VERSION "dbc-export 1 2026.26.6.5"

NS_ :

BS_:

BU_: ADSP APB APP APS APSB BB BMS CC CMP CMPD CP DAS DI DIF DIR DPB EPAS3P EPAS3S EPASTP EPASTS EPBL EPBR ESP EVSE FC GTW HCML HCMR HVP IBST ICR IDB LS OCS1P PARK PCS PCS2 PM PMF PMR PNCD PTC RADC RCM RCM2 RCM3 RCU SCCM SCM SCS SDCR TAS TCU TCU2 TPMS TRCM UI UIS UMC USM V2G VC VCBATT VCBATT0 VCBATT1 VCBATT2 VCCC VCFRONT VCFRONT1 VCFRONT2 VCLEFT VCRIGHT VCSEAT2L VCSEAT2R VCSEC VEH

BO_ 861 IBST_alertMatrix: 8 IBST
 SG_ IBST_matrixIndex M : 0|4@1+ (1,0) [0|15] "" Vector__XXX
 SG_ IBST_a001_microSupplyError m0 : 4|1@1+ (1,0) [0|1] "" Vector__XXX
 SG_ IBST_a002_HWBISTError m0 : 5|1@1+ (1,0) [0|1] "" Vector__XXX
 SG_ IBST_a003_RAMFault m0 : 6|1@1+ (1,0) [0|1] "" Vector__XXX
 SG_ IBST_a004_flashFault m0 : 7|1@1+ (1,0) [0|1] "" Vector__XXX
 SG_ IBST_a005_microSafetyFault m0 : 8|1@1+ (1,0) [0|1] "" Vector__XXX
 SG_ IBST_a006_microSafetyLogicFault m0 : 9|1@1+ (1,0) [0|1] "" Vector__XXX
 SG_ IBST_a007_RBCPUException m0 : 10|1@1+ (1,0) [0|1] "" Vector__XXX
 SG_ IBST_a008_stackOverUnderFlow m0 : 11|1@1+ (1,0) [0|1] "" Vector__XXX
 SG_ IBST_a009_systemErrorHook m0 : 12|1@1+ (1,0) [0|1] "" Vector__XXX
 SG_ IBST_a010_OSErrorHook m0 : 13|1@1+ (1,0) [0|1] "" Vector__XXX
 SG_ IBST_a011_systemTaskOverRun m0 : 14|1@1+ (1,0) [0|1] "" Vector__XXX
 SG_ IBST_a012_OSTaskSchemeError m0 : 15|1@1+ (1,0) [0|1] "" Vector__XXX
 SG_ IBST_a013_systemTaskJitter m0 : 16|1@1+ (1,0) [0|1] "" Vector__XXX
 SG_ IBST_a014_DMATransferError m0 : 17|1@1+ (1,0) [0|1] "" Vector__XXX
 SG_ IBST_a015_asicOscillatorError m0 : 18|1@1+ (1,0) [0|1] "" Vector__XXX
 SG_ IBST_a016_RBBLMShaftShiftError m0 : 19|1@1+ (1,0) [0|1] "" Vector__XXX
 SG_ IBST_a017_assertionFault m0 : 20|1@1+ (1,0) [0|1] "" Vector__XXX
 SG_ IBST_a018_unsupportedHW m0 : 21|1@1+ (1,0) [0|1] "" Vector__XXX
 SG_ IBST_a019_supplyASICInitFault m0 : 22|1@1+ (1,0) [0|1] "" Vector__XXX
 SG_ IBST_a020_VPREU5VOutOfRange m0 : 23|1@1+ (1,0) [0|1] "" Vector__XXX
 SG_ IBST_a021_IREFOutOfRange m0 : 24|1@1+ (1,0) [0|1] "" Vector__XXX
 SG_ IBST_a022_U5VTestFault m0 : 25|1@1+ (1,0) [0|1] "" Vector__XXX
 SG_ IBST_a023_U5VOutOfRange m0 : 26|1@1+ (1,0) [0|1] "" Vector__XXX
 SG_ IBST_a024_chargePumpFault m0 : 27|1@1+ (1,0) [0|1] "" Vector__XXX
 SG_ IBST_a025_ecuClockTestFault m0 : 28|1@1+ (1,0) [0|1] "" Vector__XXX
 SG_ IBST_a026_ecuBistCmdTestFault m0 : 29|1@1+ (1,0) [0|1] "" Vector__XXX
 SG_ IBST_a027_ecuFastWdTestFault m0 : 30|1@1+ (1,0) [0|1] "" Vector__XXX
 SG_ IBST_a028_ecuBistFaultCtrFault m0 : 31|1@1+ (1,0) [0|1] "" Vector__XXX
 SG_ IBST_a029_ecuErrpinCounterFault m0 : 32|1@1+ (1,0) [0|1] "" Vector__XXX
 SG_ IBST_a030_ecuEnableElLowFault m0 : 33|1@1+ (1,0) [0|1] "" Vector__XXX
 SG_ IBST_a031_decoupleBitTestFault m0 : 34|1@1+ (1,0) [0|1] "" Vector__XXX
 SG_ IBST_a032_ecuEnableElHighFault m0 : 35|1@1+ (1,0) [0|1] "" Vector__XXX
 SG_ IBST_a033_ecuWdStartuptestFault m0 : 36|1@1+ (1,0) [0|1] "" Vector__XXX
 SG_ IBST_a034_ecuEnableHyHighFault m0 : 37|1@1+ (1,0) [0|1] "" Vector__XXX
 SG_ IBST_a035_ecuEnableHyLowFault m0 : 38|1@1+ (1,0) [0|1] "" Vector__XXX
 SG_ IBST_a036_MRGPathTestFault m0 : 39|1@1+ (1,0) [0|1] "" Vector__XXX
 SG_ IBST_a037_ecuWdSContinuousError m0 : 40|1@1+ (1,0) [0|1] "" Vector__XXX
 SG_ IBST_a038_ecuEnContinuousError m0 : 41|1@1+ (1,0) [0|1] "" Vector__XXX
 SG_ IBST_a039_GTMRefFrequencyError m0 : 42|1@1+ (1,0) [0|1] "" Vector__XXX
 SG_ IBST_a040_GTMTbuMonError m0 : 43|1@1+ (1,0) [0|1] "" Vector__XXX
 SG_ IBST_a041_micAsicClkInError m0 : 44|1@1+ (1,0) [0|1] "" Vector__XXX
 SG_ IBST_a042_micAsicInitTestError m0 : 45|1@1+ (1,0) [0|1] "" Vector__XXX
 SG_ IBST_a043_micSpiTransferError m0 : 46|1@1+ (1,0) [0|1] "" Vector__XXX
 SG_ IBST_a044_NvMEepromWIP m0 : 47|1@1+ (1,0) [0|1] "" Vector__XXX
 SG_ IBST_a045_WdhAsicWdErrorCntStuck m0 : 48|1@1+ (1,0) [0|1] "" Vector__XXX
 SG_ IBST_a046_WdhAsicWdErrorCntLimit m0 : 49|1@1+ (1,0) [0|1] "" Vector__XXX
 SG_ IBST_a047_WdhAsicWdCmdMissing m0 : 50|1@1+ (1,0) [0|1] "" Vector__XXX
 SG_ IBST_a048_WdhSwBistConCnt m0 : 51|1@1+ (1,0) [0|1] "" Vector__XXX
 SG_ IBST_a049_WdhTaskMonConCnt m0 : 52|1@1+ (1,0) [0|1] "" Vector__XXX
 SG_ IBST_a050_VPreExternalFeeding m0 : 53|1@1+ (1,0) [0|1] "" Vector__XXX
 SG_ IBST_a051_ecuBandgap m0 : 54|1@1+ (1,0) [0|1] "" Vector__XXX
 SG_ IBST_a052_AdcPinTest m0 : 55|1@1+ (1,0) [0|1] "" Vector__XXX
 SG_ IBST_a053_AdcSelftestC5P m0 : 56|1@1+ (1,0) [0|1] "" Vector__XXX
 SG_ IBST_a054_AdcPeripheralFault m0 : 57|1@1+ (1,0) [0|1] "" Vector__XXX
 SG_ IBST_a055_UB6SupplyPathFault m0 : 58|1@1+ (1,0) [0|1] "" Vector__XXX
 SG_ IBST_a056_UB6PlausiMonFault m0 : 59|1@1+ (1,0) [0|1] "" Vector__XXX
 SG_ IBST_a057_microRegisterFault m0 : 60|1@1+ (1,0) [0|1] "" Vector__XXX
 SG_ IBST_a058_NvMWriteCycleExceed m0 : 61|1@1+ (1,0) [0|1] "" Vector__XXX
 SG_ IBST_a059_NvMEepromSize m0 : 62|1@1+ (1,0) [0|1] "" Vector__XXX
 SG_ IBST_a060_NvMMigrationFault m0 : 63|1@1+ (1,0) [0|1] "" Vector__XXX
 SG_ IBST_a061_AswSystemTimeOut m1 : 4|1@1+ (1,0) [0|1] "" Vector__XXX
 SG_ IBST_a062_MICB6TransferError m1 : 5|1@1+ (1,0) [0|1] "" Vector__XXX
 SG_ IBST_a063_tempSens2ShortToSupply m1 : 6|1@1+ (1,0) [0|1] "" Vector__XXX
 SG_ IBST_a064_tempSens1ShortToGround m1 : 7|1@1+ (1,0) [0|1] "" Vector__XXX
 SG_ IBST_a065_tempSens2ShortToGround m1 : 8|1@1+ (1,0) [0|1] "" Vector__XXX
 SG_ IBST_a066_tempSens1ShortToSupply m1 : 9|1@1+ (1,0) [0|1] "" Vector__XXX
 SG_ IBST_a067_tempSensImplausVoltage m1 : 10|1@1+ (1,0) [0|1] "" Vector__XXX
 SG_ IBST_a068_chargePumpUndervoltage m1 : 11|1@1+ (1,0) [0|1] "" Vector__XXX
 SG_ IBST_a069_greasingRoutineFault m1 : 12|1@1+ (1,0) [0|1] "" Vector__XXX
 SG_ IBST_a070_notShutDownNvMWrite m1 : 13|1@1+ (1,0) [0|1] "" Vector__XXX
 SG_ IBST_a071_notShutDownNvMRead m1 : 14|1@1+ (1,0) [0|1] "" Vector__XXX
 SG_ IBST_a072_notShutDownRight m1 : 15|1@1+ (1,0) [0|1] "" Vector__XXX
 SG_ IBST_a073_jumpInAdjustNvMRead m1 : 16|1@1+ (1,0) [0|1] "" Vector__XXX
 SG_ IBST_a074_FindIdleDataNvMWrite m1 : 17|1@1+ (1,0) [0|1] "" Vector__XXX
 SG_ IBST_a075_FindIdleRoutineFault m1 : 18|1@1+ (1,0) [0|1] "" Vector__XXX
 SG_ IBST_a076_masterCylLengthRead m1 : 19|1@1+ (1,0) [0|1] "" Vector__XXX
 SG_ IBST_a077_runOutMotorSaturated m1 : 20|1@1+ (1,0) [0|1] "" Vector__XXX
 SG_ IBST_a078_wearOffsetCompNVMRead m1 : 21|1@1+ (1,0) [0|1] "" Vector__XXX
 SG_ IBST_a079_motorTempHighLevel1 m1 : 22|1@1+ (1,0) [0|1] "" Vector__XXX
 SG_ IBST_a080_motorTempHighLevel2 m1 : 23|1@1+ (1,0) [0|1] "" Vector__XXX
 SG_ IBST_a081_travelDeviation m1 : 24|1@1+ (1,0) [0|1] "" Vector__XXX
 SG_ IBST_a082_motorSpeedDeviation m1 : 25|1@1+ (1,0) [0|1] "" Vector__XXX
 SG_ IBST_a083_spindlePositionTooHigh m1 : 26|1@1+ (1,0) [0|1] "" Vector__XXX
 SG_ IBST_a084_CANTransceiverHWFault m1 : 27|1@1+ (1,0) [0|1] "" Vector__XXX
 SG_ IBST_a085_supplyUndervoltageLvl3 m1 : 28|1@1+ (1,0) [0|1] "" Vector__XXX
 SG_ IBST_a086_supplyOvervoltageLvl3 m1 : 29|1@1+ (1,0) [0|1] "" Vector__XXX
 SG_ IBST_a087_rotorSinOutOfRangeLow m1 : 30|1@1+ (1,0) [0|1] "" Vector__XXX
 SG_ IBST_a088_rotorCosOutOfRangeLow m1 : 31|1@1+ (1,0) [0|1] "" Vector__XXX
 SG_ IBST_a089_rotorSinOutOfRangeHigh m1 : 32|1@1+ (1,0) [0|1] "" Vector__XXX
 SG_ IBST_a090_rotorCosOutOfRangeHigh m1 : 33|1@1+ (1,0) [0|1] "" Vector__XXX
 SG_ IBST_a091_SMMOneRequestsInit m1 : 34|1@1+ (1,0) [0|1] "" Vector__XXX
 SG_ IBST_a092_systemStartTimeOut m1 : 35|1@1+ (1,0) [0|1] "" Vector__XXX
 SG_ IBST_a093_UEXSOvertemperature m1 : 36|1@1+ (1,0) [0|1] "" Vector__XXX
 SG_ IBST_a094_XPASSEchoTimeDeviation m1 : 37|1@1+ (1,0) [0|1] "" Vector__XXX
 SG_ IBST_a095_XPASSTimeOut m1 : 38|1@1+ (1,0) [0|1] "" Vector__XXX
 SG_ IBST_a096_bridgeDriverMonError m1 : 39|1@1+ (1,0) [0|1] "" Vector__XXX
 SG_ IBST_a097_bridgeDriverError m1 : 40|1@1+ (1,0) [0|1] "" Vector__XXX
 SG_ IBST_a098_bridgeShortedPhase m1 : 41|1@1+ (1,0) [0|1] "" Vector__XXX
 SG_ IBST_a099_bridgeSwitchInitError m1 : 42|1@1+ (1,0) [0|1] "" Vector__XXX
 SG_ IBST_a100_current2OffsetHigh m1 : 43|1@1+ (1,0) [0|1] "" Vector__XXX
 SG_ IBST_a101_current2OffsetLow m1 : 44|1@1+ (1,0) [0|1] "" Vector__XXX
 SG_ IBST_a102_current1OffsetHigh m1 : 45|1@1+ (1,0) [0|1] "" Vector__XXX
 SG_ IBST_a103_current1OffsetLow m1 : 46|1@1+ (1,0) [0|1] "" Vector__XXX
 SG_ IBST_a104_bridgeDriverShort m1 : 47|1@1+ (1,0) [0|1] "" Vector__XXX
 SG_ IBST_a105_LiPSUndervoltage m1 : 48|1@1+ (1,0) [0|1] "" Vector__XXX
 SG_ IBST_a106_LiPS5VSupply m1 : 49|1@1+ (1,0) [0|1] "" Vector__XXX
 SG_ IBST_a107_LiPS2PwmLineHigh m1 : 50|1@1+ (1,0) [0|1] "" Vector__XXX
 SG_ IBST_a108_LiPS2PwmLineLow m1 : 51|1@1+ (1,0) [0|1] "" Vector__XXX
 SG_ IBST_a109_LiPS2PwmTransmission m1 : 52|1@1+ (1,0) [0|1] "" Vector__XXX
 SG_ IBST_a110_LiPS1SentLineHigh m1 : 53|1@1+ (1,0) [0|1] "" Vector__XXX
 SG_ IBST_a111_LiPS1SentLineLow m1 : 54|1@1+ (1,0) [0|1] "" Vector__XXX
 SG_ IBST_a112_LiPS1SentTransmission m1 : 55|1@1+ (1,0) [0|1] "" Vector__XXX
 SG_ IBST_a113_LiPS1SentSensor m1 : 56|1@1+ (1,0) [0|1] "" Vector__XXX
 SG_ IBST_a114_partyBusOff m1 : 57|1@1+ (1,0) [0|1] "" Vector__XXX
 SG_ IBST_a115_chassisBusOff m1 : 58|1@1+ (1,0) [0|1] "" Vector__XXX
 SG_ IBST_a116_supplyUndervoltageLvl2 m1 : 59|1@1+ (1,0) [0|1] "" Vector__XXX
 SG_ IBST_a117_supplyOvervoltageLvl2 m1 : 60|1@1+ (1,0) [0|1] "" Vector__XXX
 SG_ IBST_a118_RPSNvMReadFault m1 : 61|1@1+ (1,0) [0|1] "" Vector__XXX
 SG_ IBST_a119_RPSWrongCalibData m1 : 62|1@1+ (1,0) [0|1] "" Vector__XXX
 SG_ IBST_a120_RPSVectorRangeHigh m1 : 63|1@1+ (1,0) [0|1] "" Vector__XXX
 SG_ IBST_a121_RPSVectorRangeLow m2 : 4|1@1+ (1,0) [0|1] "" Vector__XXX
 SG_ IBST_a122_RPSVectorOscillating m2 : 5|1@1+ (1,0) [0|1] "" Vector__XXX
 SG_ IBST_a123_bridgeDriverUnavail m2 : 6|1@1+ (1,0) [0|1] "" Vector__XXX
 SG_ IBST_a124_OBDCurrent1OORHigh m2 : 7|1@1+ (1,0) [0|1] "" Vector__XXX
 SG_ IBST_a125_OBDCurrent2OORHigh m2 : 8|1@1+ (1,0) [0|1] "" Vector__XXX
 SG_ IBST_a126_OBDCurrent1OORLow m2 : 9|1@1+ (1,0) [0|1] "" Vector__XXX
 SG_ IBST_a127_OBDCurrent2OORLow m2 : 10|1@1+ (1,0) [0|1] "" Vector__XXX
 SG_ IBST_a128_BLMMuxerTimeoutError m2 : 11|1@1+ (1,0) [0|1] "" Vector__XXX
 SG_ IBST_a129_loadDumpOnFSLTest m2 : 12|1@1+ (1,0) [0|1] "" Vector__XXX
 SG_ IBST_a130_DTSFunctionalRangeLow m2 : 13|1@1+ (1,0) [0|1] "" Vector__XXX
 SG_ IBST_a131_DTSFunctionalRangeHigh m2 : 14|1@1+ (1,0) [0|1] "" Vector__XXX
 SG_ IBST_a132_DTSPlausiCheck1vs2 m2 : 15|1@1+ (1,0) [0|1] "" Vector__XXX
 SG_ IBST_a133_DTSOffsetTooLow m2 : 16|1@1+ (1,0) [0|1] "" Vector__XXX
 SG_ IBST_a134_DTSOffsetTooHigh m2 : 17|1@1+ (1,0) [0|1] "" Vector__XXX
 SG_ IBST_a135_ESPparty1DLC m2 : 18|1@1+ (1,0) [0|1] "" Vector__XXX
 SG_ IBST_a136_ESPparty1Timeout m2 : 19|1@1+ (1,0) [0|1] "" Vector__XXX
 SG_ IBST_a137_ESPparty1Checksum m2 : 20|1@1+ (1,0) [0|1] "" Vector__XXX
 SG_ IBST_a138_ESPparty1Counter m2 : 21|1@1+ (1,0) [0|1] "" Vector__XXX
 SG_ IBST_a139_ESPparty2DLC m2 : 22|1@1+ (1,0) [0|1] "" Vector__XXX
 SG_ IBST_a140_ESPparty2Timeout m2 : 23|1@1+ (1,0) [0|1] "" Vector__XXX
 SG_ IBST_a141_ESPparty2Checksum m2 : 24|1@1+ (1,0) [0|1] "" Vector__XXX
 SG_ IBST_a142_ESPparty2Counter m2 : 25|1@1+ (1,0) [0|1] "" Vector__XXX
 SG_ IBST_a143_ESPparty3DLC m2 : 26|1@1+ (1,0) [0|1] "" Vector__XXX
 SG_ IBST_a144_ESPparty3Timeout m2 : 27|1@1+ (1,0) [0|1] "" Vector__XXX
 SG_ IBST_a145_ESPparty3Checksum m2 : 28|1@1+ (1,0) [0|1] "" Vector__XXX
 SG_ IBST_a146_ESPparty3Counter m2 : 29|1@1+ (1,0) [0|1] "" Vector__XXX
 SG_ IBST_a147_PSCMotorSizeReadFault m2 : 30|1@1+ (1,0) [0|1] "" Vector__XXX
 SG_ IBST_a148_MLIGainMechReadFault m2 : 31|1@1+ (1,0) [0|1] "" Vector__XXX
 SG_ IBST_a149_MLITMCAreaReadFault m2 : 32|1@1+ (1,0) [0|1] "" Vector__XXX
 SG_ IBST_a150_motorTestFault m2 : 33|1@1+ (1,0) [0|1] "" Vector__XXX
 SG_ IBST_a151_PSCGearRatioReadFault m2 : 34|1@1+ (1,0) [0|1] "" Vector__XXX
 SG_ IBST_a152_PSCVoltageImplausible m2 : 35|1@1+ (1,0) [0|1] "" Vector__XXX
 SG_ IBST_a153_unused m2 : 36|1@1+ (1,0) [0|1] "" Vector__XXX
 SG_ IBST_a154_unused m2 : 37|1@1+ (1,0) [0|1] "" Vector__XXX
 SG_ IBST_a155_supplyUndervoltageLvl1 m2 : 38|1@1+ (1,0) [0|1] "" Vector__XXX
 SG_ IBST_a156_supplyOvervoltageLvl1 m2 : 39|1@1+ (1,0) [0|1] "" Vector__XXX
 SG_ IBST_a157_masterCylPressInvalid m2 : 40|1@1+ (1,0) [0|1] "" Vector__XXX
 SG_ IBST_a158_DTSOffsHighSuspicious m2 : 41|1@1+ (1,0) [0|1] "" Vector__XXX
 SG_ IBST_a159_FindIdleNvMReadError m2 : 42|1@1+ (1,0) [0|1] "" Vector__XXX
 SG_ IBST_a160_DTSIDTimeOut m2 : 43|1@1+ (1,0) [0|1] "" Vector__XXX
 SG_ IBST_a161_powerPackMismatch m2 : 44|1@1+ (1,0) [0|1] "" Vector__XXX
 SG_ IBST_a162_idlePosNotDetected m2 : 45|1@1+ (1,0) [0|1] "" Vector__XXX
 SG_ IBST_a163_ESPpEstMaxInvalid m2 : 46|1@1+ (1,0) [0|1] "" Vector__XXX
 SG_ IBST_a164_ESPVehicleSpeedInvalid m2 : 47|1@1+ (1,0) [0|1] "" Vector__XXX
 SG_ IBST_a165_ESPpForceBlendInvalid m2 : 48|1@1+ (1,0) [0|1] "" Vector__XXX
 SG_ IBST_a166_ESPpMcVirtualInvalid m2 : 49|1@1+ (1,0) [0|1] "" Vector__XXX
 SG_ IBST_a167_ESPqTargetExterInvalid m2 : 50|1@1+ (1,0) [0|1] "" Vector__XXX
 SG_ IBST_a168_CANOvervoltage m2 : 51|1@1+ (1,0) [0|1] "" Vector__XXX
 SG_ IBST_a169_CANUndervoltage m2 : 52|1@1+ (1,0) [0|1] "" Vector__XXX
 SG_ IBST_a170_LVPowerStateTimeout m2 : 53|1@1+ (1,0) [0|1] "" Vector__XXX
 SG_ IBST_a171_LVPowerStateChecksum m2 : 54|1@1+ (1,0) [0|1] "" Vector__XXX
 SG_ IBST_a172_LVPowerStateDLC m2 : 55|1@1+ (1,0) [0|1] "" Vector__XXX
 SG_ IBST_a173_LVPowerStateCounter m2 : 56|1@1+ (1,0) [0|1] "" Vector__XXX
 SG_ IBST_a174_LVOffStateInvalid m2 : 57|1@1+ (1,0) [0|1] "" Vector__XXX
 SG_ IBST_a175_LVGoingDownInvalid m2 : 58|1@1+ (1,0) [0|1] "" Vector__XXX
 SG_ IBST_a176_blockedPedalDetected m2 : 59|1@1+ (1,0) [0|1] "" Vector__XXX
 SG_ IBST_a177_EPBLsystemStatusMIA m2 : 60|1@1+ (1,0) [0|1] "" Vector__XXX
 SG_ IBST_a178_EPBRsystemStatusMIA m2 : 61|1@1+ (1,0) [0|1] "" Vector__XXX
 SG_ IBST_a179_VCLEFTepbmStatusMIA m2 : 62|1@1+ (1,0) [0|1] "" Vector__XXX
 SG_ IBST_a180_VCRIGHTepbmStatusMIA m2 : 63|1@1+ (1,0) [0|1] "" Vector__XXX
 SG_ IBST_a181_DIchassisControlDLC m3 : 4|1@1+ (1,0) [0|1] "" Vector__XXX
 SG_ IBST_a182_DIchassisControlTimeou m3 : 5|1@1+ (1,0) [0|1] "" Vector__XXX
 SG_ IBST_a183_DIchassisControlChecks m3 : 6|1@1+ (1,0) [0|1] "" Vector__XXX
 SG_ IBST_a184_DIchassisControlCounte m3 : 7|1@1+ (1,0) [0|1] "" Vector__XXX
 SG_ IBST_a185_rightBusOff m3 : 8|1@1+ (1,0) [0|1] "" Vector__XXX
 SG_ IBST_a186_rightBusPassive m3 : 9|1@1+ (1,0) [0|1] "" Vector__XXX
 SG_ IBST_a187_brakeBusOff m3 : 10|1@1+ (1,0) [0|1] "" Vector__XXX
 SG_ IBST_a188_brakeBusPassive m3 : 11|1@1+ (1,0) [0|1] "" Vector__XXX
 SG_ IBST_a189_rightVCLVPowerStateTim m3 : 12|1@1+ (1,0) [0|1] "" Vector__XXX
 SG_ IBST_a190_rightVCLVPowerStateDLC m3 : 13|1@1+ (1,0) [0|1] "" Vector__XXX
 SG_ IBST_a191_rightVCLVPowerStateChe m3 : 14|1@1+ (1,0) [0|1] "" Vector__XXX
 SG_ IBST_a192_rightVCLVPowerStateCou m3 : 15|1@1+ (1,0) [0|1] "" Vector__XXX
 SG_ IBST_a193_leftVCLVPowerStateTime m3 : 16|1@1+ (1,0) [0|1] "" Vector__XXX
 SG_ IBST_a194_leftVCLVPowerStateChec m3 : 17|1@1+ (1,0) [0|1] "" Vector__XXX
 SG_ IBST_a195_leftVCLVPowerStateDLC m3 : 18|1@1+ (1,0) [0|1] "" Vector__XXX
 SG_ IBST_a196_leftVCLVPowerStateCoun m3 : 19|1@1+ (1,0) [0|1] "" Vector__XXX
 SG_ IBST_a197_brakeLatencyReductionA m3 : 20|1@1+ (1,0) [0|1] "" Vector__XXX
 SG_ IBST_a198_aesActive m3 : 21|1@1+ (1,0) [0|1] "" Vector__XXX
 SG_ IBST_a199_undefinedAlertDetected m3 : 22|1@1+ (1,0) [0|1] "" Vector__XXX
 SG_ IBST_a200_aesFault m3 : 23|1@1+ (1,0) [0|1] "" Vector__XXX
 SG_ IBST_a201_EGGREAR1wheelSpeedsRea m3 : 24|1@1+ (1,0) [0|1] "" Vector__XXX
 SG_ IBST_a202_EGGREAR1wheelSpeedsRea m3 : 25|1@1+ (1,0) [0|1] "" Vector__XXX
 SG_ IBST_a203_EGGREAR1wheelSpeedsRea m3 : 26|1@1+ (1,0) [0|1] "" Vector__XXX
 SG_ IBST_a204_EGGREAR1wheelSpeedsRea m3 : 27|1@1+ (1,0) [0|1] "" Vector__XXX
 SG_ IBST_a205_EGGRIGHT1wheelSpeedsFr m3 : 28|1@1+ (1,0) [0|1] "" Vector__XXX
 SG_ IBST_a206_EGGRIGHT1wheelSpeedsFr m3 : 29|1@1+ (1,0) [0|1] "" Vector__XXX
 SG_ IBST_a207_EGGRIGHT1wheelSpeedsFr m3 : 30|1@1+ (1,0) [0|1] "" Vector__XXX
 SG_ IBST_a208_EGGRIGHT1wheelSpeedsFr m3 : 31|1@1+ (1,0) [0|1] "" Vector__XXX
 SG_ IBST_a209_reducedBrakePowerActiv m3 : 32|1@1+ (1,0) [0|1] "" Vector__XXX
 SG_ IBST_a210_reducedBrakePowerNotAv m3 : 33|1@1+ (1,0) [0|1] "" Vector__XXX
 SG_ IBST_a211_DETReportError m3 : 34|1@1+ (1,0) [0|1] "" Vector__XXX
 SG_ IBST_a212_infoFailureWrongCUBASH m3 : 35|1@1+ (1,0) [0|1] "" Vector__XXX
 SG_ IBST_a213_PDURouterinitializatio m3 : 36|1@1+ (1,0) [0|1] "" Vector__XXX
 SG_ IBST_a214_LossOfPDUInstanceDetec m3 : 37|1@1+ (1,0) [0|1] "" Vector__XXX
 SG_ IBST_a215_UnsupportedSeriesHWDet m3 : 38|1@1+ (1,0) [0|1] "" Vector__XXX
 SG_ IBST_a216_AsicMalfunctionDetecte m3 : 39|1@1+ (1,0) [0|1] "" Vector__XXX
 SG_ IBST_a217_AsicTrimmingNotComplet m3 : 40|1@1+ (1,0) [0|1] "" Vector__XXX
 SG_ IBST_a218_uCSafetyNotificationGR m3 : 41|1@1+ (1,0) [0|1] "" Vector__XXX
 SG_ IBST_a219_uCSafetyNotification m3 : 42|1@1+ (1,0) [0|1] "" Vector__XXX
 SG_ IBST_a220_ASICOvercurrentOnGPIO2 m3 : 43|1@1+ (1,0) [0|1] "" Vector__XXX
 SG_ IBST_a221_ASICOvercurrentOnGPIO2 m3 : 44|1@1+ (1,0) [0|1] "" Vector__XXX
 SG_ IBST_a222_ASICOvercurrentOnGPIO5 m3 : 45|1@1+ (1,0) [0|1] "" Vector__XXX
 SG_ IBST_a223_ASICOvercurrentOnGPIO5 m3 : 46|1@1+ (1,0) [0|1] "" Vector__XXX
 SG_ IBST_a224_ASICOvercurrentOnGPIO5 m3 : 47|1@1+ (1,0) [0|1] "" Vector__XXX
 SG_ IBST_a225_ASICOvercurrentOnGPIO5 m3 : 48|1@1+ (1,0) [0|1] "" Vector__XXX
 SG_ IBST_a226_ASICOvercurrentOnWRHS m3 : 49|1@1+ (1,0) [0|1] "" Vector__XXX
 SG_ IBST_a227_wakeRequestMismatchDet m3 : 50|1@1+ (1,0) [0|1] "" Vector__XXX
 SG_ IBST_a228_BlockedPedalDetectedDu m3 : 51|1@1+ (1,0) [0|1] "" Vector__XXX
 SG_ IBST_a229_BlockedPedalDetected m3 : 52|1@1+ (1,0) [0|1] "" Vector__XXX
 SG_ IBST_a230_DTS2FunctionalRangeLow m3 : 53|1@1+ (1,0) [0|1] "" Vector__XXX
 SG_ IBST_a231_DTS2FunctionalRangeLow m3 : 54|1@1+ (1,0) [0|1] "" Vector__XXX
 SG_ IBST_a232_PostAssemblyRoutineFai m3 : 55|1@1+ (1,0) [0|1] "" Vector__XXX
 SG_ IBST_a233_ReferenceRunAbortByECU m3 : 56|1@1+ (1,0) [0|1] "" Vector__XXX
 SG_ IBST_a234_LiPSOutOfRangeHigh m3 : 57|1@1+ (1,0) [0|1] "" Vector__XXX
 SG_ IBST_a235_LiPSOutOfRangeLow m3 : 58|1@1+ (1,0) [0|1] "" Vector__XXX
 SG_ IBST_a246_DASredundantBrakingCon m4 : 9|1@1+ (1,0) [0|1] "" Vector__XXX
 SG_ IBST_a247_DASredundantBrakingCon m4 : 10|1@1+ (1,0) [0|1] "" Vector__XXX
 SG_ IBST_a248_DASredundantBrakingCon m4 : 11|1@1+ (1,0) [0|1] "" Vector__XXX
 SG_ IBST_a249_DASredundantBrakingCon m4 : 12|1@1+ (1,0) [0|1] "" Vector__XXX
 SG_ IBST_a250_DASredundantBrakingCon m4 : 13|1@1+ (1,0) [0|1] "" Vector__XXX
 SG_ IBST_a251_DASredundantBrakingCon m4 : 14|1@1+ (1,0) [0|1] "" Vector__XXX
 SG_ IBST_a252_DASredundantBrakingCon m4 : 15|1@1+ (1,0) [0|1] "" Vector__XXX
 SG_ IBST_a253_DASredundantBrakingCon m4 : 16|1@1+ (1,0) [0|1] "" Vector__XXX
 SG_ IBST_a254_DIlocStatus2Checksum m4 : 17|1@1+ (1,0) [0|1] "" Vector__XXX
 SG_ IBST_a255_DIlocStatus2Counter m4 : 18|1@1+ (1,0) [0|1] "" Vector__XXX
 SG_ IBST_a256_DIlocStatus2DLC m4 : 19|1@1+ (1,0) [0|1] "" Vector__XXX
 SG_ IBST_a257_DIlocStatus2Timeout m4 : 20|1@1+ (1,0) [0|1] "" Vector__XXX
 SG_ IBST_a258_standaloneEBRActive m4 : 21|1@1+ (1,0) [0|1] "" Vector__XXX
 SG_ IBST_a259_EMCMain11Checksum m4 : 22|1@1+ (1,0) [0|1] "" Vector__XXX
 SG_ IBST_a260_EMCMain11Counter m4 : 23|1@1+ (1,0) [0|1] "" Vector__XXX
 SG_ IBST_a261_EMCMain11DLC m4 : 24|1@1+ (1,0) [0|1] "" Vector__XXX
 SG_ IBST_a262_EMCMain11Timeout m4 : 25|1@1+ (1,0) [0|1] "" Vector__XXX
 SG_ IBST_a263_EMCMain21Checksum m4 : 26|1@1+ (1,0) [0|1] "" Vector__XXX
 SG_ IBST_a264_EMCMain21Counter m4 : 27|1@1+ (1,0) [0|1] "" Vector__XXX
 SG_ IBST_a265_EMCMain21DLC m4 : 28|1@1+ (1,0) [0|1] "" Vector__XXX
 SG_ IBST_a266_EMCMain21Timeout m4 : 29|1@1+ (1,0) [0|1] "" Vector__XXX

BO_ 813 IBST_info: 8 IBST
 SG_ IBST_infoIndex M : 0|8@1+ (1,0) [0|255] "" Vector__XXX
 SG_ IBST_infoBuildType m10 : 8|8@1+ (1,0) [0|255] "" Vector__XXX
 SG_ IBST_infoComponentID m10 : 55|16@0+ (1,0) [0|65535] "" Vector__XXX
 SG_ IBST_infoPcbaID m11 : 16|8@1+ (1,0) [0|255] "" Vector__XXX
 SG_ IBST_infoAssemblyID m11 : 24|8@1+ (1,0) [0|255] "" Vector__XXX
 SG_ IBST_infoUsageID m11 : 32|16@1+ (1,0) [0|65535] "" Vector__XXX
 SG_ IBST_infoSubUsageID m11 : 48|16@1+ (1,0) [0|65535] "" Vector__XXX
 SG_ IBST_infoApplicationCRC m13 : 32|32@1+ (1,0) [0|4294967295] "" Vector__XXX
 SG_ IBST_infoBootUdsProtoVersion m20 : 8|8@1+ (1,0) [0|255] "" Vector__XXX
 SG_ IBST_infoBootloaderCRC m20 : 32|32@1+ (1,0) [0|4294967295] "" Vector__XXX
 SG_ IBST_infoVariantCRC m22 : 32|32@1+ (1,0) [0|4294967295] "" Vector__XXX

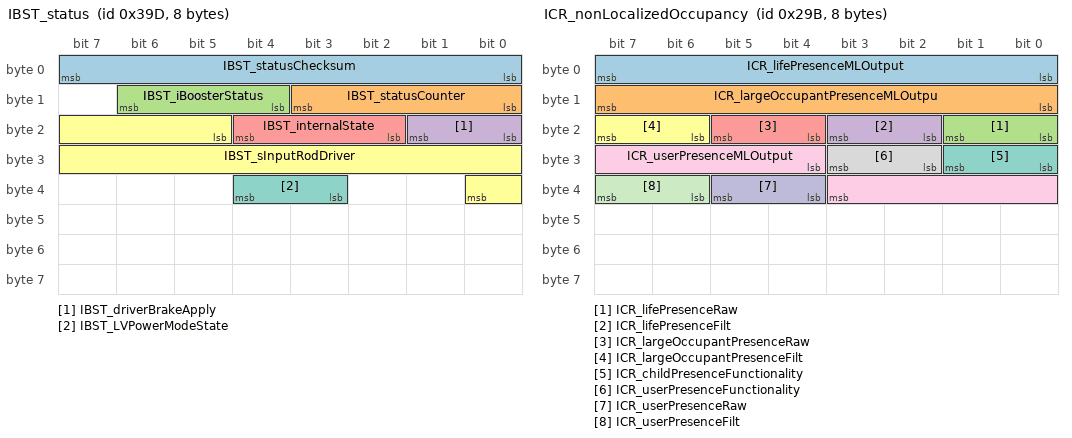
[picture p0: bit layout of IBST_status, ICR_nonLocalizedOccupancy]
BO_ 925 IBST_status: 8 IBST
 SG_ IBST_statusChecksum : 0|8@1+ (1,0) [0|255] "" Vector__XXX
 SG_ IBST_statusCounter : 8|4@1+ (1,0) [0|15] "" Vector__XXX
 SG_ IBST_iBoosterStatus : 12|3@1+ (1,0) [0|7] "" Vector__XXX
 SG_ IBST_driverBrakeApply : 16|2@1+ (1,0) [0|3] "" Vector__XXX
 SG_ IBST_internalState : 18|3@1+ (1,0) [0|7] "" Vector__XXX
 SG_ IBST_sInputRodDriver : 21|12@1+ (0.015625,-5) [-5|47] "mm" Vector__XXX
 SG_ IBST_LVPowerModeState : 35|2@1+ (1,0) [0|3] "" Vector__XXX

BO_ 1208 ICR_alertLog: 8 ICR
 SG_ ICR_alertID M : 0|8@1+ (1,0) [0|255] "" Vector__XXX
 SG_ ICR_alertState : 15|1@1+ (1,0) [0|1] "" Vector__XXX
 SG_ ICR_a001_watchdogTaskAppDPM m1 : 16|1@1+ (1,0) [0|1] "" Vector__XXX
 SG_ ICR_a001_watchdogTaskMMWControl m1 : 17|1@1+ (1,0) [0|1] "" Vector__XXX
 SG_ ICR_a001_watchdogTaskSentinelInt m1 : 18|1@1+ (1,0) [0|1] "" Vector__XXX
 SG_ ICR_a001_watchdogTaskSentinelMod m1 : 19|1@1+ (1,0) [0|1] "" Vector__XXX
 SG_ ICR_a001_watchdogTaskComTXRAD m1 : 20|1@1+ (1,0) [0|1] "" Vector__XXX
 SG_ ICR_a001_watchdogTaskComRX m1 : 21|1@1+ (1,0) [0|1] "" Vector__XXX
 SG_ ICR_a001_watchdogTaskComTXVEH m1 : 22|1@1+ (1,0) [0|1] "" Vector__XXX
 SG_ ICR_a001_watchdogTaskComUDS m1 : 23|1@1+ (1,0) [0|1] "" Vector__XXX
 SG_ ICR_a001_watchdogTaskCommonError m1 : 24|1@1+ (1,0) [0|1] "" Vector__XXX
 SG_ ICR_a001_watchdogTaskUARTLog m1 : 25|1@1+ (1,0) [0|1] "" Vector__XXX
 SG_ ICR_a001_watchdogTaskDataDump m1 : 26|1@1+ (1,0) [0|1] "" Vector__XXX
 SG_ ICR_a001_watchdogRTOSAppRun10MS m1 : 27|1@1+ (1,0) [0|1] "" Vector__XXX
 SG_ ICR_a001_watchdogRTOSAppRun1MS m1 : 28|1@1+ (1,0) [0|1] "" Vector__XXX
 SG_ ICR_a001_InternalWatchdog m1 : 29|1@1+ (1,0) [0|1] "" Vector__XXX
 SG_ ICR_a015_NVMMMemOverflow m15 : 16|1@1+ (1,0) [0|1] "" Vector__XXX
 SG_ ICR_a015_NVMMFilesystemError m15 : 17|1@1+ (1,0) [0|1] "" Vector__XXX
 SG_ ICR_a015_NVMMRecordIDError m15 : 18|1@1+ (1,0) [0|1] "" Vector__XXX
 SG_ ICR_a059_voltageDrop m59 : 16|12@1+ (0.005443676,0) [0|22.29185322] "" Vector__XXX
 SG_ ICR_a059_resistanceEstimate m59 : 28|12@1+ (0.00244,0) [0|9.9918] "" Vector__XXX
 SG_ ICR_a059_current m59 : 40|12@1+ (0.05,0) [0|204.75] "" Vector__XXX
 SG_ ICR_a063_switchChannel m63 : 16|8@1+ (1,0) [0|255] "" Vector__XXX
 SG_ ICR_a063_switchType m63 : 24|8@1+ (1,0) [0|255] "" Vector__XXX
 SG_ ICR_a063_ADCVoltage m63 : 32|8@1+ (0.025,0) [0|6.375] "" Vector__XXX
 SG_ ICR_a063_disconnected m63 : 40|1@1+ (1,0) [0|1] "" Vector__XXX
 SG_ ICR_a063_indeterminate m63 : 41|1@1+ (1,0) [0|1] "" Vector__XXX
 SG_ ICR_a063_stuckActive m63 : 42|1@1+ (1,0) [0|1] "" Vector__XXX
 SG_ ICR_a063_faulted m63 : 43|1@1+ (1,0) [0|1] "" Vector__XXX
 SG_ ICR_a133_nearClutter m133 : 16|8@1- (0.2,0) [-25.6|25.4] "" Vector__XXX
 SG_ ICR_a133_farClutter m133 : 24|8@1- (0.2,0) [-25.6|25.4] "" Vector__XXX
 SG_ ICR_a137_nearClutter m137 : 16|8@1- (0.2,0) [-25.6|25.4] "" Vector__XXX
 SG_ ICR_a137_farClutter m137 : 24|8@1- (0.2,0) [-25.6|25.4] "" Vector__XXX
 SG_ ICR_a139_nearClutter m139 : 16|8@1- (0.2,0) [-25.6|25.4] "" Vector__XXX
 SG_ ICR_a139_farClutter m139 : 24|8@1- (0.2,0) [-25.6|25.4] "" Vector__XXX
 SG_ ICR_a141_pmicQualityExcursion m141 : 16|1@1+ (1,0) [0|1] "" Vector__XXX
 SG_ ICR_a141_calDataNotCalibratedOrP m141 : 17|1@1+ (1,0) [0|1] "" Vector__XXX
 SG_ ICR_a141_calDataValRXPhaseAboveM m141 : 18|1@1+ (1,0) [0|1] "" Vector__XXX
 SG_ ICR_a141_calDataValRXPhaseMissin m141 : 19|1@1+ (1,0) [0|1] "" Vector__XXX
 SG_ ICR_a141_calDataValRangeBiasAbov m141 : 20|1@1+ (1,0) [0|1] "" Vector__XXX

BO_ 2028 ICR_alertMatrix: 8 ICR
 SG_ ICR_matrixIndex M : 0|4@1+ (1,0) [0|15] "" Vector__XXX
 SG_ ICR_a001_WatchdogReset m0 : 4|1@1+ (1,0) [0|1] "" Vector__XXX
 SG_ ICR_a002_PowerLossReset m0 : 5|1@1+ (1,0) [0|1] "" Vector__XXX
 SG_ ICR_a003_SWAssertion m0 : 6|1@1+ (1,0) [0|1] "" Vector__XXX
 SG_ ICR_a005_CANTXError m0 : 8|1@1+ (1,0) [0|1] "" Vector__XXX
 SG_ ICR_a006_CANTX_cyclicError m0 : 9|1@1+ (1,0) [0|1] "" Vector__XXX
 SG_ ICR_a012_CPUReset m0 : 15|1@1+ (1,0) [0|1] "" Vector__XXX
 SG_ ICR_a013_AlertManagerFault m0 : 16|1@1+ (1,0) [0|1] "" Vector__XXX
 SG_ ICR_a015_NVMMError m0 : 18|1@1+ (1,0) [0|1] "" Vector__XXX
 SG_ ICR_a016_NVMMRecordError m0 : 19|1@1+ (1,0) [0|1] "" Vector__XXX
 SG_ ICR_a021_TaskSchedulerError m0 : 24|1@1+ (1,0) [0|1] "" Vector__XXX
 SG_ ICR_a022_TaskInitError m0 : 25|1@1+ (1,0) [0|1] "" Vector__XXX
 SG_ ICR_a029_CoreDump m0 : 32|1@1+ (1,0) [0|1] "" Vector__XXX
 SG_ ICR_a030_ECULogUploadRequest m0 : 33|1@1+ (1,0) [0|1] "" Vector__XXX
 SG_ ICR_a031_UDSActive m0 : 34|1@1+ (1,0) [0|1] "" Vector__XXX
 SG_ ICR_a041_HighCPULoad m0 : 44|1@1+ (1,0) [0|1] "" Vector__XXX
 SG_ ICR_a042_HighStackUsage m0 : 45|1@1+ (1,0) [0|1] "" Vector__XXX
 SG_ ICR_a043_Task1msError m0 : 46|1@1+ (1,0) [0|1] "" Vector__XXX
 SG_ ICR_a044_Task10msError m0 : 47|1@1+ (1,0) [0|1] "" Vector__XXX
 SG_ ICR_a045_Task100msError m0 : 48|1@1+ (1,0) [0|1] "" Vector__XXX
 SG_ ICR_a046_Task1000msError m0 : 49|1@1+ (1,0) [0|1] "" Vector__XXX
 SG_ ICR_a058_inputRHighSyncDebug m0 : 61|1@1+ (1,0) [0|1] "" Vector__XXX
 SG_ ICR_a059_inputResistanceHigh m0 : 62|1@1+ (1,0) [0|1] "" Vector__XXX
 SG_ ICR_a060_engineeringBuild m0 : 63|1@1+ (1,0) [0|1] "" Vector__XXX
 SG_ ICR_a061_XCPConnected m1 : 4|1@1+ (1,0) [0|1] "" Vector__XXX
 SG_ ICR_a062_XCPWasConnected m1 : 5|1@1+ (1,0) [0|1] "" Vector__XXX
 SG_ ICR_a063_SwitchFault m1 : 6|1@1+ (1,0) [0|1] "" Vector__XXX
 SG_ ICR_a064_busSleepReqTimeout m1 : 7|1@1+ (1,0) [0|1] "" Vector__XXX
 SG_ ICR_a133_radarBlocked m2 : 16|1@1+ (1,0) [0|1] "" Vector__XXX
 SG_ ICR_a134_radarPgood m2 : 17|1@1+ (1,0) [0|1] "" Vector__XXX
 SG_ ICR_a135_radarTxBallBreak m2 : 18|1@1+ (1,0) [0|1] "" Vector__XXX
 SG_ ICR_a136_radarHighTemperature m2 : 19|1@1+ (1,0) [0|1] "" Vector__XXX
 SG_ ICR_a137_radarBlocked m2 : 20|1@1+ (1,0) [0|1] "" Vector__XXX
 SG_ ICR_a138_DriverSideMismatch m2 : 21|1@1+ (1,0) [0|1] "" Vector__XXX
 SG_ ICR_a139_AbnormalBlockageDetecte m2 : 22|1@1+ (1,0) [0|1] "" Vector__XXX
 SG_ ICR_a140_OccupancyExceptionEncou m2 : 23|1@1+ (1,0) [0|1] "" Vector__XXX
 SG_ ICR_a141_RequiresReplacement m2 : 24|1@1+ (1,0) [0|1] "" Vector__XXX
 SG_ ICR_a142_ModeOverrideActive m2 : 25|1@1+ (1,0) [0|1] "" Vector__XXX
 SG_ ICR_a143_DSPCoreSkipped m2 : 26|1@1+ (1,0) [0|1] "" Vector__XXX
 SG_ ICR_a144_OccupancyNotificationAl m2 : 27|1@1+ (1,0) [0|1] "" Vector__XXX

BO_ 941 ICR_info: 8 ICR
 SG_ ICR_infoIndex M : 0|8@1+ (1,0) [0|255] "" Vector__XXX
 SG_ ICR_infoBuildType m10 : 8|3@1+ (1,0) [0|7] "" Vector__XXX
 SG_ ICR_infoPcbaId m11 : 32|8@1+ (1,0) [0|255] "" Vector__XXX
 SG_ ICR_infoAssemblyId m11 : 40|8@1+ (1,0) [0|255] "" Vector__XXX
 SG_ ICR_infoUsageId m11 : 48|16@1+ (1,0) [0|65535] "" Vector__XXX
 SG_ ICR_infoAppCrc m13 : 8|32@1+ (1,0) [0|4294967295] "" Vector__XXX
 SG_ ICR_infoBoardPartNumber17 m25 : 8|56@1+ (1,0) [0|7.20575940379e+16] "" Vector__XXX
 SG_ ICR_infoBoardPartNumber814 m26 : 8|56@1+ (1,0) [0|7.20575940379e+16] "" Vector__XXX
 SG_ ICR_infoBoardPartNumber1520 m27 : 8|48@1+ (1,0) [0|281474976710655] "" Vector__XXX

BO_ 667 ICR_nonLocalizedOccupancy: 8 ICR
 SG_ ICR_lifePresenceMLOutput : 0|8@1+ (0.004,0) [0|1.016] "points" Vector__XXX
 SG_ ICR_largeOccupantPresenceMLOutpu : 8|8@1+ (0.004,0) [0|1.016] "points" Vector__XXX
 SG_ ICR_lifePresenceRaw : 16|2@1+ (1,0) [0|3] "" Vector__XXX
 SG_ ICR_lifePresenceFilt : 18|2@1+ (1,0) [0|3] "" Vector__XXX
 SG_ ICR_largeOccupantPresenceRaw : 20|2@1+ (1,0) [0|3] "" Vector__XXX
 SG_ ICR_largeOccupantPresenceFilt : 22|2@1+ (1,0) [0|3] "" Vector__XXX
 SG_ ICR_childPresenceFunctionality : 24|2@1+ (1,0) [0|3] "" Vector__XXX
 SG_ ICR_userPresenceFunctionality : 26|2@1+ (1,0) [0|3] "" Vector__XXX
 SG_ ICR_userPresenceMLOutput : 28|8@1+ (0.004,0) [0|1.016] "points" Vector__XXX
 SG_ ICR_userPresenceRaw : 36|2@1+ (1,0) [0|3] "" Vector__XXX
 SG_ ICR_userPresenceFilt : 38|2@1+ (1,0) [0|3] "" Vector__XXX

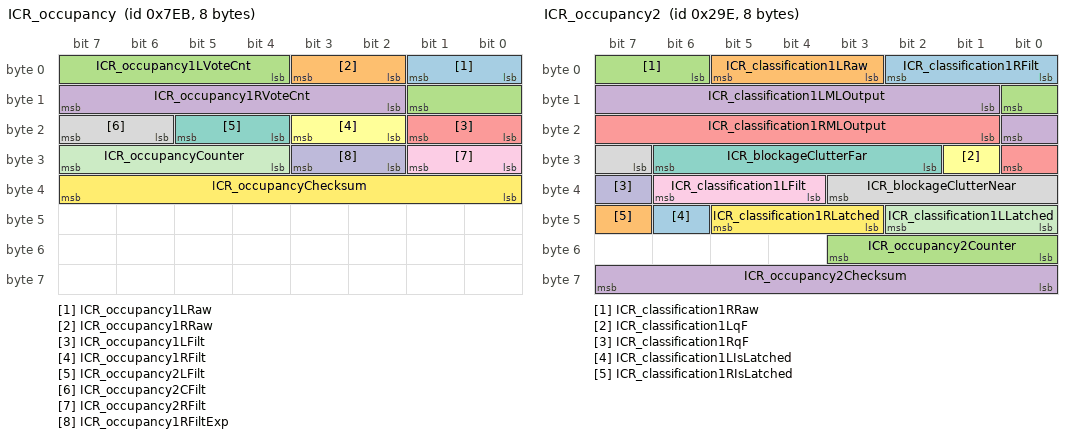
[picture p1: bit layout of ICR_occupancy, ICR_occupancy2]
BO_ 2027 ICR_occupancy: 8 ICR
 SG_ ICR_occupancy1LRaw : 0|2@1+ (1,0) [0|3] "" Vector__XXX
 SG_ ICR_occupancy1RRaw : 2|2@1+ (1,0) [0|3] "" Vector__XXX
 SG_ ICR_occupancy1LVoteCnt : 4|6@1- (1,0) [-32|31] "" Vector__XXX
 SG_ ICR_occupancy1RVoteCnt : 10|6@1- (1,0) [-32|31] "" Vector__XXX
 SG_ ICR_occupancy1LFilt : 16|2@1+ (1,0) [0|3] "" Vector__XXX
 SG_ ICR_occupancy1RFilt : 18|2@1+ (1,0) [0|3] "" Vector__XXX
 SG_ ICR_occupancy2LFilt : 20|2@1+ (1,0) [0|3] "" Vector__XXX
 SG_ ICR_occupancy2CFilt : 22|2@1+ (1,0) [0|3] "" Vector__XXX
 SG_ ICR_occupancy2RFilt : 24|2@1+ (1,0) [0|3] "" Vector__XXX
 SG_ ICR_occupancy1RFiltExp : 26|2@1+ (1,0) [0|3] "" Vector__XXX
 SG_ ICR_occupancyCounter : 28|4@1+ (1,0) [0|15] "" Vector__XXX
 SG_ ICR_occupancyChecksum : 32|8@1+ (1,0) [0|255] "" Vector__XXX

BO_ 670 ICR_occupancy2: 8 ICR
 SG_ ICR_classification1RFilt : 0|3@1+ (1,0) [0|7] "" Vector__XXX
 SG_ ICR_classification1LRaw : 3|3@1+ (1,0) [0|7] "" Vector__XXX
 SG_ ICR_classification1RRaw : 6|3@1+ (1,0) [0|7] "" Vector__XXX
 SG_ ICR_classification1LMLOutput : 9|8@1+ (0.004,0) [0|1.02] "points" Vector__XXX
 SG_ ICR_classification1RMLOutput : 17|8@1+ (0.004,0) [0|1.02] "points" Vector__XXX
 SG_ ICR_classification1LqF : 25|1@1+ (1,0) [0|1] "" Vector__XXX
 SG_ ICR_blockageClutterFar : 26|5@1- (0.5,-1.5) [-9|6] "dB" Vector__XXX
 SG_ ICR_blockageClutterNear : 31|5@1- (0.5,-1.5) [-9|6] "dB" Vector__XXX
 SG_ ICR_classification1LFilt : 36|3@1+ (1,0) [0|7] "" Vector__XXX
 SG_ ICR_classification1RqF : 39|1@1+ (1,0) [0|1] "" Vector__XXX
 SG_ ICR_classification1LLatched : 40|3@1+ (1,0) [0|7] "" Vector__XXX
 SG_ ICR_classification1RLatched : 43|3@1+ (1,0) [0|7] "" Vector__XXX
 SG_ ICR_classification1LIsLatched : 46|1@1+ (1,0) [0|1] "" Vector__XXX
 SG_ ICR_classification1RIsLatched : 47|1@1+ (1,0) [0|1] "" Vector__XXX
 SG_ ICR_occupancy2Counter : 48|4@1+ (1,0) [0|15] "" Vector__XXX
 SG_ ICR_occupancy2Checksum : 56|8@1+ (1,0) [0|255] "" Vector__XXX

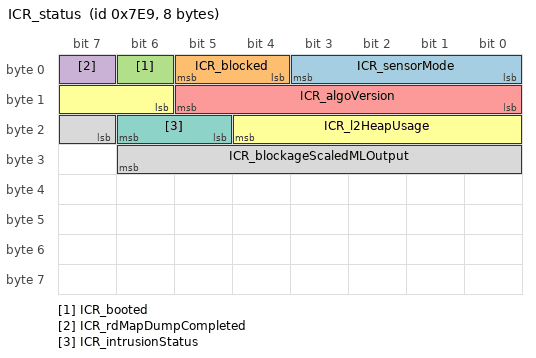
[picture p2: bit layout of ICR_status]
BO_ 2025 ICR_status: 8 ICR
 SG_ ICR_sensorMode : 0|4@1+ (1,0) [0|15] "" Vector__XXX
 SG_ ICR_blocked : 4|2@1+ (1,0) [0|3] "" Vector__XXX
 SG_ ICR_booted : 6|1@1+ (1,0) [0|1] "" Vector__XXX
 SG_ ICR_rdMapDumpCompleted : 7|1@1+ (1,0) [0|1] "" Vector__XXX
 SG_ ICR_algoVersion : 8|6@1+ (1,0) [0|63] "" Vector__XXX
 SG_ ICR_l2HeapUsage : 14|7@1+ (1,0) [0|127] "PCT" Vector__XXX
 SG_ ICR_intrusionStatus : 21|2@1+ (1,0) [0|3] "" Vector__XXX
 SG_ ICR_blockageScaledMLOutput : 23|8@1+ (0.004,0) [0|1.02] "points" Vector__XXX

BO_ 1470 IDB_alertLog: 8 IDB
 SG_ IDB_alertID M : 0|8@1+ (1,0) [0|255] "" Vector__XXX
 SG_ IDB_alertState : 15|1@1+ (1,0) [0|1] "" Vector__XXX
 SG_ IDB_a014_wheelSpeedSensorFreq m14 : 16|1@1+ (1,0) [0|1] "" Vector__XXX
 SG_ IDB_a014_wheelSpeedSensorPhase m14 : 17|1@1+ (1,0) [0|1] "" Vector__XXX
 SG_ IDB_a014_wheelSpeedSensorMisinst m14 : 18|1@1+ (1,0) [0|1] "" Vector__XXX
 SG_ IDB_a014_wheelSpeedSensorWrongEx m14 : 19|1@1+ (1,0) [0|1] "" Vector__XXX
 SG_ IDB_a014_wheelSpeedSensorSpeedJu m14 : 20|1@1+ (1,0) [0|1] "" Vector__XXX
 SG_ IDB_a014_wheelSpeedSensorSp_0001 m14 : 21|1@1+ (1,0) [0|1] "" Vector__XXX
 SG_ IDB_a014_wheelSpeedSensorAirGap m14 : 22|1@1+ (1,0) [0|1] "" Vector__XXX
 SG_ IDB_a014_wheelSpeedSensorBIST m14 : 23|1@1+ (1,0) [0|1] "" Vector__XXX
 SG_ IDB_a014_wheelSpeedSensorLeakage m14 : 24|1@1+ (1,0) [0|1] "" Vector__XXX
 SG_ IDB_a014_wheelSpeedSensorOverTem m14 : 25|1@1+ (1,0) [0|1] "" Vector__XXX
 SG_ IDB_a014_wheelSpeedSensorSh_0001 m14 : 26|1@1+ (1,0) [0|1] "" Vector__XXX
 SG_ IDB_a014_wheelSpeedSensorShortTo m14 : 27|1@1+ (1,0) [0|1] "" Vector__XXX
 SG_ IDB_a014_wheelSpeedSensorOpen m14 : 28|1@1+ (1,0) [0|1] "" Vector__XXX
 SG_ IDB_a015_wheelSpeedSensorFreq m15 : 16|1@1+ (1,0) [0|1] "" Vector__XXX
 SG_ IDB_a015_wheelSpeedSensorPhase m15 : 17|1@1+ (1,0) [0|1] "" Vector__XXX
 SG_ IDB_a015_wheelSpeedSensorMisinst m15 : 18|1@1+ (1,0) [0|1] "" Vector__XXX
 SG_ IDB_a015_wheelSpeedSensorWrongEx m15 : 19|1@1+ (1,0) [0|1] "" Vector__XXX
 SG_ IDB_a015_wheelSpeedSensorSpeedJu m15 : 20|1@1+ (1,0) [0|1] "" Vector__XXX
 SG_ IDB_a015_wheelSpeedSensorSp_0001 m15 : 21|1@1+ (1,0) [0|1] "" Vector__XXX
 SG_ IDB_a015_wheelSpeedSensorAirGap m15 : 22|1@1+ (1,0) [0|1] "" Vector__XXX
 SG_ IDB_a015_wheelSpeedSensorBIST m15 : 23|1@1+ (1,0) [0|1] "" Vector__XXX
 SG_ IDB_a015_wheelSpeedSensorLeakage m15 : 24|1@1+ (1,0) [0|1] "" Vector__XXX
 SG_ IDB_a015_wheelSpeedSensorOverTem m15 : 25|1@1+ (1,0) [0|1] "" Vector__XXX
 SG_ IDB_a015_wheelSpeedSensorSh_0001 m15 : 26|1@1+ (1,0) [0|1] "" Vector__XXX
 SG_ IDB_a015_wheelSpeedSensorShortTo m15 : 27|1@1+ (1,0) [0|1] "" Vector__XXX
 SG_ IDB_a015_wheelSpeedSensorOpen m15 : 28|1@1+ (1,0) [0|1] "" Vector__XXX
 SG_ IDB_a016_wheelSpeedSensorFreq m16 : 16|1@1+ (1,0) [0|1] "" Vector__XXX
 SG_ IDB_a016_wheelSpeedSensorPhase m16 : 17|1@1+ (1,0) [0|1] "" Vector__XXX
 SG_ IDB_a016_wheelSpeedSensorMisinst m16 : 18|1@1+ (1,0) [0|1] "" Vector__XXX
 SG_ IDB_a016_wheelSpeedSensorWrongEx m16 : 19|1@1+ (1,0) [0|1] "" Vector__XXX
 SG_ IDB_a016_wheelSpeedSensorSpeedJu m16 : 20|1@1+ (1,0) [0|1] "" Vector__XXX
 SG_ IDB_a016_wheelSpeedSensorSp_0001 m16 : 21|1@1+ (1,0) [0|1] "" Vector__XXX
 SG_ IDB_a016_wheelSpeedSensorAirGap m16 : 22|1@1+ (1,0) [0|1] "" Vector__XXX
 SG_ IDB_a016_wheelSpeedSensorBIST m16 : 23|1@1+ (1,0) [0|1] "" Vector__XXX
 SG_ IDB_a016_wheelSpeedSensorLeakage m16 : 24|1@1+ (1,0) [0|1] "" Vector__XXX
 SG_ IDB_a016_wheelSpeedSensorOverTem m16 : 25|1@1+ (1,0) [0|1] "" Vector__XXX
 SG_ IDB_a016_wheelSpeedSensorSh_0001 m16 : 26|1@1+ (1,0) [0|1] "" Vector__XXX
 SG_ IDB_a016_wheelSpeedSensorShortTo m16 : 27|1@1+ (1,0) [0|1] "" Vector__XXX
 SG_ IDB_a016_wheelSpeedSensorOpen m16 : 28|1@1+ (1,0) [0|1] "" Vector__XXX
 SG_ IDB_a017_wheelSpeedSensorFreq m17 : 16|1@1+ (1,0) [0|1] "" Vector__XXX
 SG_ IDB_a017_wheelSpeedSensorPhase m17 : 17|1@1+ (1,0) [0|1] "" Vector__XXX
 SG_ IDB_a017_wheelSpeedSensorMisinst m17 : 18|1@1+ (1,0) [0|1] "" Vector__XXX
 SG_ IDB_a017_wheelSpeedSensorWrongEx m17 : 19|1@1+ (1,0) [0|1] "" Vector__XXX
 SG_ IDB_a017_wheelSpeedSensorSpeedJu m17 : 20|1@1+ (1,0) [0|1] "" Vector__XXX
 SG_ IDB_a017_wheelSpeedSensorSp_0001 m17 : 21|1@1+ (1,0) [0|1] "" Vector__XXX
 SG_ IDB_a017_wheelSpeedSensorAirGap m17 : 22|1@1+ (1,0) [0|1] "" Vector__XXX
 SG_ IDB_a017_wheelSpeedSensorBIST m17 : 23|1@1+ (1,0) [0|1] "" Vector__XXX
 SG_ IDB_a017_wheelSpeedSensorLeakage m17 : 24|1@1+ (1,0) [0|1] "" Vector__XXX
 SG_ IDB_a017_wheelSpeedSensorOverTem m17 : 25|1@1+ (1,0) [0|1] "" Vector__XXX
 SG_ IDB_a017_wheelSpeedSensorSh_0001 m17 : 26|1@1+ (1,0) [0|1] "" Vector__XXX
 SG_ IDB_a017_wheelSpeedSensorShortTo m17 : 27|1@1+ (1,0) [0|1] "" Vector__XXX
 SG_ IDB_a017_wheelSpeedSensorOpen m17 : 28|1@1+ (1,0) [0|1] "" Vector__XXX
 SG_ IDB_a020_canSignalValidity m20 : 16|1@1+ (1,0) [0|1] "" Vector__XXX
 SG_ IDB_a020_signalValueCrosscheck m20 : 17|1@1+ (1,0) [0|1] "" Vector__XXX
 SG_ IDB_a030_primaryExternalCircuitL m30 : 16|1@1+ (1,0) [0|1] "" Vector__XXX
 SG_ IDB_a030_secondaryExternalCircui m30 : 17|1@1+ (1,0) [0|1] "" Vector__XXX
 SG_ IDB_a030_primaryChamberInternalL m30 : 18|1@1+ (1,0) [0|1] "" Vector__XXX
 SG_ IDB_a030_syncModeInternalLeakage m30 : 19|1@1+ (1,0) [0|1] "" Vector__XXX
 SG_ IDB_a030_secondaryChamberInterna m30 : 20|1@1+ (1,0) [0|1] "" Vector__XXX
 SG_ IDB_a030_masterCylinderInternalL m30 : 21|1@1+ (1,0) [0|1] "" Vector__XXX
 SG_ IDB_a060_validityOnChassisBus m60 : 16|1@1+ (1,0) [0|1] "" Vector__XXX
 SG_ IDB_a060_validityOnPartyBus m60 : 17|1@1+ (1,0) [0|1] "" Vector__XXX
 SG_ IDB_a061_validityOnChassisBus m61 : 16|1@1+ (1,0) [0|1] "" Vector__XXX
 SG_ IDB_a061_validityOnPartyBus m61 : 17|1@1+ (1,0) [0|1] "" Vector__XXX
 SG_ IDB_a063_validityOnChassisBus m63 : 16|1@1+ (1,0) [0|1] "" Vector__XXX
 SG_ IDB_a063_validityOnPartyBus m63 : 17|1@1+ (1,0) [0|1] "" Vector__XXX
 SG_ IDB_a064_validityOnChassisBus m64 : 16|1@1+ (1,0) [0|1] "" Vector__XXX
 SG_ IDB_a064_validityOnPartyBus m64 : 17|1@1+ (1,0) [0|1] "" Vector__XXX
 SG_ IDB_a065_validityOnChassisBus m65 : 16|1@1+ (1,0) [0|1] "" Vector__XXX
 SG_ IDB_a065_validityOnPartyBus m65 : 17|1@1+ (1,0) [0|1] "" Vector__XXX
 SG_ IDB_a106_qualifierValidity m106 : 16|1@1+ (1,0) [0|1] "" Vector__XXX
 SG_ IDB_a106_signalNotAvailable m106 : 17|1@1+ (1,0) [0|1] "" Vector__XXX
 SG_ IDB_a107_qualifierValidity m107 : 16|1@1+ (1,0) [0|1] "" Vector__XXX
 SG_ IDB_a107_signalNotAvailable m107 : 17|1@1+ (1,0) [0|1] "" Vector__XXX
 SG_ IDB_a112_qualifierValidity m112 : 16|1@1+ (1,0) [0|1] "" Vector__XXX
 SG_ IDB_a112_signalNotAvailable m112 : 17|1@1+ (1,0) [0|1] "" Vector__XXX
 SG_ IDB_a113_qualifierValidity m113 : 16|1@1+ (1,0) [0|1] "" Vector__XXX
 SG_ IDB_a113_signalNotAvailable m113 : 17|1@1+ (1,0) [0|1] "" Vector__XXX
 SG_ IDB_a114_qualifierValidity m114 : 16|1@1+ (1,0) [0|1] "" Vector__XXX
 SG_ IDB_a114_signalNotAvailable m114 : 17|1@1+ (1,0) [0|1] "" Vector__XXX
 SG_ IDB_a126_PMebrCmdStateValidity m126 : 16|1@1+ (1,0) [0|1] "" Vector__XXX
 SG_ IDB_a126_PMstate2Validity m126 : 17|1@1+ (1,0) [0|1] "" Vector__XXX
 SG_ IDB_a126_PMstate2Missing m126 : 18|1@1+ (1,0) [0|1] "" Vector__XXX
 SG_ IDB_a126_DIchassisControlValidit m126 : 19|1@1+ (1,0) [0|1] "" Vector__XXX
 SG_ IDB_a126_DIchassisControlMissing m126 : 20|1@1+ (1,0) [0|1] "" Vector__XXX
 SG_ IDB_a126_DIrequestActiveValidity m126 : 21|1@1+ (1,0) [0|1] "" Vector__XXX
 SG_ IDB_a129_validityOnChassisBus m129 : 16|1@1+ (1,0) [0|1] "" Vector__XXX
 SG_ IDB_a129_validityOnPartyBus m129 : 17|1@1+ (1,0) [0|1] "" Vector__XXX
 SG_ IDB_a130_PMbrakePedalCmdQFValidi m130 : 16|1@1+ (1,0) [0|1] "" Vector__XXX
 SG_ IDB_a130_PMstate2Validity m130 : 17|1@1+ (1,0) [0|1] "" Vector__XXX
 SG_ IDB_a130_PMstate2Missing m130 : 18|1@1+ (1,0) [0|1] "" Vector__XXX
 SG_ IDB_a130_DIbrakeCommandValidity m130 : 19|1@1+ (1,0) [0|1] "" Vector__XXX
 SG_ IDB_a130_DIbrakeCommandMissing m130 : 20|1@1+ (1,0) [0|1] "" Vector__XXX
 SG_ IDB_a130_DIbrakeTorqueCommandFul m130 : 21|1@1+ (1,0) [0|1] "" Vector__XXX
 SG_ IDB_a130_DIbrakeTorqueComma_0001 m130 : 22|1@1+ (1,0) [0|1] "" Vector__XXX
 SG_ IDB_a132_validityOnChassisBus m132 : 16|1@1+ (1,0) [0|1] "" Vector__XXX
 SG_ IDB_a132_validityOnPartyBus m132 : 17|1@1+ (1,0) [0|1] "" Vector__XXX

BO_ 983 IDB_alertMatrix: 8 IDB
 SG_ IDB_matrixIndex M : 0|4@1+ (1,0) [0|15] "" Vector__XXX
 SG_ IDB_a001_mcuGenericFault m0 : 4|1@1+ (1,0) [0|1] "" Vector__XXX
 SG_ IDB_a002_supplyOvervoltage m0 : 5|1@1+ (1,0) [0|1] "" Vector__XXX
 SG_ IDB_a003_supplyHardOvervoltage m0 : 6|1@1+ (1,0) [0|1] "" Vector__XXX
 SG_ IDB_a004_supplyUndervoltage m0 : 7|1@1+ (1,0) [0|1] "" Vector__XXX
 SG_ IDB_a005_supplyMidUndervoltage m0 : 8|1@1+ (1,0) [0|1] "" Vector__XXX
 SG_ IDB_a006_supplyHardUndervoltage m0 : 9|1@1+ (1,0) [0|1] "" Vector__XXX
 SG_ IDB_a007_wakeLineOpen m0 : 10|1@1+ (1,0) [0|1] "" Vector__XXX
 SG_ IDB_a008_motorPowerOpen m0 : 11|1@1+ (1,0) [0|1] "" Vector__XXX
 SG_ IDB_a009_asicBoostFault m0 : 12|1@1+ (1,0) [0|1] "" Vector__XXX
 SG_ IDB_a010_asicGenericFault m0 : 13|1@1+ (1,0) [0|1] "" Vector__XXX
 SG_ IDB_a011_solenoidValveFault m0 : 14|1@1+ (1,0) [0|1] "" Vector__XXX
 SG_ IDB_a012_motorGenericFault m0 : 15|1@1+ (1,0) [0|1] "" Vector__XXX
 SG_ IDB_a013_motorPosSensorFault m0 : 16|1@1+ (1,0) [0|1] "" Vector__XXX
 SG_ IDB_a014_FrLWSSFault m0 : 17|1@1+ (1,0) [0|1] "" Vector__XXX
 SG_ IDB_a015_FrRWSSFault m0 : 18|1@1+ (1,0) [0|1] "" Vector__XXX
 SG_ IDB_a016_ReLWSSFault m0 : 19|1@1+ (1,0) [0|1] "" Vector__XXX
 SG_ IDB_a017_ReRWSSFault m0 : 20|1@1+ (1,0) [0|1] "" Vector__XXX
 SG_ IDB_a018_WSSGenericFault m0 : 21|1@1+ (1,0) [0|1] "" Vector__XXX
 SG_ IDB_a019_pedalSensorFault m0 : 22|1@1+ (1,0) [0|1] "" Vector__XXX
 SG_ IDB_a020_RCUpedalTravelMismatch m0 : 23|1@1+ (1,0) [0|1] "" Vector__XXX
 SG_ IDB_a021_pedalSensorNotCal m0 : 24|1@1+ (1,0) [0|1] "" Vector__XXX
 SG_ IDB_a022_brakeFluidLow m0 : 25|1@1+ (1,0) [0|1] "" Vector__XXX
 SG_ IDB_a023_steeringImplausible m0 : 26|1@1+ (1,0) [0|1] "" Vector__XXX
 SG_ IDB_a024_yawImplausible m0 : 27|1@1+ (1,0) [0|1] "" Vector__XXX
 SG_ IDB_a025_ayImplausible m0 : 28|1@1+ (1,0) [0|1] "" Vector__XXX
 SG_ IDB_a026_axImplausible m0 : 29|1@1+ (1,0) [0|1] "" Vector__XXX
 SG_ IDB_a027_circuitPresSensorFault m0 : 30|1@1+ (1,0) [0|1] "" Vector__XXX
 SG_ IDB_a028_simPresSensorFault m0 : 31|1@1+ (1,0) [0|1] "" Vector__XXX
 SG_ IDB_a029_pressureSensNotCal m0 : 32|1@1+ (1,0) [0|1] "" Vector__XXX
 SG_ IDB_a030_fluidLeakDetected m0 : 33|1@1+ (1,0) [0|1] "" Vector__XXX
 SG_ IDB_a031_solenoidValveStuck m0 : 34|1@1+ (1,0) [0|1] "" Vector__XXX
 SG_ IDB_a032_motorSoftOverheat m0 : 35|1@1+ (1,0) [0|1] "" Vector__XXX
 SG_ IDB_a033_motorHardOverheat m0 : 36|1@1+ (1,0) [0|1] "" Vector__XXX
 SG_ IDB_a034_motorPositionSetFault m0 : 37|1@1+ (1,0) [0|1] "" Vector__XXX
 SG_ IDB_a035_motorStuck m0 : 38|1@1+ (1,0) [0|1] "" Vector__XXX
 SG_ IDB_a036_partyBusOff m0 : 39|1@1+ (1,0) [0|1] "" Vector__XXX
 SG_ IDB_a037_chassisBusOff m0 : 40|1@1+ (1,0) [0|1] "" Vector__XXX
 SG_ IDB_a038_motorInitFault m0 : 41|1@1+ (1,0) [0|1] "" Vector__XXX
 SG_ IDB_a039_absActive m0 : 42|1@1+ (1,0) [0|1] "" Vector__XXX
 SG_ IDB_a040_ebdActive m0 : 43|1@1+ (1,0) [0|1] "" Vector__XXX
 SG_ IDB_a041_vdcActive m0 : 44|1@1+ (1,0) [0|1] "" Vector__XXX
 SG_ IDB_a042_btcActive m0 : 45|1@1+ (1,0) [0|1] "" Vector__XXX
 SG_ IDB_a043_cbcActive m0 : 46|1@1+ (1,0) [0|1] "" Vector__XXX
 SG_ IDB_a044_standstillSkidDetected m0 : 47|1@1+ (1,0) [0|1] "" Vector__XXX
 SG_ IDB_a045_panicBrakeAssistActive m0 : 48|1@1+ (1,0) [0|1] "" Vector__XXX
 SG_ IDB_a046_fadeCompensationActive m0 : 49|1@1+ (1,0) [0|1] "" Vector__XXX
 SG_ IDB_a047_brakeDiscWipeActive m0 : 50|1@1+ (1,0) [0|1] "" Vector__XXX
 SG_ IDB_a048_scmActive m0 : 51|1@1+ (1,0) [0|1] "" Vector__XXX
 SG_ IDB_a049_cdpActive m0 : 52|1@1+ (1,0) [0|1] "" Vector__XXX
 SG_ IDB_a050_absFaulted m0 : 53|1@1+ (1,0) [0|1] "" Vector__XXX
 SG_ IDB_a051_ebdFaulted m0 : 54|1@1+ (1,0) [0|1] "" Vector__XXX
 SG_ IDB_a052_vdcFaulted m0 : 55|1@1+ (1,0) [0|1] "" Vector__XXX
 SG_ IDB_a053_DItorquePathFaulted m0 : 56|1@1+ (1,0) [0|1] "" Vector__XXX
 SG_ IDB_a054_skidDetectionFaulted m0 : 57|1@1+ (1,0) [0|1] "" Vector__XXX
 SG_ IDB_a055_panicBrakeAssistFaulted m0 : 58|1@1+ (1,0) [0|1] "" Vector__XXX
 SG_ IDB_a056_fadeCompensationFaulted m0 : 59|1@1+ (1,0) [0|1] "" Vector__XXX
 SG_ IDB_a057_bdwRequestInvalid m0 : 60|1@1+ (1,0) [0|1] "" Vector__XXX
 SG_ IDB_a058_scmFaulted m0 : 61|1@1+ (1,0) [0|1] "" Vector__XXX
 SG_ IDB_a059_cdpFaulted m0 : 62|1@1+ (1,0) [0|1] "" Vector__XXX
 SG_ IDB_a060_RCUstatusDLC m0 : 63|1@1+ (1,0) [0|1] "" Vector__XXX
 SG_ IDB_a061_RCUstatusChecksum m1 : 4|1@1+ (1,0) [0|1] "" Vector__XXX
 SG_ IDB_a062_RCUstatusCounter m1 : 5|1@1+ (1,0) [0|1] "" Vector__XXX
 SG_ IDB_a063_RCUactuationDLC m1 : 6|1@1+ (1,0) [0|1] "" Vector__XXX
 SG_ IDB_a064_RCUactuationChecksum m1 : 7|1@1+ (1,0) [0|1] "" Vector__XXX
 SG_ IDB_a065_RCUactuationCounter m1 : 8|1@1+ (1,0) [0|1] "" Vector__XXX
 SG_ IDB_a066_DIFtorqueDLC m1 : 9|1@1+ (1,0) [0|1] "" Vector__XXX
 SG_ IDB_a067_DIFtorqueChecksum m1 : 10|1@1+ (1,0) [0|1] "" Vector__XXX
 SG_ IDB_a068_DIFtorqueCounter m1 : 11|1@1+ (1,0) [0|1] "" Vector__XXX
 SG_ IDB_a069_DIchassisControlDLC m1 : 12|1@1+ (1,0) [0|1] "" Vector__XXX
 SG_ IDB_a070_DIchassisControlChecksu m1 : 13|1@1+ (1,0) [0|1] "" Vector__XXX
 SG_ IDB_a071_DIchassisControlCounter m1 : 14|1@1+ (1,0) [0|1] "" Vector__XXX
 SG_ IDB_a072_DIsystemStatusDLC m1 : 15|1@1+ (1,0) [0|1] "" Vector__XXX
 SG_ IDB_a073_DIsystemStatusChecksum m1 : 16|1@1+ (1,0) [0|1] "" Vector__XXX
 SG_ IDB_a074_DIsystemStatusCounter m1 : 17|1@1+ (1,0) [0|1] "" Vector__XXX
 SG_ IDB_a075_DIRtorqueDLC m1 : 18|1@1+ (1,0) [0|1] "" Vector__XXX
 SG_ IDB_a076_DIRtorqueChecksum m1 : 19|1@1+ (1,0) [0|1] "" Vector__XXX
 SG_ IDB_a077_DIRtorqueCounter m1 : 20|1@1+ (1,0) [0|1] "" Vector__XXX
 SG_ IDB_a078_DIvdcLeftDLC m1 : 21|1@1+ (1,0) [0|1] "" Vector__XXX
 SG_ IDB_a079_DIvdcLeftChecksum m1 : 22|1@1+ (1,0) [0|1] "" Vector__XXX
 SG_ IDB_a080_DIvdcLeftCounter m1 : 23|1@1+ (1,0) [0|1] "" Vector__XXX
 SG_ IDB_a081_DIvdcRightDLC m1 : 24|1@1+ (1,0) [0|1] "" Vector__XXX
 SG_ IDB_a082_DIvdcRightChecksum m1 : 25|1@1+ (1,0) [0|1] "" Vector__XXX
 SG_ IDB_a083_DIvdcRightCounter m1 : 26|1@1+ (1,0) [0|1] "" Vector__XXX
 SG_ IDB_a084_EPAS3PsysStatusDLC m1 : 27|1@1+ (1,0) [0|1] "" Vector__XXX
 SG_ IDB_a085_EPAS3PsysStatusChecksum m1 : 28|1@1+ (1,0) [0|1] "" Vector__XXX
 SG_ IDB_a086_EPAS3PsysStatusCounter m1 : 29|1@1+ (1,0) [0|1] "" Vector__XXX
 SG_ IDB_a087_PMstate2DLC m1 : 30|1@1+ (1,0) [0|1] "" Vector__XXX
 SG_ IDB_a088_PMstate2Checksum m1 : 31|1@1+ (1,0) [0|1] "" Vector__XXX
 SG_ IDB_a089_PMstate2Counter m1 : 32|1@1+ (1,0) [0|1] "" Vector__XXX
 SG_ IDB_a090_RCMinertial1DLC m1 : 33|1@1+ (1,0) [0|1] "" Vector__XXX
 SG_ IDB_a091_RCMinertial1Checksum m1 : 34|1@1+ (1,0) [0|1] "" Vector__XXX
 SG_ IDB_a092_RCMinertial1Counter m1 : 35|1@1+ (1,0) [0|1] "" Vector__XXX
 SG_ IDB_a093_RCMinertial2DLC m1 : 36|1@1+ (1,0) [0|1] "" Vector__XXX
 SG_ IDB_a094_RCMinertial2Checksum m1 : 37|1@1+ (1,0) [0|1] "" Vector__XXX
 SG_ IDB_a095_RCMinertial2Counter m1 : 38|1@1+ (1,0) [0|1] "" Vector__XXX
 SG_ IDB_a096_VCFRONTLVPowerStateDLC m1 : 39|1@1+ (1,0) [0|1] "" Vector__XXX
 SG_ IDB_a097_VCFRONTLVPwrStChecksum m1 : 40|1@1+ (1,0) [0|1] "" Vector__XXX
 SG_ IDB_a098_VCFRONTLVPwrStCounter m1 : 41|1@1+ (1,0) [0|1] "" Vector__XXX
 SG_ IDB_a099_RCMcollisionDLC m1 : 42|1@1+ (1,0) [0|1] "" Vector__XXX
 SG_ IDB_a100_RCMcollisionChecksum m1 : 43|1@1+ (1,0) [0|1] "" Vector__XXX
 SG_ IDB_a101_RCMcollisionCounter m1 : 44|1@1+ (1,0) [0|1] "" Vector__XXX
 SG_ IDB_a102_bdwRequestActiveInvalid m1 : 45|1@1+ (1,0) [0|1] "" Vector__XXX
 SG_ IDB_a103_DIfullTorquePathFaulted m1 : 46|1@1+ (1,0) [0|1] "" Vector__XXX
 SG_ IDB_a104_DIaccelPosInvalid m1 : 47|1@1+ (1,0) [0|1] "" Vector__XXX
 SG_ IDB_a105_DIgearInvalid m1 : 48|1@1+ (1,0) [0|1] "" Vector__XXX
 SG_ IDB_a106_DIFtorqueInvalid m1 : 49|1@1+ (1,0) [0|1] "" Vector__XXX
 SG_ IDB_a107_DIRtorqueInvalid m1 : 50|1@1+ (1,0) [0|1] "" Vector__XXX
 SG_ IDB_a108_EPBstatusDLC m1 : 51|1@1+ (1,0) [0|1] "" Vector__XXX
 SG_ IDB_a109_BDWsignalInvalid m1 : 52|1@1+ (1,0) [0|1] "" Vector__XXX
 SG_ IDB_a110_EPBstatusCounter m1 : 53|1@1+ (1,0) [0|1] "" Vector__XXX
 SG_ IDB_a111_EPBstatusChecksum m1 : 54|1@1+ (1,0) [0|1] "" Vector__XXX
 SG_ IDB_a112_yawRateInvalid m1 : 55|1@1+ (1,0) [0|1] "" Vector__XXX
 SG_ IDB_a113_latAccelInvalid m1 : 56|1@1+ (1,0) [0|1] "" Vector__XXX
 SG_ IDB_a114_longAccelInvalid m1 : 57|1@1+ (1,0) [0|1] "" Vector__XXX
 SG_ IDB_a115_VCFRONTespLvStInvalid m1 : 58|1@1+ (1,0) [0|1] "" Vector__XXX
 SG_ IDB_a116_VCFRONTsensorsDLC m1 : 59|1@1+ (1,0) [0|1] "" Vector__XXX
 SG_ IDB_a117_VCLEFTepbmStatusDLC m1 : 60|1@1+ (1,0) [0|1] "" Vector__XXX
 SG_ IDB_a118_VCLEFTepbmStatusCounter m1 : 61|1@1+ (1,0) [0|1] "" Vector__XXX
 SG_ IDB_a119_VCLEFTepbmStatusChecksu m1 : 62|1@1+ (1,0) [0|1] "" Vector__XXX
 SG_ IDB_a120_EPAS3Pinvalid m1 : 63|1@1+ (1,0) [0|1] "" Vector__XXX
 SG_ IDB_a121_dynoModeActive m2 : 4|1@1+ (1,0) [0|1] "" Vector__XXX
 SG_ IDB_a122_DIFtorqueCommandInvalid m2 : 5|1@1+ (1,0) [0|1] "" Vector__XXX
 SG_ IDB_a123_DIRtorqueCommandInvalid m2 : 6|1@1+ (1,0) [0|1] "" Vector__XXX
 SG_ IDB_a124_VCFRONTtempInvalid m2 : 7|1@1+ (1,0) [0|1] "" Vector__XXX
 SG_ IDB_a125_PMvdcCmdStateInvalid m2 : 8|1@1+ (1,0) [0|1] "" Vector__XXX
 SG_ IDB_a126_DItorqueRequestInvalid m2 : 9|1@1+ (1,0) [0|1] "" Vector__XXX
 SG_ IDB_a127_brakeFluidLevelInvalid m2 : 10|1@1+ (1,0) [0|1] "" Vector__XXX
 SG_ IDB_a128_largeAirVolume m2 : 11|1@1+ (1,0) [0|1] "" Vector__XXX
 SG_ IDB_a129_RCUinputRodStrokeInvali m2 : 12|1@1+ (1,0) [0|1] "" Vector__XXX
 SG_ IDB_a130_DIfullTorqueRequestInva m2 : 13|1@1+ (1,0) [0|1] "" Vector__XXX
 SG_ IDB_a131_cbcFaulted m2 : 14|1@1+ (1,0) [0|1] "" Vector__XXX
 SG_ IDB_a132_RCUinputRodStrokeQFInva m2 : 15|1@1+ (1,0) [0|1] "" Vector__XXX
 SG_ IDB_a133_DIbrakeCommandDLC m2 : 16|1@1+ (1,0) [0|1] "" Vector__XXX
 SG_ IDB_a134_DIbrakeCommandCounter m2 : 17|1@1+ (1,0) [0|1] "" Vector__XXX
 SG_ IDB_a135_DIbrakeCommandChecksum m2 : 18|1@1+ (1,0) [0|1] "" Vector__XXX
 SG_ IDB_a136_RCUptsCalMissing m2 : 19|1@1+ (1,0) [0|1] "" Vector__XXX
 SG_ IDB_a137_VCLEFTcdpRequestInvalid m2 : 20|1@1+ (1,0) [0|1] "" Vector__XXX
 SG_ IDB_a138_DIbrakeTorqueCommandAnd m2 : 21|1@1+ (1,0) [0|1] "" Vector__XXX
 SG_ IDB_a139_DIbrakeTorqueCommandFul m2 : 22|1@1+ (1,0) [0|1] "" Vector__XXX
 SG_ IDB_a140_PMbrakePedalCmdQFInvali m2 : 23|1@1+ (1,0) [0|1] "" Vector__XXX
 SG_ IDB_a141_DIbrakeTorqueCommandFul m2 : 24|1@1+ (1,0) [0|1] "" Vector__XXX
 SG_ IDB_a142_PMebrCmdStateInvalid m2 : 25|1@1+ (1,0) [0|1] "" Vector__XXX
 SG_ IDB_a143_factoryModeActive m2 : 26|1@1+ (1,0) [0|1] "" Vector__XXX
 SG_ IDB_a144_hydraulicPushthroughAct m2 : 27|1@1+ (1,0) [0|1] "" Vector__XXX
 SG_ IDB_a145_DASredundantBrakingCont m2 : 28|1@1+ (1,0) [0|1] "" Vector__XXX
 SG_ IDB_a146_DASredundantBrakingCont m2 : 29|1@1+ (1,0) [0|1] "" Vector__XXX
 SG_ IDB_a147_DASredundantBrakingCont m2 : 30|1@1+ (1,0) [0|1] "" Vector__XXX
 SG_ IDB_a148_DASbrakeTorqueCommandIn m2 : 31|1@1+ (1,0) [0|1] "" Vector__XXX
 SG_ IDB_a149_DASmiaBrakeTorqueComman m2 : 32|1@1+ (1,0) [0|1] "" Vector__XXX
 SG_ IDB_a150_DIlocStatus2DLC m2 : 33|1@1+ (1,0) [0|1] "" Vector__XXX
 SG_ IDB_a151_DIlocStatus2Counter m2 : 34|1@1+ (1,0) [0|1] "" Vector__XXX
 SG_ IDB_a152_DIlocStatus2Checksum m2 : 35|1@1+ (1,0) [0|1] "" Vector__XXX
 SG_ IDB_a155_PMlocStateDLC m2 : 38|1@1+ (1,0) [0|1] "" Vector__XXX
 SG_ IDB_a156_PMlocStateChecksum m2 : 39|1@1+ (1,0) [0|1] "" Vector__XXX
 SG_ IDB_a157_PMlocStateCounter m2 : 40|1@1+ (1,0) [0|1] "" Vector__XXX

BO_ 828 IDB_info: 8 IDB
 SG_ IDB_infoIndex M : 0|8@1+ (1,0) [0|255] "" Vector__XXX
 SG_ IDB_infoPcbaID m11 : 16|8@1+ (1,0) [0|255] "" Vector__XXX
 SG_ IDB_infoAssemblyID m11 : 24|8@1+ (1,0) [0|255] "" Vector__XXX
 SG_ IDB_infoUsageID m11 : 32|16@1+ (1,0) [0|65535] "" Vector__XXX
 SG_ IDB_infoSubUsageID m11 : 48|16@1+ (1,0) [0|65535] "" Vector__XXX

BO_ 1012 LS_lightShow: 8 LS
 SG_ LS_lightShowIndex M : 0|5@1+ (1,0) [0|31] "" Vector__XXX
 SG_ LS_lightLeftRampedChannel1Reques m0 : 5|1@1+ (1,0) [0|1] "" Vector__XXX
 SG_ LS_lightLeftRampedChannel1Durati m0 : 6|2@1+ (1,0) [0|3] "" Vector__XXX
 SG_ LS_lightLeftRampedChannel2Reques m0 : 8|1@1+ (1,0) [0|1] "" Vector__XXX
 SG_ LS_lightLeftRampedChannel2Durati m0 : 9|2@1+ (1,0) [0|3] "" Vector__XXX
 SG_ LS_lightLeftRampedChannel3Reques m0 : 11|1@1+ (1,0) [0|1] "" Vector__XXX
 SG_ LS_lightLeftRampedChannel3Durati m0 : 12|2@1+ (1,0) [0|3] "" Vector__XXX
 SG_ LS_lightLeftRampedChannel4Reques m0 : 14|1@1+ (1,0) [0|1] "" Vector__XXX
 SG_ LS_lightLeftRampedChannel4Durati m0 : 16|2@1+ (1,0) [0|3] "" Vector__XXX
 SG_ LS_lightLeftRampedChannel5Reques m0 : 18|1@1+ (1,0) [0|1] "" Vector__XXX
 SG_ LS_lightLeftRampedChannel5Durati m0 : 19|2@1+ (1,0) [0|3] "" Vector__XXX
 SG_ LS_lightLeftRampedChannel6Reques m0 : 21|1@1+ (1,0) [0|1] "" Vector__XXX
 SG_ LS_lightLeftRampedChannel6Durati m0 : 22|2@1+ (1,0) [0|3] "" Vector__XXX
 SG_ LS_lightLeftRampedChannel7Reques m0 : 24|1@1+ (1,0) [0|1] "" Vector__XXX
 SG_ LS_lightLeftRampedChannel7Durati m0 : 25|2@1+ (1,0) [0|3] "" Vector__XXX
 SG_ LS_lightRightRampedChannel1Reque m0 : 27|1@1+ (1,0) [0|1] "" Vector__XXX
 SG_ LS_lightRightRampedChannel1Durat m0 : 28|2@1+ (1,0) [0|3] "" Vector__XXX
 SG_ LS_lightRightRampedChannel2Reque m0 : 30|1@1+ (1,0) [0|1] "" Vector__XXX
 SG_ LS_lightRightRampedChannel2Durat m0 : 31|2@1+ (1,0) [0|3] "" Vector__XXX
 SG_ LS_lightRightRampedChannel3Reque m0 : 33|1@1+ (1,0) [0|1] "" Vector__XXX
 SG_ LS_lightRightRampedChannel3Durat m0 : 34|2@1+ (1,0) [0|3] "" Vector__XXX
 SG_ LS_lightRightRampedChannel4Reque m0 : 36|1@1+ (1,0) [0|1] "" Vector__XXX
 SG_ LS_lightRightRampedChannel4Durat m0 : 37|2@1+ (1,0) [0|3] "" Vector__XXX
 SG_ LS_lightRightRampedChannel5Reque m0 : 39|1@1+ (1,0) [0|1] "" Vector__XXX
 SG_ LS_lightRightRampedChannel5Durat m0 : 40|2@1+ (1,0) [0|3] "" Vector__XXX
 SG_ LS_lightRightRampedChannel6Reque m0 : 42|1@1+ (1,0) [0|1] "" Vector__XXX
 SG_ LS_lightRightRampedChannel6Durat m0 : 43|2@1+ (1,0) [0|3] "" Vector__XXX
 SG_ LS_lightRightRampedChannel7Reque m0 : 45|1@1+ (1,0) [0|1] "" Vector__XXX
 SG_ LS_lightRightRampedChannel7Durat m0 : 46|2@1+ (1,0) [0|3] "" Vector__XXX
 SG_ LS_lightRearTurnLeftRequest m0 : 48|1@1+ (1,0) [0|1] "" Vector__XXX
 SG_ LS_lightRearTurnRightRequest m0 : 49|1@1+ (1,0) [0|1] "" Vector__XXX
 SG_ LS_lightSideRepeaterLeftRequest m0 : 50|1@1+ (1,0) [0|1] "" Vector__XXX
 SG_ LS_lightSideRepeaterRightRequest m0 : 51|1@1+ (1,0) [0|1] "" Vector__XXX
 SG_ LS_lightSideMarkerLeftRequest m0 : 52|1@1+ (1,0) [0|1] "" Vector__XXX
 SG_ LS_lightSideMarkerRightRequest m0 : 53|1@1+ (1,0) [0|1] "" Vector__XXX
 SG_ LS_lightFrontFogLeftRequest m0 : 54|1@1+ (1,0) [0|1] "" Vector__XXX
 SG_ LS_lightFrontFogRightRequest m0 : 55|1@1+ (1,0) [0|1] "" Vector__XXX
 SG_ LS_lightRearFogRequest m0 : 56|1@1+ (1,0) [0|1] "" Vector__XXX
 SG_ LS_lightBrakeRequest m0 : 57|1@1+ (1,0) [0|1] "" Vector__XXX
 SG_ LS_lightTailLeftRequest m0 : 58|1@1+ (1,0) [0|1] "" Vector__XXX
 SG_ LS_lightTailRightRequest m0 : 59|1@1+ (1,0) [0|1] "" Vector__XXX
 SG_ LS_lightLicensePlateRequest m0 : 60|1@1+ (1,0) [0|1] "" Vector__XXX
 SG_ LS_lightReverseRequest m0 : 61|1@1+ (1,0) [0|1] "" Vector__XXX
 SG_ LS_lightAuxParkLeftRequest m0 : 62|1@1+ (1,0) [0|1] "" Vector__XXX
 SG_ LS_lightAuxParkRightRequest m0 : 63|1@1+ (1,0) [0|1] "" Vector__XXX
 SG_ LS_mirrorRequestLeft m1 : 5|3@1+ (1,0) [0|7] "" Vector__XXX
 SG_ LS_mirrorRequestRight m1 : 8|3@1+ (1,0) [0|7] "" Vector__XXX
 SG_ LS_liftgateRequest m1 : 11|3@1+ (1,0) [0|7] "" Vector__XXX
 SG_ LS_windowRequestLF m1 : 16|3@1+ (1,0) [0|7] "" Vector__XXX
 SG_ LS_windowRequestLR m1 : 19|3@1+ (1,0) [0|7] "" Vector__XXX
 SG_ LS_windowRequestRF m1 : 24|3@1+ (1,0) [0|7] "" Vector__XXX
 SG_ LS_windowRequestRR m1 : 27|3@1+ (1,0) [0|7] "" Vector__XXX
 SG_ LS_presentingHandleRequestLF m1 : 32|3@1+ (1,0) [0|7] "" Vector__XXX
 SG_ LS_presentingHandleRequestLR m1 : 35|3@1+ (1,0) [0|7] "" Vector__XXX
 SG_ LS_presentingHandleRequestRF m1 : 40|3@1+ (1,0) [0|7] "" Vector__XXX
 SG_ LS_presentingHandleRequestRR m1 : 43|3@1+ (1,0) [0|7] "" Vector__XXX
 SG_ LS_powerFrontDoorRequestLeft m1 : 46|3@1+ (1,0) [0|7] "" Vector__XXX
 SG_ LS_powerFrontDoorRequestRight m1 : 49|3@1+ (1,0) [0|7] "" Vector__XXX
 SG_ LS_falconDoorRequestLeft m1 : 52|3@1+ (1,0) [0|7] "" Vector__XXX
 SG_ LS_falconDoorRequestRight m1 : 55|3@1+ (1,0) [0|7] "" Vector__XXX
 SG_ LS_chargePortRequest m1 : 58|2@1+ (1,0) [0|3] "" Vector__XXX
 SG_ LS_chargePortRaveRequest m1 : 60|1@1+ (1,0) [0|1] "" Vector__XXX
 SG_ LS_suspensionRequest m1 : 61|2@1+ (1,0) [0|3] "" Vector__XXX
 SG_ LS_rgbIPFLRed m2 : 8|8@1+ (1,0) [0|255] "" Vector__XXX
 SG_ LS_rgbIPFLGreen m2 : 16|8@1+ (1,0) [0|255] "" Vector__XXX
 SG_ LS_rgbIPFLBlue m2 : 24|8@1+ (1,0) [0|255] "" Vector__XXX
 SG_ LS_rgbIPFRRed m2 : 32|8@1+ (1,0) [0|255] "" Vector__XXX
 SG_ LS_rgbIPFRGreen m2 : 40|8@1+ (1,0) [0|255] "" Vector__XXX
 SG_ LS_rgbIPFRBlue m2 : 48|8@1+ (1,0) [0|255] "" Vector__XXX
 SG_ LS_rgbDoorFLForeRed m3 : 8|8@1+ (1,0) [0|255] "" Vector__XXX
 SG_ LS_rgbDoorFLForeGreen m3 : 16|8@1+ (1,0) [0|255] "" Vector__XXX
 SG_ LS_rgbDoorFLForeBlue m3 : 24|8@1+ (1,0) [0|255] "" Vector__XXX
 SG_ LS_rgbDoorFLAftRed m3 : 32|8@1+ (1,0) [0|255] "" Vector__XXX
 SG_ LS_rgbDoorFLAftGreen m3 : 40|8@1+ (1,0) [0|255] "" Vector__XXX
 SG_ LS_rgbDoorFLAftBlue m3 : 48|8@1+ (1,0) [0|255] "" Vector__XXX
 SG_ LS_rgbDoorFRForeRed m4 : 8|8@1+ (1,0) [0|255] "" Vector__XXX
 SG_ LS_rgbDoorFRForeGreen m4 : 16|8@1+ (1,0) [0|255] "" Vector__XXX
 SG_ LS_rgbDoorFRForeBlue m4 : 24|8@1+ (1,0) [0|255] "" Vector__XXX
 SG_ LS_rgbDoorFRAftRed m4 : 32|8@1+ (1,0) [0|255] "" Vector__XXX
 SG_ LS_rgbDoorFRAftGreen m4 : 40|8@1+ (1,0) [0|255] "" Vector__XXX
 SG_ LS_rgbDoorFRAftBlue m4 : 48|8@1+ (1,0) [0|255] "" Vector__XXX
 SG_ LS_rgbDoorRLForeRed m5 : 8|8@1+ (1,0) [0|255] "" Vector__XXX
 SG_ LS_rgbDoorRLForeGreen m5 : 16|8@1+ (1,0) [0|255] "" Vector__XXX
 SG_ LS_rgbDoorRLForeBlue m5 : 24|8@1+ (1,0) [0|255] "" Vector__XXX
 SG_ LS_rgbDoorRLAftRed m5 : 32|8@1+ (1,0) [0|255] "" Vector__XXX
 SG_ LS_rgbDoorRLAftGreen m5 : 40|8@1+ (1,0) [0|255] "" Vector__XXX
 SG_ LS_rgbDoorRLAftBlue m5 : 48|8@1+ (1,0) [0|255] "" Vector__XXX
 SG_ LS_rgbDoorRRForeRed m6 : 8|8@1+ (1,0) [0|255] "" Vector__XXX
 SG_ LS_rgbDoorRRForeGreen m6 : 16|8@1+ (1,0) [0|255] "" Vector__XXX
 SG_ LS_rgbDoorRRForeBlue m6 : 24|8@1+ (1,0) [0|255] "" Vector__XXX
 SG_ LS_rgbDoorRRAftRed m6 : 32|8@1+ (1,0) [0|255] "" Vector__XXX
 SG_ LS_rgbDoorRRAftGreen m6 : 40|8@1+ (1,0) [0|255] "" Vector__XXX
 SG_ LS_rgbDoorRRAftBlue m6 : 48|8@1+ (1,0) [0|255] "" Vector__XXX
 SG_ LS_frontMatrix0 m7 : 8|8@1+ (1,0) [0|255] "" Vector__XXX
 SG_ LS_frontMatrix1 m7 : 16|8@1+ (1,0) [0|255] "" Vector__XXX
 SG_ LS_frontMatrix2 m7 : 24|8@1+ (1,0) [0|255] "" Vector__XXX
 SG_ LS_frontMatrix3 m7 : 32|8@1+ (1,0) [0|255] "" Vector__XXX
 SG_ LS_frontMatrix4 m7 : 40|8@1+ (1,0) [0|255] "" Vector__XXX
 SG_ LS_frontMatrix5 m7 : 48|8@1+ (1,0) [0|255] "" Vector__XXX
 SG_ LS_frontMatrix6 m7 : 56|8@1+ (1,0) [0|255] "" Vector__XXX
 SG_ LS_frontMatrix7 m8 : 8|8@1+ (1,0) [0|255] "" Vector__XXX
 SG_ LS_frontMatrix8 m8 : 16|8@1+ (1,0) [0|255] "" Vector__XXX
 SG_ LS_frontMatrix9 m8 : 24|8@1+ (1,0) [0|255] "" Vector__XXX
 SG_ LS_frontMatrix10 m8 : 32|8@1+ (1,0) [0|255] "" Vector__XXX
 SG_ LS_frontMatrix11 m8 : 40|8@1+ (1,0) [0|255] "" Vector__XXX
 SG_ LS_frontMatrix12 m8 : 48|8@1+ (1,0) [0|255] "" Vector__XXX
 SG_ LS_frontMatrix13 m8 : 56|8@1+ (1,0) [0|255] "" Vector__XXX
 SG_ LS_frontMatrix14 m9 : 8|8@1+ (1,0) [0|255] "" Vector__XXX
 SG_ LS_frontMatrix15 m9 : 16|8@1+ (1,0) [0|255] "" Vector__XXX
 SG_ LS_frontMatrix16 m9 : 24|8@1+ (1,0) [0|255] "" Vector__XXX
 SG_ LS_frontMatrix17 m9 : 32|8@1+ (1,0) [0|255] "" Vector__XXX
 SG_ LS_frontMatrix18 m9 : 40|8@1+ (1,0) [0|255] "" Vector__XXX
 SG_ LS_frontMatrix19 m9 : 48|8@1+ (1,0) [0|255] "" Vector__XXX
 SG_ LS_frontMatrix20 m9 : 56|8@1+ (1,0) [0|255] "" Vector__XXX
 SG_ LS_frontMatrix21 m10 : 8|8@1+ (1,0) [0|255] "" Vector__XXX
 SG_ LS_frontMatrix22 m10 : 16|8@1+ (1,0) [0|255] "" Vector__XXX
 SG_ LS_frontMatrix23 m10 : 24|8@1+ (1,0) [0|255] "" Vector__XXX
 SG_ LS_frontMatrix24 m10 : 32|8@1+ (1,0) [0|255] "" Vector__XXX
 SG_ LS_frontMatrix25 m10 : 40|8@1+ (1,0) [0|255] "" Vector__XXX
 SG_ LS_frontMatrix26 m10 : 48|8@1+ (1,0) [0|255] "" Vector__XXX
 SG_ LS_frontMatrix27 m10 : 56|8@1+ (1,0) [0|255] "" Vector__XXX
 SG_ LS_frontMatrix28 m11 : 8|8@1+ (1,0) [0|255] "" Vector__XXX
 SG_ LS_frontMatrix29 m11 : 16|8@1+ (1,0) [0|255] "" Vector__XXX
 SG_ LS_frontMatrix30 m11 : 24|8@1+ (1,0) [0|255] "" Vector__XXX
 SG_ LS_frontMatrix31 m11 : 32|8@1+ (1,0) [0|255] "" Vector__XXX
 SG_ LS_frontMatrix32 m11 : 40|8@1+ (1,0) [0|255] "" Vector__XXX
 SG_ LS_frontMatrix33 m11 : 48|8@1+ (1,0) [0|255] "" Vector__XXX
 SG_ LS_frontMatrix34 m11 : 56|8@1+ (1,0) [0|255] "" Vector__XXX
 SG_ LS_frontMatrix35 m12 : 8|8@1+ (1,0) [0|255] "" Vector__XXX
 SG_ LS_frontMatrix36 m12 : 16|8@1+ (1,0) [0|255] "" Vector__XXX
 SG_ LS_frontMatrix37 m12 : 24|8@1+ (1,0) [0|255] "" Vector__XXX
 SG_ LS_frontMatrix38 m12 : 32|8@1+ (1,0) [0|255] "" Vector__XXX
 SG_ LS_frontMatrix39 m12 : 40|8@1+ (1,0) [0|255] "" Vector__XXX
 SG_ LS_frontMatrix40 m12 : 48|8@1+ (1,0) [0|255] "" Vector__XXX
 SG_ LS_frontMatrix41 m12 : 56|8@1+ (1,0) [0|255] "" Vector__XXX
 SG_ LS_frontMatrix42 m13 : 8|8@1+ (1,0) [0|255] "" Vector__XXX
 SG_ LS_frontMatrix43 m13 : 16|8@1+ (1,0) [0|255] "" Vector__XXX
 SG_ LS_frontMatrix44 m13 : 24|8@1+ (1,0) [0|255] "" Vector__XXX
 SG_ LS_frontMatrix45 m13 : 32|8@1+ (1,0) [0|255] "" Vector__XXX
 SG_ LS_frontMatrix46 m13 : 40|8@1+ (1,0) [0|255] "" Vector__XXX
 SG_ LS_frontMatrix47 m13 : 48|8@1+ (1,0) [0|255] "" Vector__XXX
 SG_ LS_frontMatrix48 m13 : 56|8@1+ (1,0) [0|255] "" Vector__XXX
 SG_ LS_frontMatrix49 m14 : 8|8@1+ (1,0) [0|255] "" Vector__XXX
 SG_ LS_frontMatrix50 m14 : 16|8@1+ (1,0) [0|255] "" Vector__XXX
 SG_ LS_frontMatrix51 m14 : 24|8@1+ (1,0) [0|255] "" Vector__XXX
 SG_ LS_frontMatrix52 m14 : 32|8@1+ (1,0) [0|255] "" Vector__XXX
 SG_ LS_frontMatrix53 m14 : 40|8@1+ (1,0) [0|255] "" Vector__XXX
 SG_ LS_frontMatrix54 m14 : 48|8@1+ (1,0) [0|255] "" Vector__XXX
 SG_ LS_frontMatrix55 m14 : 56|8@1+ (1,0) [0|255] "" Vector__XXX
 SG_ LS_frontMatrix56 m15 : 8|8@1+ (1,0) [0|255] "" Vector__XXX
 SG_ LS_frontMatrix57 m15 : 16|8@1+ (1,0) [0|255] "" Vector__XXX
 SG_ LS_frontMatrix58 m15 : 24|8@1+ (1,0) [0|255] "" Vector__XXX
 SG_ LS_frontMatrix59 m15 : 32|8@1+ (1,0) [0|255] "" Vector__XXX
 SG_ LS_rearMatrix0 m15 : 40|8@1+ (1,0) [0|255] "" Vector__XXX
 SG_ LS_rearMatrix1 m15 : 48|8@1+ (1,0) [0|255] "" Vector__XXX
 SG_ LS_rearMatrix2 m15 : 56|8@1+ (1,0) [0|255] "" Vector__XXX
 SG_ LS_rearMatrix3 m16 : 8|8@1+ (1,0) [0|255] "" Vector__XXX
 SG_ LS_rearMatrix4 m16 : 16|8@1+ (1,0) [0|255] "" Vector__XXX
 SG_ LS_rearMatrix5 m16 : 24|8@1+ (1,0) [0|255] "" Vector__XXX
 SG_ LS_rearMatrix6 m16 : 32|8@1+ (1,0) [0|255] "" Vector__XXX
 SG_ LS_rearMatrix7 m16 : 40|8@1+ (1,0) [0|255] "" Vector__XXX
 SG_ LS_rearMatrix8 m16 : 48|8@1+ (1,0) [0|255] "" Vector__XXX
 SG_ LS_rearMatrix9 m16 : 56|8@1+ (1,0) [0|255] "" Vector__XXX
 SG_ LS_rearMatrix10 m17 : 8|8@1+ (1,0) [0|255] "" Vector__XXX
 SG_ LS_rearMatrix11 m17 : 16|8@1+ (1,0) [0|255] "" Vector__XXX
 SG_ LS_rearMatrix12 m17 : 24|8@1+ (1,0) [0|255] "" Vector__XXX
 SG_ LS_rearMatrix13 m17 : 32|8@1+ (1,0) [0|255] "" Vector__XXX
 SG_ LS_rearMatrix14 m17 : 40|8@1+ (1,0) [0|255] "" Vector__XXX
 SG_ LS_rearMatrix15 m17 : 48|8@1+ (1,0) [0|255] "" Vector__XXX
 SG_ LS_rearMatrix16 m17 : 56|8@1+ (1,0) [0|255] "" Vector__XXX
 SG_ LS_rearMatrix17 m18 : 8|8@1+ (1,0) [0|255] "" Vector__XXX
 SG_ LS_rearMatrix18 m18 : 16|8@1+ (1,0) [0|255] "" Vector__XXX
 SG_ LS_rearMatrix19 m18 : 24|8@1+ (1,0) [0|255] "" Vector__XXX
 SG_ LS_rearMatrix20 m18 : 32|8@1+ (1,0) [0|255] "" Vector__XXX
 SG_ LS_rearMatrix21 m18 : 40|8@1+ (1,0) [0|255] "" Vector__XXX
 SG_ LS_rearMatrix22 m18 : 48|8@1+ (1,0) [0|255] "" Vector__XXX
 SG_ LS_rearMatrix23 m18 : 56|8@1+ (1,0) [0|255] "" Vector__XXX
 SG_ LS_rearMatrix24 m19 : 8|8@1+ (1,0) [0|255] "" Vector__XXX
 SG_ LS_rearMatrix25 m19 : 16|8@1+ (1,0) [0|255] "" Vector__XXX
 SG_ LS_rearMatrix26 m19 : 24|8@1+ (1,0) [0|255] "" Vector__XXX
 SG_ LS_rearMatrix27 m19 : 32|8@1+ (1,0) [0|255] "" Vector__XXX
 SG_ LS_rearMatrix28 m19 : 40|8@1+ (1,0) [0|255] "" Vector__XXX
 SG_ LS_rearMatrix29 m19 : 48|8@1+ (1,0) [0|255] "" Vector__XXX
 SG_ LS_rearMatrix30 m19 : 56|8@1+ (1,0) [0|255] "" Vector__XXX
 SG_ LS_rearMatrix31 m20 : 8|8@1+ (1,0) [0|255] "" Vector__XXX
 SG_ LS_rearMatrix32 m20 : 16|8@1+ (1,0) [0|255] "" Vector__XXX
 SG_ LS_rearMatrix33 m20 : 24|8@1+ (1,0) [0|255] "" Vector__XXX
 SG_ LS_rearMatrix34 m20 : 32|8@1+ (1,0) [0|255] "" Vector__XXX
 SG_ LS_rearMatrix35 m20 : 40|8@1+ (1,0) [0|255] "" Vector__XXX
 SG_ LS_rearMatrix36 m20 : 48|8@1+ (1,0) [0|255] "" Vector__XXX
 SG_ LS_rearMatrix37 m20 : 56|8@1+ (1,0) [0|255] "" Vector__XXX
 SG_ LS_rearMatrix38 m21 : 8|8@1+ (1,0) [0|255] "" Vector__XXX
 SG_ LS_rearMatrix39 m21 : 16|8@1+ (1,0) [0|255] "" Vector__XXX
 SG_ LS_rearMatrix40 m21 : 24|8@1+ (1,0) [0|255] "" Vector__XXX
 SG_ LS_rearMatrix41 m21 : 32|8@1+ (1,0) [0|255] "" Vector__XXX
 SG_ LS_rearMatrix42 m21 : 40|8@1+ (1,0) [0|255] "" Vector__XXX
 SG_ LS_rearMatrix43 m21 : 48|8@1+ (1,0) [0|255] "" Vector__XXX
 SG_ LS_rearMatrix44 m21 : 56|8@1+ (1,0) [0|255] "" Vector__XXX
 SG_ LS_rearMatrix45 m22 : 8|8@1+ (1,0) [0|255] "" Vector__XXX
 SG_ LS_rearMatrix46 m22 : 16|8@1+ (1,0) [0|255] "" Vector__XXX
 SG_ LS_rearMatrix47 m22 : 24|8@1+ (1,0) [0|255] "" Vector__XXX
 SG_ LS_rearMatrix48 m22 : 32|8@1+ (1,0) [0|255] "" Vector__XXX
 SG_ LS_rearMatrix49 m22 : 40|8@1+ (1,0) [0|255] "" Vector__XXX
 SG_ LS_rearMatrix50 m22 : 48|8@1+ (1,0) [0|255] "" Vector__XXX
 SG_ LS_rearMatrix51 m22 : 56|8@1+ (1,0) [0|255] "" Vector__XXX
 SG_ LS_rearMatrix52 m23 : 8|8@1+ (1,0) [0|255] "" Vector__XXX
 SG_ LS_rearMatrix53 m23 : 16|8@1+ (1,0) [0|255] "" Vector__XXX
 SG_ LS_rearMatrix54 m23 : 24|8@1+ (1,0) [0|255] "" Vector__XXX
 SG_ LS_rearMatrix55 m23 : 32|8@1+ (1,0) [0|255] "" Vector__XXX
 SG_ LS_rearMatrix56 m23 : 40|8@1+ (1,0) [0|255] "" Vector__XXX
 SG_ LS_rearMatrix57 m23 : 48|8@1+ (1,0) [0|255] "" Vector__XXX
 SG_ LS_rearMatrix58 m23 : 56|8@1+ (1,0) [0|255] "" Vector__XXX
 SG_ LS_rearMatrix59 m24 : 8|8@1+ (1,0) [0|255] "" Vector__XXX
 SG_ LS_offroadLightBar0 m24 : 16|8@1+ (1,0) [0|255] "" Vector__XXX
 SG_ LS_offroadLightBar1 m24 : 24|8@1+ (1,0) [0|255] "" Vector__XXX
 SG_ LS_offroadLightBar2 m24 : 32|8@1+ (1,0) [0|255] "" Vector__XXX
 SG_ LS_offroadLightBar3 m24 : 40|8@1+ (1,0) [0|255] "" Vector__XXX
 SG_ LS_offroadLightBar4 m24 : 48|8@1+ (1,0) [0|255] "" Vector__XXX
 SG_ LS_offroadLightBar5 m24 : 56|8@1+ (1,0) [0|255] "" Vector__XXX

BO_ 1429 OCS1P_alertLog: 8 OCS1P
 SG_ OCS1P_alertID M : 0|8@1+ (1,0) [0|255] "" Vector__XXX
 SG_ OCS1P_alertState : 15|1@1+ (1,0) [0|1] "" Vector__XXX
 SG_ OCS1P_a121_sandwichFreq m121 : 16|32@1+ (1,0) [0|4294967295] "" Vector__XXX
 SG_ OCS1P_a122_sandwichFreq m122 : 16|32@1+ (1,0) [0|4294967295] "" Vector__XXX
 SG_ OCS1P_a123_sandwichFreq m123 : 16|32@1+ (1,0) [0|4294967295] "" Vector__XXX
 SG_ OCS1P_a124_cushionSelfFreq m124 : 16|32@1+ (1,0) [0|4294967295] "" Vector__XXX
 SG_ OCS1P_a125_cushionSelfFreq m125 : 16|32@1+ (1,0) [0|4294967295] "" Vector__XXX
 SG_ OCS1P_a126_cushionSelfFreq m126 : 16|32@1+ (1,0) [0|4294967295] "" Vector__XXX
 SG_ OCS1P_a127_seatbackSelfFreq m127 : 16|32@1+ (1,0) [0|4294967295] "" Vector__XXX
 SG_ OCS1P_a128_seatbackSelfFreq m128 : 16|32@1+ (1,0) [0|4294967295] "" Vector__XXX
 SG_ OCS1P_a129_seatbackSelfFreq m129 : 16|32@1+ (1,0) [0|4294967295] "" Vector__XXX
 SG_ OCS1P_a130_sandwichNoCalib m130 : 16|1@1+ (1,0) [0|1] "" Vector__XXX
 SG_ OCS1P_a131_cushionSelfNoCalib m131 : 16|1@1+ (1,0) [0|1] "" Vector__XXX
 SG_ OCS1P_a132_seatbackSelfNoCalib m132 : 16|1@1+ (1,0) [0|1] "" Vector__XXX
 SG_ OCS1P_a133_sandwichBadCalib m133 : 16|1@1+ (1,0) [0|1] "" Vector__XXX
 SG_ OCS1P_a134_uninitializedCalib m134 : 16|1@1+ (1,0) [0|1] "" Vector__XXX
 SG_ OCS1P_a135_tempNoCalib m135 : 16|1@1+ (1,0) [0|1] "" Vector__XXX
 SG_ OCS1P_a140_tempInvalidCalib m140 : 16|1@1+ (1,0) [0|1] "" Vector__XXX
 SG_ OCS1P_a141_humidityInvalidCalib m141 : 16|1@1+ (1,0) [0|1] "" Vector__XXX
 SG_ OCS1P_a142_tempHumidityInvalid m142 : 16|1@1+ (1,0) [0|1] "" Vector__XXX
 SG_ OCS1P_a143_mismatchPassAirbag m143 : 16|1@1+ (1,0) [0|1] "" Vector__XXX
 SG_ OCS1P_a144_mismatchCarRegion m144 : 16|1@1+ (1,0) [0|1] "" Vector__XXX

BO_ 767 OCS1P_alertMatrix: 8 OCS1P
 SG_ OCS1P_matrixIndex M : 0|4@1+ (1,0) [0|15] "" Vector__XXX
 SG_ OCS1P_w015_NVMMAlert m0 : 18|1@1+ (1,0) [0|1] "" Vector__XXX
 SG_ OCS1P_w121_sandwichOpen m2 : 4|1@1+ (1,0) [0|1] "" Vector__XXX
 SG_ OCS1P_w122_sandwichLow m2 : 5|1@1+ (1,0) [0|1] "" Vector__XXX
 SG_ OCS1P_w123_sandwichShort m2 : 6|1@1+ (1,0) [0|1] "" Vector__XXX
 SG_ OCS1P_w124_cushionSelfOpen m2 : 7|1@1+ (1,0) [0|1] "" Vector__XXX
 SG_ OCS1P_w125_cushionSelfLow m2 : 8|1@1+ (1,0) [0|1] "" Vector__XXX
 SG_ OCS1P_w126_cushionSelfShort m2 : 9|1@1+ (1,0) [0|1] "" Vector__XXX
 SG_ OCS1P_w127_seatbackSelfOpen m2 : 10|1@1+ (1,0) [0|1] "" Vector__XXX
 SG_ OCS1P_w128_seatbackSelfLow m2 : 11|1@1+ (1,0) [0|1] "" Vector__XXX
 SG_ OCS1P_w129_seatbackSelfShort m2 : 12|1@1+ (1,0) [0|1] "" Vector__XXX
 SG_ OCS1P_w130_sandwichNoCalib m2 : 13|1@1+ (1,0) [0|1] "" Vector__XXX
 SG_ OCS1P_w131_cushionSelfNoCalib m2 : 14|1@1+ (1,0) [0|1] "" Vector__XXX
 SG_ OCS1P_w132_seatbackSelfNoCalib m2 : 15|1@1+ (1,0) [0|1] "" Vector__XXX
 SG_ OCS1P_w133_sandwichBadCalib m2 : 16|1@1+ (1,0) [0|1] "" Vector__XXX
 SG_ OCS1P_w134_uninitializedCalib m2 : 17|1@1+ (1,0) [0|1] "" Vector__XXX
 SG_ OCS1P_w135_tempNoCalib m2 : 18|1@1+ (1,0) [0|1] "" Vector__XXX
 SG_ OCS1P_w136_cushionSelfDutyLow m2 : 19|1@1+ (1,0) [0|1] "" Vector__XXX
 SG_ OCS1P_w137_cushionSelfDutyHigh m2 : 20|1@1+ (1,0) [0|1] "" Vector__XXX
 SG_ OCS1P_w138_seatbackSelfDutyLow m2 : 21|1@1+ (1,0) [0|1] "" Vector__XXX
 SG_ OCS1P_w139_seatbackSelfDutyHigh m2 : 22|1@1+ (1,0) [0|1] "" Vector__XXX
 SG_ OCS1P_w140_tempInvalidCalib m2 : 23|1@1+ (1,0) [0|1] "" Vector__XXX
 SG_ OCS1P_w141_humidityInvalidCalib m2 : 24|1@1+ (1,0) [0|1] "" Vector__XXX
 SG_ OCS1P_w142_tempHumidityInvalid m2 : 25|1@1+ (1,0) [0|1] "" Vector__XXX
 SG_ OCS1P_w143_mismatchPassAirbag m2 : 26|1@1+ (1,0) [0|1] "" Vector__XXX
 SG_ OCS1P_w144_mismatchCarRegion m2 : 27|1@1+ (1,0) [0|1] "" Vector__XXX
 SG_ OCS1P_w145_rebaselineTriggered m2 : 28|1@1+ (1,0) [0|1] "" Vector__XXX
 SG_ OCS1P_w148_classificationMismatc m2 : 31|1@1+ (1,0) [0|1] "" Vector__XXX
 SG_ OCS1P_w150_rbEntryTriggered m2 : 33|1@1+ (1,0) [0|1] "" Vector__XXX
 SG_ OCS1P_w151_rbEntryExited m2 : 34|1@1+ (1,0) [0|1] "" Vector__XXX
 SG_ OCS1P_w152_rbExit1Triggered m2 : 35|1@1+ (1,0) [0|1] "" Vector__XXX
 SG_ OCS1P_w153_rbExit1Exited m2 : 36|1@1+ (1,0) [0|1] "" Vector__XXX
 SG_ OCS1P_w154_rbExit2Exited1 m2 : 37|1@1+ (1,0) [0|1] "" Vector__XXX
 SG_ OCS1P_w155_rbExit2Exited2 m2 : 38|1@1+ (1,0) [0|1] "" Vector__XXX
 SG_ OCS1P_w156_seatbeltReminderUnava m2 : 39|1@1+ (1,0) [0|1] "" Vector__XXX

BO_ 766 OCS1P_info: 8 OCS1P
 SG_ OCS1P_infoIndex M : 0|8@1+ (1,0) [0|255] "" Vector__XXX
 SG_ OCS1P_infoBuildType m10 : 8|8@1+ (1,0) [0|255] "" Vector__XXX
 SG_ OCS1P_infoBuildConfigID m10 : 16|16@1+ (1,0) [0|65535] "" Vector__XXX
 SG_ OCS1P_infoHardwareID m10 : 32|16@1+ (1,0) [0|65535] "" Vector__XXX
 SG_ OCS1P_infoComponentID m10 : 48|16@1+ (1,0) [0|65535] "" Vector__XXX
 SG_ OCS1P_infoPcbaID m11 : 16|8@1+ (1,0) [0|255] "" Vector__XXX
 SG_ OCS1P_infoAssemblyID m11 : 24|8@1+ (1,0) [0|255] "" Vector__XXX
 SG_ OCS1P_infoUsageID m11 : 32|16@1+ (1,0) [0|65535] "" Vector__XXX
 SG_ OCS1P_infoSubUsageID m11 : 48|16@1+ (1,0) [0|65535] "" Vector__XXX
 SG_ OCS1P_infoApplicationCRC m13 : 32|32@1+ (1,0) [0|4294967295] "" Vector__XXX
 SG_ OCS1P_infoBootSvnRev m14 : 8|24@1+ (1,0) [0|16777215] "" Vector__XXX
 SG_ OCS1P_infoAppGitHashBytes m17 : 8|56@1+ (1,0) [0|7.20575940379e+16] "" Vector__XXX
 SG_ OCS1P_infoBootGitHashBytes m18 : 8|56@1+ (1,0) [0|7.20575940379e+16] "" Vector__XXX
 SG_ OCS1P_infoPlatformType m19 : 8|8@1+ (1,0) [0|255] "" Vector__XXX
 SG_ OCS1P_infoBootUdsProtoVersion m20 : 8|8@1+ (1,0) [0|255] "" Vector__XXX
 SG_ OCS1P_infoBootloaderCRC m20 : 32|32@1+ (1,0) [0|4294967295] "" Vector__XXX

BO_ 771 OCS1P_status: 8 OCS1P
 SG_ OCS1P_occupantClassification : 0|8@1+ (1,0) [0|255] "" Vector__XXX
 SG_ OCS1P_occupantClassificationQF : 8|1@1+ (1,0) [0|1] "" Vector__XXX
 SG_ OCS1P_occupiedState : 9|2@1+ (1,0) [0|3] "" Vector__XXX
 SG_ OCS1P_triggerSnapshot : 11|5@1+ (1,0) [0|31] "" Vector__XXX
 SG_ OCS1P_occupantClassificationRaw : 16|3@1+ (1,0) [0|7] "" Vector__XXX
 SG_ OCS1P_occupantClassificationSelf : 19|3@1+ (1,0) [0|7] "" Vector__XXX
 SG_ OCS1P_occupantClassificationRawC : 22|3@1+ (1,0) [0|7] "" Vector__XXX
 SG_ OCS1P_occupantClassificationCap : 25|3@1+ (1,0) [0|7] "" Vector__XXX
 SG_ OCS1P_classificationHeld : 30|1@1+ (1,0) [0|1] "" Vector__XXX
 SG_ OCS1P_cushionStable : 31|1@1+ (1,0) [0|1] "" Vector__XXX
 SG_ OCS1P_classificationExtHold : 32|1@1+ (1,0) [0|1] "" Vector__XXX
 SG_ OCS1P_classificationHoldState : 33|3@1+ (1,0) [0|7] "" Vector__XXX
 SG_ OCS1P_classificationVariant : 36|3@1+ (1,0) [0|7] "" Vector__XXX
 SG_ OCS1P_sandwichDisabled : 39|1@1+ (1,0) [0|1] "" Vector__XXX
 SG_ OCS1P_noSandwichType : 40|2@1+ (1,0) [0|3] "" Vector__XXX
 SG_ OCS1P_sandwichBoundaryType : 42|1@1+ (1,0) [0|1] "" Vector__XXX
 SG_ OCS1P_sbrBoundaryType : 43|1@1+ (1,0) [0|1] "" Vector__XXX
 SG_ OCS1P_occupiedStateCap : 45|2@1+ (1,0) [0|3] "" Vector__XXX
 SG_ OCS1P_seatbackStable : 47|1@1+ (1,0) [0|1] "" Vector__XXX
 SG_ OCS1P_sandwichStable : 48|1@1+ (1,0) [0|1] "" Vector__XXX
 SG_ OCS1P_cushionStableCap : 49|1@1+ (1,0) [0|1] "" Vector__XXX
 SG_ OCS1P_seatbackStableCap : 50|1@1+ (1,0) [0|1] "" Vector__XXX
 SG_ OCS1P_classificationHeldCap : 51|1@1+ (1,0) [0|1] "" Vector__XXX
 SG_ OCS1P_statusCounter : 52|4@1+ (1,0) [0|15] "" Vector__XXX
 SG_ OCS1P_statusChecksum : 56|8@1+ (1,0) [0|255] "" Vector__XXX

CM_ BO_ 861 "Electric brake booster message: alert matrix";
CM_ SG_ 861 IBST_matrixIndex "Electric brake booster: matrix index";
CM_ SG_ 861 IBST_a001_microSupplyError "Electric brake booster: a001 micro supply error";
CM_ SG_ 861 IBST_a002_HWBISTError "Electric brake booster: a002 HWBIST error";
CM_ SG_ 861 IBST_a003_RAMFault "Electric brake booster: a003 RAM fault";
CM_ SG_ 861 IBST_a004_flashFault "Electric brake booster: a004 flash fault";
CM_ SG_ 861 IBST_a005_microSafetyFault "Electric brake booster: a005 micro safety fault";
CM_ SG_ 861 IBST_a006_microSafetyLogicFault "Electric brake booster: a006 micro safety logic fault";
CM_ SG_ 861 IBST_a007_RBCPUException "Electric brake booster: a007 RBCPU exception";
CM_ SG_ 861 IBST_a008_stackOverUnderFlow "Electric brake booster: a008 stack over under flow";
CM_ SG_ 861 IBST_a009_systemErrorHook "Electric brake booster: a009 system error hook";
CM_ SG_ 861 IBST_a010_OSErrorHook "Electric brake booster: a010 OS error hook";
CM_ SG_ 861 IBST_a011_systemTaskOverRun "Electric brake booster: a011 system task over run";
CM_ SG_ 861 IBST_a012_OSTaskSchemeError "Electric brake booster: a012 OS task scheme error";
CM_ SG_ 861 IBST_a013_systemTaskJitter "Electric brake booster: a013 system task jitter";
CM_ SG_ 861 IBST_a014_DMATransferError "Electric brake booster: a014 DMA transfer error";
CM_ SG_ 861 IBST_a015_asicOscillatorError "Electric brake booster: a015 asic oscillator error";
CM_ SG_ 861 IBST_a016_RBBLMShaftShiftError "Electric brake booster: a016 RBBLM shaft shift error";
CM_ SG_ 861 IBST_a017_assertionFault "Electric brake booster: a017 assertion fault";
CM_ SG_ 861 IBST_a018_unsupportedHW "Electric brake booster: a018 unsupported HW";
CM_ SG_ 861 IBST_a019_supplyASICInitFault "Electric brake booster: a019 supply ASIC init fault";
CM_ SG_ 861 IBST_a020_VPREU5VOutOfRange "Electric brake booster: a020 VPREU5 v out of range";
CM_ SG_ 861 IBST_a021_IREFOutOfRange "Electric brake booster: a021 IREF out of range";
CM_ SG_ 861 IBST_a022_U5VTestFault "Electric brake booster: a022 U5 v test fault";
CM_ SG_ 861 IBST_a023_U5VOutOfRange "Electric brake booster: a023 U5 v out of range";
CM_ SG_ 861 IBST_a024_chargePumpFault "Electric brake booster: a024 charge pump fault";
CM_ SG_ 861 IBST_a025_ecuClockTestFault "Electric brake booster: a025 ecu clock test fault";
CM_ SG_ 861 IBST_a026_ecuBistCmdTestFault "Electric brake booster: a026 ecu bist cmd test fault";
CM_ SG_ 861 IBST_a027_ecuFastWdTestFault "Electric brake booster: a027 ecu fast wd test fault";
CM_ SG_ 861 IBST_a028_ecuBistFaultCtrFault "Electric brake booster: a028 ecu bist fault ctr fault";
CM_ SG_ 861 IBST_a029_ecuErrpinCounterFault "Electric brake booster: a029 ecu errpin counter fault";
CM_ SG_ 861 IBST_a030_ecuEnableElLowFault "Electric brake booster: a030 ecu enable el low fault";
CM_ SG_ 861 IBST_a031_decoupleBitTestFault "Electric brake booster: a031 decouple bit test fault";
CM_ SG_ 861 IBST_a032_ecuEnableElHighFault "Electric brake booster: a032 ecu enable el high fault";
CM_ SG_ 861 IBST_a033_ecuWdStartuptestFault "Electric brake booster: a033 ecu wd startuptest fault";
CM_ SG_ 861 IBST_a034_ecuEnableHyHighFault "Electric brake booster: a034 ecu enable hy high fault";
CM_ SG_ 861 IBST_a035_ecuEnableHyLowFault "Electric brake booster: a035 ecu enable hy low fault";
CM_ SG_ 861 IBST_a036_MRGPathTestFault "Electric brake booster: a036 MRG path test fault";
CM_ SG_ 861 IBST_a037_ecuWdSContinuousError "Electric brake booster: a037 ecu wd s continuous error";
CM_ SG_ 861 IBST_a038_ecuEnContinuousError "Electric brake booster: a038 ecu en continuous error";
CM_ SG_ 861 IBST_a039_GTMRefFrequencyError "Electric brake booster: a039 GTM ref frequency error";
CM_ SG_ 861 IBST_a040_GTMTbuMonError "Electric brake booster: a040 GTM tbu mon error";
CM_ SG_ 861 IBST_a041_micAsicClkInError "Electric brake booster: a041 mic asic clk in error";
CM_ SG_ 861 IBST_a042_micAsicInitTestError "Electric brake booster: a042 mic asic init test error";
CM_ SG_ 861 IBST_a043_micSpiTransferError "Electric brake booster: a043 mic spi transfer error";
CM_ SG_ 861 IBST_a044_NvMEepromWIP "Electric brake booster: a044 nv m eeprom WIP";
CM_ SG_ 861 IBST_a045_WdhAsicWdErrorCntStuck "Electric brake booster: a045 wdh asic wd error cnt stuck";
CM_ SG_ 861 IBST_a046_WdhAsicWdErrorCntLimit "Electric brake booster: a046 wdh asic wd error cnt limit";
CM_ SG_ 861 IBST_a047_WdhAsicWdCmdMissing "Electric brake booster: a047 wdh asic wd cmd missing";
CM_ SG_ 861 IBST_a048_WdhSwBistConCnt "Electric brake booster: a048 wdh sw bist con cnt";
CM_ SG_ 861 IBST_a049_WdhTaskMonConCnt "Electric brake booster: a049 wdh task mon con cnt";
CM_ SG_ 861 IBST_a050_VPreExternalFeeding "Electric brake booster: a050 v pre external feeding";
CM_ SG_ 861 IBST_a051_ecuBandgap "Electric brake booster: a051 ecu bandgap";
CM_ SG_ 861 IBST_a052_AdcPinTest "Electric brake booster: a052 adc pin test";
CM_ SG_ 861 IBST_a053_AdcSelftestC5P "Electric brake booster: a053 adc selftest C5 p";
CM_ SG_ 861 IBST_a054_AdcPeripheralFault "Electric brake booster: a054 adc peripheral fault";
CM_ SG_ 861 IBST_a055_UB6SupplyPathFault "Electric brake booster: a055 UB6 supply path fault";
CM_ SG_ 861 IBST_a056_UB6PlausiMonFault "Electric brake booster: a056 UB6 plausi mon fault";
CM_ SG_ 861 IBST_a057_microRegisterFault "Electric brake booster: a057 micro register fault";
CM_ SG_ 861 IBST_a058_NvMWriteCycleExceed "Electric brake booster: a058 nv m write cycle exceed";
CM_ SG_ 861 IBST_a059_NvMEepromSize "Electric brake booster: a059 nv m eeprom size";
CM_ SG_ 861 IBST_a060_NvMMigrationFault "Electric brake booster: a060 nv m migration fault";
CM_ SG_ 861 IBST_a061_AswSystemTimeOut "Electric brake booster: a061 asw system time out";
CM_ SG_ 861 IBST_a062_MICB6TransferError "Electric brake booster: a062 MICB6 transfer error";
CM_ SG_ 861 IBST_a063_tempSens2ShortToSupply "Electric brake booster: a063 temp sens2 short to supply";
CM_ SG_ 861 IBST_a064_tempSens1ShortToGround "Electric brake booster: a064 temp sens1 short to ground";
CM_ SG_ 861 IBST_a065_tempSens2ShortToGround "Electric brake booster: a065 temp sens2 short to ground";
CM_ SG_ 861 IBST_a066_tempSens1ShortToSupply "Electric brake booster: a066 temp sens1 short to supply";
CM_ SG_ 861 IBST_a067_tempSensImplausVoltage "Electric brake booster: a067 temp sens implaus voltage";
CM_ SG_ 861 IBST_a068_chargePumpUndervoltage "Electric brake booster: a068 charge pump undervoltage";
CM_ SG_ 861 IBST_a069_greasingRoutineFault "Electric brake booster: a069 greasing routine fault";
CM_ SG_ 861 IBST_a070_notShutDownNvMWrite "Electric brake booster: a070 not shut down nv m write";
CM_ SG_ 861 IBST_a071_notShutDownNvMRead "Electric brake booster: a071 not shut down nv m read";
CM_ SG_ 861 IBST_a072_notShutDownRight "Electric brake booster: a072 not shut down right";
CM_ SG_ 861 IBST_a073_jumpInAdjustNvMRead "Electric brake booster: a073 jump in adjust nv m read";
CM_ SG_ 861 IBST_a074_FindIdleDataNvMWrite "Electric brake booster: a074 find idle data nv m write";
CM_ SG_ 861 IBST_a075_FindIdleRoutineFault "Electric brake booster: a075 find idle routine fault";
CM_ SG_ 861 IBST_a076_masterCylLengthRead "Electric brake booster: a076 master cyl length read";
CM_ SG_ 861 IBST_a077_runOutMotorSaturated "Electric brake booster: a077 run out motor saturated";
CM_ SG_ 861 IBST_a078_wearOffsetCompNVMRead "Electric brake booster: a078 wear offset comp NVM read";
CM_ SG_ 861 IBST_a079_motorTempHighLevel1 "Electric brake booster: a079 motor temp high level1";
CM_ SG_ 861 IBST_a080_motorTempHighLevel2 "Electric brake booster: a080 motor temp high level2";
CM_ SG_ 861 IBST_a081_travelDeviation "Electric brake booster: a081 travel deviation";
CM_ SG_ 861 IBST_a082_motorSpeedDeviation "Electric brake booster: a082 motor speed deviation";
CM_ SG_ 861 IBST_a083_spindlePositionTooHigh "Electric brake booster: a083 spindle position too high";
CM_ SG_ 861 IBST_a084_CANTransceiverHWFault "Electric brake booster: a084 CAN transceiver HW fault";
CM_ SG_ 861 IBST_a085_supplyUndervoltageLvl3 "Electric brake booster: a085 supply undervoltage lvl3";
CM_ SG_ 861 IBST_a086_supplyOvervoltageLvl3 "Electric brake booster: a086 supply overvoltage lvl3";
CM_ SG_ 861 IBST_a087_rotorSinOutOfRangeLow "Electric brake booster: a087 rotor sin out of range low";
CM_ SG_ 861 IBST_a088_rotorCosOutOfRangeLow "Electric brake booster: a088 rotor cos out of range low";
CM_ SG_ 861 IBST_a089_rotorSinOutOfRangeHigh "Electric brake booster: a089 rotor sin out of range high";
CM_ SG_ 861 IBST_a090_rotorCosOutOfRangeHigh "Electric brake booster: a090 rotor cos out of range high";
CM_ SG_ 861 IBST_a091_SMMOneRequestsInit "Electric brake booster: a091 SMM one requests init";
CM_ SG_ 861 IBST_a092_systemStartTimeOut "Electric brake booster: a092 system start time out";
CM_ SG_ 861 IBST_a093_UEXSOvertemperature "Electric brake booster: a093 UEXS overtemperature";
CM_ SG_ 861 IBST_a094_XPASSEchoTimeDeviation "Electric brake booster: a094 XPASS echo time deviation";
CM_ SG_ 861 IBST_a095_XPASSTimeOut "Electric brake booster: a095 XPASS time out";
CM_ SG_ 861 IBST_a096_bridgeDriverMonError "Electric brake booster: a096 bridge driver mon error";
CM_ SG_ 861 IBST_a097_bridgeDriverError "Electric brake booster: a097 bridge driver error";
CM_ SG_ 861 IBST_a098_bridgeShortedPhase "Electric brake booster: a098 bridge shorted phase";
CM_ SG_ 861 IBST_a099_bridgeSwitchInitError "Electric brake booster: a099 bridge switch init error";
CM_ SG_ 861 IBST_a100_current2OffsetHigh "Electric brake booster: a100 current2 offset high";
CM_ SG_ 861 IBST_a101_current2OffsetLow "Electric brake booster: a101 current2 offset low";
CM_ SG_ 861 IBST_a102_current1OffsetHigh "Electric brake booster: a102 current1 offset high";
CM_ SG_ 861 IBST_a103_current1OffsetLow "Electric brake booster: a103 current1 offset low";
CM_ SG_ 861 IBST_a104_bridgeDriverShort "Electric brake booster: a104 bridge driver short";
CM_ SG_ 861 IBST_a105_LiPSUndervoltage "Electric brake booster: a105 li PS undervoltage";
CM_ SG_ 861 IBST_a106_LiPS5VSupply "Electric brake booster: a106 li PS5 v supply";
CM_ SG_ 861 IBST_a107_LiPS2PwmLineHigh "Electric brake booster: a107 li PS2 pwm line high";
CM_ SG_ 861 IBST_a108_LiPS2PwmLineLow "Electric brake booster: a108 li PS2 pwm line low";
CM_ SG_ 861 IBST_a109_LiPS2PwmTransmission "Electric brake booster: a109 li PS2 pwm transmission";
CM_ SG_ 861 IBST_a110_LiPS1SentLineHigh "Electric brake booster: a110 li PS1 sent line high";
CM_ SG_ 861 IBST_a111_LiPS1SentLineLow "Electric brake booster: a111 li PS1 sent line low";
CM_ SG_ 861 IBST_a112_LiPS1SentTransmission "Electric brake booster: a112 li PS1 sent transmission";
CM_ SG_ 861 IBST_a113_LiPS1SentSensor "Electric brake booster: a113 li PS1 sent sensor";
CM_ SG_ 861 IBST_a114_partyBusOff "Electric brake booster: a114 party bus off";
CM_ SG_ 861 IBST_a115_chassisBusOff "Electric brake booster: a115 chassis bus off";
CM_ SG_ 861 IBST_a116_supplyUndervoltageLvl2 "Electric brake booster: a116 supply undervoltage lvl2";
CM_ SG_ 861 IBST_a117_supplyOvervoltageLvl2 "Electric brake booster: a117 supply overvoltage lvl2";
CM_ SG_ 861 IBST_a118_RPSNvMReadFault "Electric brake booster: a118 RPS nv m read fault";
CM_ SG_ 861 IBST_a119_RPSWrongCalibData "Electric brake booster: a119 RPS wrong calib data";
CM_ SG_ 861 IBST_a120_RPSVectorRangeHigh "Electric brake booster: a120 RPS vector range high";
CM_ SG_ 861 IBST_a121_RPSVectorRangeLow "Electric brake booster: a121 RPS vector range low";
CM_ SG_ 861 IBST_a122_RPSVectorOscillating "Electric brake booster: a122 RPS vector oscillating";
CM_ SG_ 861 IBST_a123_bridgeDriverUnavail "Electric brake booster: a123 bridge driver unavail";
CM_ SG_ 861 IBST_a124_OBDCurrent1OORHigh "Electric brake booster: a124 OBD current1 OOR high";
CM_ SG_ 861 IBST_a125_OBDCurrent2OORHigh "Electric brake booster: a125 OBD current2 OOR high";
CM_ SG_ 861 IBST_a126_OBDCurrent1OORLow "Electric brake booster: a126 OBD current1 OOR low";
CM_ SG_ 861 IBST_a127_OBDCurrent2OORLow "Electric brake booster: a127 OBD current2 OOR low";
CM_ SG_ 861 IBST_a128_BLMMuxerTimeoutError "Electric brake booster: a128 BLM muxer timeout error";
CM_ SG_ 861 IBST_a129_loadDumpOnFSLTest "Electric brake booster: a129 load dump on FSL test";
CM_ SG_ 861 IBST_a130_DTSFunctionalRangeLow "Electric brake booster: a130 DTS functional range low";
CM_ SG_ 861 IBST_a131_DTSFunctionalRangeHigh "Electric brake booster: a131 DTS functional range high";
CM_ SG_ 861 IBST_a132_DTSPlausiCheck1vs2 "Electric brake booster: a132 DTS plausi check1vs2";
CM_ SG_ 861 IBST_a133_DTSOffsetTooLow "Electric brake booster: a133 DTS offset too low";
CM_ SG_ 861 IBST_a134_DTSOffsetTooHigh "Electric brake booster: a134 DTS offset too high";
CM_ SG_ 861 IBST_a135_ESPparty1DLC "Electric brake booster: a135 ES pparty1 DLC";
CM_ SG_ 861 IBST_a136_ESPparty1Timeout "Electric brake booster: a136 ES pparty1 timeout";
CM_ SG_ 861 IBST_a137_ESPparty1Checksum "Electric brake booster: a137 ES pparty1 checksum";
CM_ SG_ 861 IBST_a138_ESPparty1Counter "Electric brake booster: a138 ES pparty1 counter";
CM_ SG_ 861 IBST_a139_ESPparty2DLC "Electric brake booster: a139 ES pparty2 DLC";
CM_ SG_ 861 IBST_a140_ESPparty2Timeout "Electric brake booster: a140 ES pparty2 timeout";
CM_ SG_ 861 IBST_a141_ESPparty2Checksum "Electric brake booster: a141 ES pparty2 checksum";
CM_ SG_ 861 IBST_a142_ESPparty2Counter "Electric brake booster: a142 ES pparty2 counter";
CM_ SG_ 861 IBST_a143_ESPparty3DLC "Electric brake booster: a143 ES pparty3 DLC";
CM_ SG_ 861 IBST_a144_ESPparty3Timeout "Electric brake booster: a144 ES pparty3 timeout";
CM_ SG_ 861 IBST_a145_ESPparty3Checksum "Electric brake booster: a145 ES pparty3 checksum";
CM_ SG_ 861 IBST_a146_ESPparty3Counter "Electric brake booster: a146 ES pparty3 counter";
CM_ SG_ 861 IBST_a147_PSCMotorSizeReadFault "Electric brake booster: a147 PSC motor size read fault";
CM_ SG_ 861 IBST_a148_MLIGainMechReadFault "Electric brake booster: a148 MLI gain mech read fault";
CM_ SG_ 861 IBST_a149_MLITMCAreaReadFault "Electric brake booster: a149 MLITMC area read fault";
CM_ SG_ 861 IBST_a150_motorTestFault "Electric brake booster: a150 motor test fault";
CM_ SG_ 861 IBST_a151_PSCGearRatioReadFault "Electric brake booster: a151 PSC gear ratio read fault";
CM_ SG_ 861 IBST_a152_PSCVoltageImplausible "Electric brake booster: a152 PSC voltage implausible";
CM_ SG_ 861 IBST_a153_unused "Electric brake booster: a153 unused";
CM_ SG_ 861 IBST_a154_unused "Electric brake booster: a154 unused";
CM_ SG_ 861 IBST_a155_supplyUndervoltageLvl1 "Electric brake booster: a155 supply undervoltage lvl1";
CM_ SG_ 861 IBST_a156_supplyOvervoltageLvl1 "Electric brake booster: a156 supply overvoltage lvl1";
CM_ SG_ 861 IBST_a157_masterCylPressInvalid "Electric brake booster: a157 master cyl press invalid";
CM_ SG_ 861 IBST_a158_DTSOffsHighSuspicious "Electric brake booster: a158 DTS offs high suspicious";
CM_ SG_ 861 IBST_a159_FindIdleNvMReadError "Electric brake booster: a159 find idle nv m read error";
CM_ SG_ 861 IBST_a160_DTSIDTimeOut "Electric brake booster: a160 DTSID time out";
CM_ SG_ 861 IBST_a161_powerPackMismatch "Electric brake booster: a161 power pack mismatch";
CM_ SG_ 861 IBST_a162_idlePosNotDetected "Electric brake booster: a162 idle pos not detected";
CM_ SG_ 861 IBST_a163_ESPpEstMaxInvalid "Electric brake booster: a163 ES pp est max invalid";
CM_ SG_ 861 IBST_a164_ESPVehicleSpeedInvalid "Electric brake booster: a164 ESP vehicle speed invalid";
CM_ SG_ 861 IBST_a165_ESPpForceBlendInvalid "Electric brake booster: a165 ES pp force blend invalid";
CM_ SG_ 861 IBST_a166_ESPpMcVirtualInvalid "Electric brake booster: a166 ES pp mc virtual invalid";
CM_ SG_ 861 IBST_a167_ESPqTargetExterInvalid "Electric brake booster: a167 ES pq target exter invalid";
CM_ SG_ 861 IBST_a168_CANOvervoltage "Electric brake booster: a168 CAN overvoltage";
CM_ SG_ 861 IBST_a169_CANUndervoltage "Electric brake booster: a169 CAN undervoltage";
CM_ SG_ 861 IBST_a170_LVPowerStateTimeout "Electric brake booster: a170 LV power state timeout";
CM_ SG_ 861 IBST_a171_LVPowerStateChecksum "Electric brake booster: a171 LV power state checksum";
CM_ SG_ 861 IBST_a172_LVPowerStateDLC "Electric brake booster: a172 LV power state DLC";
CM_ SG_ 861 IBST_a173_LVPowerStateCounter "Electric brake booster: a173 LV power state counter";
CM_ SG_ 861 IBST_a174_LVOffStateInvalid "Electric brake booster: a174 LV off state invalid";
CM_ SG_ 861 IBST_a175_LVGoingDownInvalid "Electric brake booster: a175 LV going down invalid";
CM_ SG_ 861 IBST_a176_blockedPedalDetected "Electric brake booster: a176 blocked pedal detected";
CM_ SG_ 861 IBST_a177_EPBLsystemStatusMIA "Electric brake booster: a177 EPB lsystem status MIA";
CM_ SG_ 861 IBST_a178_EPBRsystemStatusMIA "Electric brake booster: a178 EPB rsystem status MIA";
CM_ SG_ 861 IBST_a179_VCLEFTepbmStatusMIA "Electric brake booster: a179 VCLEF tepbm status MIA";
CM_ SG_ 861 IBST_a180_VCRIGHTepbmStatusMIA "Electric brake booster: a180 VCRIGH tepbm status MIA";
CM_ SG_ 861 IBST_a181_DIchassisControlDLC "Electric brake booster: a181 d ichassis control DLC";
CM_ SG_ 861 IBST_a182_DIchassisControlTimeou "Electric brake booster: a182 d ichassis control timeout";
CM_ SG_ 861 IBST_a183_DIchassisControlChecks "Electric brake booster: a183 d ichassis control checksum";
CM_ SG_ 861 IBST_a184_DIchassisControlCounte "Electric brake booster: a184 d ichassis control counter";
CM_ SG_ 861 IBST_a185_rightBusOff "Electric brake booster: a185 right bus off";
CM_ SG_ 861 IBST_a186_rightBusPassive "Electric brake booster: a186 right bus passive";
CM_ SG_ 861 IBST_a187_brakeBusOff "Electric brake booster: a187 brake bus off";
CM_ SG_ 861 IBST_a188_brakeBusPassive "Electric brake booster: a188 brake bus passive";
CM_ SG_ 861 IBST_a189_rightVCLVPowerStateTim "Electric brake booster: a189 right VCLV power state timeout";
CM_ SG_ 861 IBST_a190_rightVCLVPowerStateDLC "Electric brake booster: a190 right VCLV power state DLC";
CM_ SG_ 861 IBST_a191_rightVCLVPowerStateChe "Electric brake booster: a191 right VCLV power state checksum";
CM_ SG_ 861 IBST_a192_rightVCLVPowerStateCou "Electric brake booster: a192 right VCLV power state counter";
CM_ SG_ 861 IBST_a193_leftVCLVPowerStateTime "Electric brake booster: a193 left VCLV power state timeout";
CM_ SG_ 861 IBST_a194_leftVCLVPowerStateChec "Electric brake booster: a194 left VCLV power state checksum";
CM_ SG_ 861 IBST_a195_leftVCLVPowerStateDLC "Electric brake booster: a195 left VCLV power state DLC";
CM_ SG_ 861 IBST_a196_leftVCLVPowerStateCoun "Electric brake booster: a196 left VCLV power state counter";
CM_ SG_ 861 IBST_a197_brakeLatencyReductionA "Electric brake booster: a197 brake latency reduction active";
CM_ SG_ 861 IBST_a198_aesActive "Electric brake booster: a198 aes active";
CM_ SG_ 861 IBST_a199_undefinedAlertDetected "Electric brake booster: a199 undefined alert detected";
CM_ SG_ 861 IBST_a200_aesFault "Electric brake booster: a200 aes fault";
CM_ SG_ 861 IBST_a201_EGGREAR1wheelSpeedsRea "Electric brake booster: a201 eggrear1wheel speeds rear time out";
CM_ SG_ 861 IBST_a202_EGGREAR1wheelSpeedsRea "Electric brake booster: a202 eggrear1wheel speeds rear checksum";
CM_ SG_ 861 IBST_a203_EGGREAR1wheelSpeedsRea "Electric brake booster: a203 eggrear1wheel speeds rear DLC";
CM_ SG_ 861 IBST_a204_EGGREAR1wheelSpeedsRea "Electric brake booster: a204 eggrear1wheel speeds rear counter";
CM_ SG_ 861 IBST_a205_EGGRIGHT1wheelSpeedsFr "Electric brake booster: a205 eggright1wheel speeds front time out";
CM_ SG_ 861 IBST_a206_EGGRIGHT1wheelSpeedsFr "Electric brake booster: a206 eggright1wheel speeds front checksum";
CM_ SG_ 861 IBST_a207_EGGRIGHT1wheelSpeedsFr "Electric brake booster: a207 eggright1wheel speeds front DLC";
CM_ SG_ 861 IBST_a208_EGGRIGHT1wheelSpeedsFr "Electric brake booster: a208 eggright1wheel speeds front counter";
CM_ SG_ 861 IBST_a209_reducedBrakePowerActiv "Electric brake booster: a209 reduced brake power active";
CM_ SG_ 861 IBST_a210_reducedBrakePowerNotAv "Electric brake booster: a210 reduced brake power not available";
CM_ SG_ 861 IBST_a211_DETReportError "Electric brake booster: a211 DET report error";
CM_ SG_ 861 IBST_a212_infoFailureWrongCUBASH "Electric brake booster: a212 info failure wrong CUBAS handling detected";
CM_ SG_ 861 IBST_a213_PDURouterinitializatio "Electric brake booster: a213 PDU routerinitialization failed";
CM_ SG_ 861 IBST_a214_LossOfPDUInstanceDetec "Electric brake booster: a214 loss of PDU instance detected";
CM_ SG_ 861 IBST_a215_UnsupportedSeriesHWDet "Electric brake booster: a215 unsupported series HW detected";
CM_ SG_ 861 IBST_a216_AsicMalfunctionDetecte "Electric brake booster: a216 asic malfunction detected";
CM_ SG_ 861 IBST_a217_AsicTrimmingNotComplet "Electric brake booster: a217 asic trimming not completed";
CM_ SG_ 861 IBST_a218_uCSafetyNotificationGR "Electric brake booster: a218 u c safety notification GRAM";
CM_ SG_ 861 IBST_a219_uCSafetyNotification "Electric brake booster: a219 u c safety notification";
CM_ SG_ 861 IBST_a220_ASICOvercurrentOnGPIO2 "Electric brake booster: a220 ASIC overcurrent on GPIO250 2";
CM_ SG_ 861 IBST_a221_ASICOvercurrentOnGPIO2 "Electric brake booster: a221 ASIC overcurrent on GPIO250 1";
CM_ SG_ 861 IBST_a222_ASICOvercurrentOnGPIO5 "Electric brake booster: a222 ASIC overcurrent on GPIO50 4";
CM_ SG_ 861 IBST_a223_ASICOvercurrentOnGPIO5 "Electric brake booster: a223 ASIC overcurrent on GPIO50 3";
CM_ SG_ 861 IBST_a224_ASICOvercurrentOnGPIO5 "Electric brake booster: a224 ASIC overcurrent on GPIO50 2";
CM_ SG_ 861 IBST_a225_ASICOvercurrentOnGPIO5 "Electric brake booster: a225 ASIC overcurrent on GPIO50 1";
CM_ SG_ 861 IBST_a226_ASICOvercurrentOnWRHS "Electric brake booster: a226 ASIC overcurrent on WRHS";
CM_ SG_ 861 IBST_a227_wakeRequestMismatchDet "Electric brake booster: a227 wake request mismatch detected";
CM_ SG_ 861 IBST_a228_BlockedPedalDetectedDu "Electric brake booster: a228 blocked pedal detected during HAD";
CM_ SG_ 861 IBST_a229_BlockedPedalDetected "Electric brake booster: a229 blocked pedal detected";
CM_ SG_ 861 IBST_a230_DTS2FunctionalRangeLow "Electric brake booster: a230 DTS2 functional range low";
CM_ SG_ 861 IBST_a231_DTS2FunctionalRangeLow "Electric brake booster: a231 DTS2 functional range low";
CM_ SG_ 861 IBST_a232_PostAssemblyRoutineFai "Electric brake booster: a232 post assembly routine failed";
CM_ SG_ 861 IBST_a233_ReferenceRunAbortByECU "Electric brake booster: a233 reference run abort by ECU reset";
CM_ SG_ 861 IBST_a234_LiPSOutOfRangeHigh "Electric brake booster: a234 li PS out of range high";
CM_ SG_ 861 IBST_a235_LiPSOutOfRangeLow "Electric brake booster: a235 li PS out of range low";
CM_ SG_ 861 IBST_a246_DASredundantBrakingCon "Electric brake booster: a246 DA sredundant braking control party checksum";
CM_ SG_ 861 IBST_a247_DASredundantBrakingCon "Electric brake booster: a247 DA sredundant braking control party counter";
CM_ SG_ 861 IBST_a248_DASredundantBrakingCon "Electric brake booster: a248 DA sredundant braking control party DLC";
CM_ SG_ 861 IBST_a249_DASredundantBrakingCon "Electric brake booster: a249 DA sredundant braking control party timeout";
CM_ SG_ 861 IBST_a250_DASredundantBrakingCon "Electric brake booster: a250 DA sredundant braking control chassis checksum";
CM_ SG_ 861 IBST_a251_DASredundantBrakingCon "Electric brake booster: a251 DA sredundant braking control chassis counter";
CM_ SG_ 861 IBST_a252_DASredundantBrakingCon "Electric brake booster: a252 DA sredundant braking control chassis DLC";
CM_ SG_ 861 IBST_a253_DASredundantBrakingCon "Electric brake booster: a253 DA sredundant braking control chassis timeout";
CM_ SG_ 861 IBST_a254_DIlocStatus2Checksum "Electric brake booster: a254 d iloc status2 checksum";
CM_ SG_ 861 IBST_a255_DIlocStatus2Counter "Electric brake booster: a255 d iloc status2 counter";
CM_ SG_ 861 IBST_a256_DIlocStatus2DLC "Electric brake booster: a256 d iloc status2 DLC";
CM_ SG_ 861 IBST_a257_DIlocStatus2Timeout "Electric brake booster: a257 d iloc status2 timeout";
CM_ SG_ 861 IBST_a258_standaloneEBRActive "Electric brake booster: a258 standalone EBR active";
CM_ SG_ 861 IBST_a259_EMCMain11Checksum "Electric brake booster: a259 EMC main11 checksum";
CM_ SG_ 861 IBST_a260_EMCMain11Counter "Electric brake booster: a260 EMC main11 counter";
CM_ SG_ 861 IBST_a261_EMCMain11DLC "Electric brake booster: a261 EMC main11 DLC";
CM_ SG_ 861 IBST_a262_EMCMain11Timeout "Electric brake booster: a262 EMC main11 timeout";
CM_ SG_ 861 IBST_a263_EMCMain21Checksum "Electric brake booster: a263 EMC main21 checksum";
CM_ SG_ 861 IBST_a264_EMCMain21Counter "Electric brake booster: a264 EMC main21 counter";
CM_ SG_ 861 IBST_a265_EMCMain21DLC "Electric brake booster: a265 EMC main21 DLC";
CM_ SG_ 861 IBST_a266_EMCMain21Timeout "Electric brake booster: a266 EMC main21 timeout";
CM_ BO_ 813 "Electric brake booster message: info";
CM_ SG_ 813 IBST_infoIndex "Electric brake booster: info index";
CM_ SG_ 813 IBST_infoBuildType "Electric brake booster: info build type";
CM_ SG_ 813 IBST_infoComponentID "Electric brake booster: info component ID";
CM_ SG_ 813 IBST_infoPcbaID "Electric brake booster: info pcba ID";
CM_ SG_ 813 IBST_infoAssemblyID "Electric brake booster: info assembly ID";
CM_ SG_ 813 IBST_infoUsageID "Electric brake booster: info usage ID";
CM_ SG_ 813 IBST_infoSubUsageID "Electric brake booster: info sub usage ID";
CM_ SG_ 813 IBST_infoApplicationCRC "Indicating the Application CRC value of firmware running in system.";
CM_ SG_ 813 IBST_infoBootUdsProtoVersion "Electric brake booster: info boot uds proto version";
CM_ SG_ 813 IBST_infoBootloaderCRC "Electric brake booster: info bootloader CRC";
CM_ SG_ 813 IBST_infoVariantCRC "Indicating the Calibration CRC value of firmware running in system.";
CM_ BO_ 925 "Electric brake booster message: status";
CM_ SG_ 925 IBST_statusChecksum "Electric brake booster: status checksum";
CM_ SG_ 925 IBST_statusCounter "Electric brake booster: status counter";
CM_ SG_ 925 IBST_iBoosterStatus "Indication of iBooster functional state";
CM_ SG_ 925 IBST_driverBrakeApply "Indicates when the driver applies the brake pedal.";
CM_ SG_ 925 IBST_internalState "Indication of iBooster internal state";
CM_ SG_ 925 IBST_sInputRodDriver "IBST estimated input rod stroke";
CM_ SG_ 925 IBST_LVPowerModeState "Electric brake booster: LV power mode state";
CM_ BO_ 1208 "ICR ECU message: alert log";
CM_ SG_ 1208 ICR_alertID "ICR ECU: alert ID";
CM_ SG_ 1208 ICR_alertState "ICR ECU: alert state";
CM_ SG_ 1208 ICR_a001_watchdogTaskAppDPM "ICR ECU: a001 watchdog task app DPM";
CM_ SG_ 1208 ICR_a001_watchdogTaskMMWControl "ICR ECU: a001 watchdog task MMW control";
CM_ SG_ 1208 ICR_a001_watchdogTaskSentinelInt "ICR ECU: a001 watchdog task sentinel interface";
CM_ SG_ 1208 ICR_a001_watchdogTaskSentinelMod "ICR ECU: a001 watchdog task sentinel mode change";
CM_ SG_ 1208 ICR_a001_watchdogTaskComTXRAD "ICR ECU: a001 watchdog task com TXRAD";
CM_ SG_ 1208 ICR_a001_watchdogTaskComRX "ICR ECU: a001 watchdog task com RX";
CM_ SG_ 1208 ICR_a001_watchdogTaskComTXVEH "ICR ECU: a001 watchdog task com TXVEH";
CM_ SG_ 1208 ICR_a001_watchdogTaskComUDS "ICR ECU: a001 watchdog task com UDS";
CM_ SG_ 1208 ICR_a001_watchdogTaskCommonError "ICR ECU: a001 watchdog task common error";
CM_ SG_ 1208 ICR_a001_watchdogTaskUARTLog "ICR ECU: a001 watchdog task UART log";
CM_ SG_ 1208 ICR_a001_watchdogTaskDataDump "ICR ECU: a001 watchdog task data dump";
CM_ SG_ 1208 ICR_a001_watchdogRTOSAppRun10MS "ICR ECU: a001 watchdog RTOS app run10 MS";
CM_ SG_ 1208 ICR_a001_watchdogRTOSAppRun1MS "ICR ECU: a001 watchdog RTOS app run1 MS";
CM_ SG_ 1208 ICR_a001_InternalWatchdog "ICR ECU: a001 internal watchdog";
CM_ SG_ 1208 ICR_a015_NVMMMemOverflow "ICR ECU: a015 NVMM mem overflow";
CM_ SG_ 1208 ICR_a015_NVMMFilesystemError "ICR ECU: a015 NVMM filesystem error";
CM_ SG_ 1208 ICR_a015_NVMMRecordIDError "ICR ECU: a015 NVMM record ID error";
CM_ SG_ 1208 ICR_a059_voltageDrop "ICR ECU: a059 voltage drop";
CM_ SG_ 1208 ICR_a059_resistanceEstimate "ICR ECU: a059 resistance estimate";
CM_ SG_ 1208 ICR_a059_current "ICR ECU: a059 current";
CM_ SG_ 1208 ICR_a063_switchChannel "ICR ECU: a063 switch channel";
CM_ SG_ 1208 ICR_a063_switchType "ICR ECU: a063 switch type";
CM_ SG_ 1208 ICR_a063_ADCVoltage "ICR ECU: a063 ADC voltage";
CM_ SG_ 1208 ICR_a063_disconnected "ICR ECU: a063 disconnected";
CM_ SG_ 1208 ICR_a063_indeterminate "ICR ECU: a063 indeterminate";
CM_ SG_ 1208 ICR_a063_stuckActive "ICR ECU: a063 stuck active";
CM_ SG_ 1208 ICR_a063_faulted "ICR ECU: a063 faulted";
CM_ SG_ 1208 ICR_a133_nearClutter "ICR ECU: a133 near clutter";
CM_ SG_ 1208 ICR_a133_farClutter "ICR ECU: a133 far clutter";
CM_ SG_ 1208 ICR_a137_nearClutter "ICR ECU: a137 near clutter";
CM_ SG_ 1208 ICR_a137_farClutter "ICR ECU: a137 far clutter";
CM_ SG_ 1208 ICR_a139_nearClutter "ICR ECU: a139 near clutter";
CM_ SG_ 1208 ICR_a139_farClutter "ICR ECU: a139 far clutter";
CM_ SG_ 1208 ICR_a141_pmicQualityExcursion "ICR ECU: a141 pmic quality excursion";
CM_ SG_ 1208 ICR_a141_calDataNotCalibratedOrP "ICR ECU: a141 cal data not calibrated or processing";
CM_ SG_ 1208 ICR_a141_calDataValRXPhaseAboveM "ICR ECU: a141 cal data val RX phase above max";
CM_ SG_ 1208 ICR_a141_calDataValRXPhaseMissin "ICR ECU: a141 cal data val RX phase missing unit mag";
CM_ SG_ 1208 ICR_a141_calDataValRangeBiasAbov "ICR ECU: a141 cal data val range bias above max";
CM_ BO_ 2028 "ICR ECU message: alert matrix";
CM_ SG_ 2028 ICR_matrixIndex "ICR ECU: matrix index";
CM_ SG_ 2028 ICR_a001_WatchdogReset "ICR ECU: a001 watchdog reset";
CM_ SG_ 2028 ICR_a002_PowerLossReset "ICR ECU: a002 power loss reset";
CM_ SG_ 2028 ICR_a003_SWAssertion "ICR ECU: a003 SW assertion";
CM_ SG_ 2028 ICR_a005_CANTXError "ICR ECU: a005 CANTX error";
CM_ SG_ 2028 ICR_a006_CANTX_cyclicError "ICR ECU: a006 CANTX cyclic error";
CM_ SG_ 2028 ICR_a012_CPUReset "ICR ECU: a012 CPU reset";
CM_ SG_ 2028 ICR_a013_AlertManagerFault "ICR ECU: a013 alert manager fault";
CM_ SG_ 2028 ICR_a015_NVMMError "ICR ECU: a015 NVMM error";
CM_ SG_ 2028 ICR_a016_NVMMRecordError "ICR ECU: a016 NVMM record error";
CM_ SG_ 2028 ICR_a021_TaskSchedulerError "ICR ECU: a021 task scheduler error";
CM_ SG_ 2028 ICR_a022_TaskInitError "ICR ECU: a022 task init error";
CM_ SG_ 2028 ICR_a029_CoreDump "ICR ECU: a029 core dump";
CM_ SG_ 2028 ICR_a030_ECULogUploadRequest "ICR ECU: a030 ECU log upload request";
CM_ SG_ 2028 ICR_a031_UDSActive "ICR ECU: a031 UDS active";
CM_ SG_ 2028 ICR_a041_HighCPULoad "ICR ECU: a041 high CPU load";
CM_ SG_ 2028 ICR_a042_HighStackUsage "ICR ECU: a042 high stack usage";
CM_ SG_ 2028 ICR_a043_Task1msError "ICR ECU: a043 task1ms error";
CM_ SG_ 2028 ICR_a044_Task10msError "ICR ECU: a044 task10ms error";
CM_ SG_ 2028 ICR_a045_Task100msError "ICR ECU: a045 task100ms error";
CM_ SG_ 2028 ICR_a046_Task1000msError "ICR ECU: a046 task1000ms error";
CM_ SG_ 2028 ICR_a058_inputRHighSyncDebug "ICR ECU: a058 input r high sync debug";
CM_ SG_ 2028 ICR_a059_inputResistanceHigh "ICR ECU: a059 input resistance high";
CM_ SG_ 2028 ICR_a060_engineeringBuild "ICR ECU: a060 engineering build";
CM_ SG_ 2028 ICR_a061_XCPConnected "ICR ECU: a061 XCP connected";
CM_ SG_ 2028 ICR_a062_XCPWasConnected "ICR ECU: a062 XCP was connected";
CM_ SG_ 2028 ICR_a063_SwitchFault "ICR ECU: a063 switch fault";
CM_ SG_ 2028 ICR_a064_busSleepReqTimeout "ICR ECU: a064 bus sleep req timeout";
CM_ SG_ 2028 ICR_a133_radarBlocked "ICR ECU: a133 radar blocked";
CM_ SG_ 2028 ICR_a134_radarPgood "ICR ECU: a134 radar pgood";
CM_ SG_ 2028 ICR_a135_radarTxBallBreak "ICR ECU: a135 radar tx ball break";
CM_ SG_ 2028 ICR_a136_radarHighTemperature "ICR ECU: a136 radar high temperature";
CM_ SG_ 2028 ICR_a137_radarBlocked "ICR ECU: a137 radar blocked";
CM_ SG_ 2028 ICR_a138_DriverSideMismatch "ICR ECU: a138 driver side mismatch";
CM_ SG_ 2028 ICR_a139_AbnormalBlockageDetecte "ICR ECU: a139 abnormal blockage detected";
CM_ SG_ 2028 ICR_a140_OccupancyExceptionEncou "ICR ECU: a140 occupancy exception encountered";
CM_ SG_ 2028 ICR_a141_RequiresReplacement "ICR ECU: a141 requires replacement";
CM_ SG_ 2028 ICR_a142_ModeOverrideActive "ICR ECU: a142 mode override active";
CM_ SG_ 2028 ICR_a143_DSPCoreSkipped "ICR ECU: a143 DSP core skipped";
CM_ SG_ 2028 ICR_a144_OccupancyNotificationAl "ICR ECU: a144 occupancy notification alert";
CM_ BO_ 941 "ICR ECU message: info";
CM_ SG_ 941 ICR_infoIndex "ICR ECU: info index";
CM_ SG_ 941 ICR_infoBuildType "ICR ECU: info build type";
CM_ SG_ 941 ICR_infoPcbaId "ICR ECU: info pcba id";
CM_ SG_ 941 ICR_infoAssemblyId "ICR ECU: info assembly id";
CM_ SG_ 941 ICR_infoUsageId "ICR ECU: info usage id";
CM_ SG_ 941 ICR_infoAppCrc "ICR ECU: info app crc";
CM_ SG_ 941 ICR_infoBoardPartNumber17 "ICR ECU: info board part number17";
CM_ SG_ 941 ICR_infoBoardPartNumber814 "ICR ECU: info board part number814";
CM_ SG_ 941 ICR_infoBoardPartNumber1520 "ICR ECU: info board part number1520";
CM_ BO_ 667 "ICR ECU message: non localized occupancy";
CM_ SG_ 667 ICR_lifePresenceMLOutput "ICR ECU: life presence ML output";
CM_ SG_ 667 ICR_largeOccupantPresenceMLOutpu "ICR ECU: large occupant presence ML output";
CM_ SG_ 667 ICR_lifePresenceRaw "ICR ECU: life presence raw";
CM_ SG_ 667 ICR_lifePresenceFilt "ICR ECU: life presence filt";
CM_ SG_ 667 ICR_largeOccupantPresenceRaw "ICR ECU: large occupant presence raw";
CM_ SG_ 667 ICR_largeOccupantPresenceFilt "Indicates the filtered detection status of the Large Occupant Presence Detection feature.";
CM_ SG_ 667 ICR_childPresenceFunctionality "The functionality of the child presence detection app on ICR";
CM_ SG_ 667 ICR_userPresenceFunctionality "ICR ECU: user presence functionality";
CM_ SG_ 667 ICR_userPresenceMLOutput "ICR ECU: user presence ML output";
CM_ SG_ 667 ICR_userPresenceRaw "ICR ECU: user presence raw";
CM_ SG_ 667 ICR_userPresenceFilt "Detection status of User Presence Detection feature";
CM_ BO_ 2027 "ICR ECU message: occupancy";
CM_ SG_ 2027 ICR_occupancy1LRaw "(Non-Functional Interface) Occupancy detection status of First Row left seat";
CM_ SG_ 2027 ICR_occupancy1RRaw "(Non-Functional Interface) Occupancy detection status of First Row right seat";
CM_ SG_ 2027 ICR_occupancy1LVoteCnt "ICR ECU: occupancy1 l vote cnt";
CM_ SG_ 2027 ICR_occupancy1RVoteCnt "ICR ECU: occupancy1 r vote cnt";
CM_ SG_ 2027 ICR_occupancy1LFilt "(Non-Functional Interface) Occupancy detection status of First Row left seat";
CM_ SG_ 2027 ICR_occupancy1RFilt "(Non-Functional Interface) Occupancy detection status of First Row right seat";
CM_ SG_ 2027 ICR_occupancy2LFilt "ICR ECU: occupancy2 l filt";
CM_ SG_ 2027 ICR_occupancy2CFilt "ICR ECU: occupancy2 c filt";
CM_ SG_ 2027 ICR_occupancy2RFilt "ICR ECU: occupancy2 r filt";
CM_ SG_ 2027 ICR_occupancy1RFiltExp "ICR ECU: occupancy1 r filt exp";
CM_ SG_ 2027 ICR_occupancyCounter "ICR ECU: occupancy counter";
CM_ SG_ 2027 ICR_occupancyChecksum "ICR ECU: occupancy checksum";
CM_ BO_ 670 "ICR ECU message: occupancy2";
CM_ SG_ 670 ICR_classification1RFilt "Occupant classification status of First Row Right seat";
CM_ SG_ 670 ICR_classification1LRaw "ICR ECU: classification1 l raw";
CM_ SG_ 670 ICR_classification1RRaw "ICR ECU: classification1 r raw";
CM_ SG_ 670 ICR_classification1LMLOutput "ICR ECU: classification1 LML output";
CM_ SG_ 670 ICR_classification1RMLOutput "ICR ECU: classification1 RML output";
CM_ SG_ 670 ICR_classification1LqF "ICR ECU: classification1 lq f";
CM_ SG_ 670 ICR_blockageClutterFar "The far clutter output of the blockage algorithm";
CM_ SG_ 670 ICR_blockageClutterNear "The near clutter output of the blockage algorithm";
CM_ SG_ 670 ICR_classification1LFilt "ICR ECU: classification1 l filt";
CM_ SG_ 670 ICR_classification1RqF "ICR ECU: classification1 rq f";
CM_ SG_ 670 ICR_classification1LLatched "ICR ECU: classification1 l latched";
CM_ SG_ 670 ICR_classification1RLatched "ICR ECU: classification1 r latched";
CM_ SG_ 670 ICR_classification1LIsLatched "ICR ECU: classification1 l is latched";
CM_ SG_ 670 ICR_classification1RIsLatched "ICR ECU: classification1 r is latched";
CM_ SG_ 670 ICR_occupancy2Counter "ICR ECU: occupancy2 counter";
CM_ SG_ 670 ICR_occupancy2Checksum "ICR ECU: occupancy2 checksum";
CM_ BO_ 2025 "ICR ECU message: status";
CM_ SG_ 2025 ICR_sensorMode "ICR ECU: sensor mode";
CM_ SG_ 2025 ICR_blocked "Indicates if sensor is blocked or not";
CM_ SG_ 2025 ICR_booted "Indicates if ICR has rebooted";
CM_ SG_ 2025 ICR_rdMapDumpCompleted "ICR ECU: rd map dump completed";
CM_ SG_ 2025 ICR_algoVersion "ICR ECU: algo version";
CM_ SG_ 2025 ICR_l2HeapUsage "ICR ECU: l2 heap usage";
CM_ SG_ 2025 ICR_intrusionStatus "ICR ECU: intrusion status";
CM_ SG_ 2025 ICR_blockageScaledMLOutput "Indicates a scaled blockage ML Output";
CM_ BO_ 1470 "IDB ECU message: alert log";
CM_ SG_ 1470 IDB_alertID "IDB ECU: alert ID";
CM_ SG_ 1470 IDB_alertState "IDB ECU: alert state";
CM_ SG_ 1470 IDB_a014_wheelSpeedSensorFreq "IDB ECU: a014 wheel speed sensor freq";
CM_ SG_ 1470 IDB_a014_wheelSpeedSensorPhase "IDB ECU: a014 wheel speed sensor phase";
CM_ SG_ 1470 IDB_a014_wheelSpeedSensorMisinst "IDB ECU: a014 wheel speed sensor misinstallation";
CM_ SG_ 1470 IDB_a014_wheelSpeedSensorWrongEx "IDB ECU: a014 wheel speed sensor wrong exciter";
CM_ SG_ 1470 IDB_a014_wheelSpeedSensorSpeedJu "IDB ECU: a014 wheel speed sensor speed jump minus";
CM_ SG_ 1470 IDB_a014_wheelSpeedSensorSp_0001 "IDB ECU: a014 wheel speed sensor speed jump plus";
CM_ SG_ 1470 IDB_a014_wheelSpeedSensorAirGap "IDB ECU: a014 wheel speed sensor air gap";
CM_ SG_ 1470 IDB_a014_wheelSpeedSensorBIST "IDB ECU: a014 wheel speed sensor BIST";
CM_ SG_ 1470 IDB_a014_wheelSpeedSensorLeakage "IDB ECU: a014 wheel speed sensor leakage cur";
CM_ SG_ 1470 IDB_a014_wheelSpeedSensorOverTem "IDB ECU: a014 wheel speed sensor over temp";
CM_ SG_ 1470 IDB_a014_wheelSpeedSensorSh_0001 "IDB ECU: a014 wheel speed sensor short to gnd";
CM_ SG_ 1470 IDB_a014_wheelSpeedSensorShortTo "IDB ECU: a014 wheel speed sensor short to bat";
CM_ SG_ 1470 IDB_a014_wheelSpeedSensorOpen "IDB ECU: a014 wheel speed sensor open";
CM_ SG_ 1470 IDB_a015_wheelSpeedSensorFreq "IDB ECU: a015 wheel speed sensor freq";
CM_ SG_ 1470 IDB_a015_wheelSpeedSensorPhase "IDB ECU: a015 wheel speed sensor phase";
CM_ SG_ 1470 IDB_a015_wheelSpeedSensorMisinst "IDB ECU: a015 wheel speed sensor misinstallation";
CM_ SG_ 1470 IDB_a015_wheelSpeedSensorWrongEx "IDB ECU: a015 wheel speed sensor wrong exciter";
CM_ SG_ 1470 IDB_a015_wheelSpeedSensorSpeedJu "IDB ECU: a015 wheel speed sensor speed jump minus";
CM_ SG_ 1470 IDB_a015_wheelSpeedSensorSp_0001 "IDB ECU: a015 wheel speed sensor speed jump plus";
CM_ SG_ 1470 IDB_a015_wheelSpeedSensorAirGap "IDB ECU: a015 wheel speed sensor air gap";
CM_ SG_ 1470 IDB_a015_wheelSpeedSensorBIST "IDB ECU: a015 wheel speed sensor BIST";
CM_ SG_ 1470 IDB_a015_wheelSpeedSensorLeakage "IDB ECU: a015 wheel speed sensor leakage cur";
CM_ SG_ 1470 IDB_a015_wheelSpeedSensorOverTem "IDB ECU: a015 wheel speed sensor over temp";
CM_ SG_ 1470 IDB_a015_wheelSpeedSensorSh_0001 "IDB ECU: a015 wheel speed sensor short to gnd";
CM_ SG_ 1470 IDB_a015_wheelSpeedSensorShortTo "IDB ECU: a015 wheel speed sensor short to bat";
CM_ SG_ 1470 IDB_a015_wheelSpeedSensorOpen "IDB ECU: a015 wheel speed sensor open";
CM_ SG_ 1470 IDB_a016_wheelSpeedSensorFreq "IDB ECU: a016 wheel speed sensor freq";
CM_ SG_ 1470 IDB_a016_wheelSpeedSensorPhase "IDB ECU: a016 wheel speed sensor phase";
CM_ SG_ 1470 IDB_a016_wheelSpeedSensorMisinst "IDB ECU: a016 wheel speed sensor misinstallation";
CM_ SG_ 1470 IDB_a016_wheelSpeedSensorWrongEx "IDB ECU: a016 wheel speed sensor wrong exciter";
CM_ SG_ 1470 IDB_a016_wheelSpeedSensorSpeedJu "IDB ECU: a016 wheel speed sensor speed jump minus";
CM_ SG_ 1470 IDB_a016_wheelSpeedSensorSp_0001 "IDB ECU: a016 wheel speed sensor speed jump plus";
CM_ SG_ 1470 IDB_a016_wheelSpeedSensorAirGap "IDB ECU: a016 wheel speed sensor air gap";
CM_ SG_ 1470 IDB_a016_wheelSpeedSensorBIST "IDB ECU: a016 wheel speed sensor BIST";
CM_ SG_ 1470 IDB_a016_wheelSpeedSensorLeakage "IDB ECU: a016 wheel speed sensor leakage cur";
CM_ SG_ 1470 IDB_a016_wheelSpeedSensorOverTem "IDB ECU: a016 wheel speed sensor over temp";
CM_ SG_ 1470 IDB_a016_wheelSpeedSensorSh_0001 "IDB ECU: a016 wheel speed sensor short to gnd";
CM_ SG_ 1470 IDB_a016_wheelSpeedSensorShortTo "IDB ECU: a016 wheel speed sensor short to bat";
CM_ SG_ 1470 IDB_a016_wheelSpeedSensorOpen "IDB ECU: a016 wheel speed sensor open";
CM_ SG_ 1470 IDB_a017_wheelSpeedSensorFreq "IDB ECU: a017 wheel speed sensor freq";
CM_ SG_ 1470 IDB_a017_wheelSpeedSensorPhase "IDB ECU: a017 wheel speed sensor phase";
CM_ SG_ 1470 IDB_a017_wheelSpeedSensorMisinst "IDB ECU: a017 wheel speed sensor misinstallation";
CM_ SG_ 1470 IDB_a017_wheelSpeedSensorWrongEx "IDB ECU: a017 wheel speed sensor wrong exciter";
CM_ SG_ 1470 IDB_a017_wheelSpeedSensorSpeedJu "IDB ECU: a017 wheel speed sensor speed jump minus";
CM_ SG_ 1470 IDB_a017_wheelSpeedSensorSp_0001 "IDB ECU: a017 wheel speed sensor speed jump plus";
CM_ SG_ 1470 IDB_a017_wheelSpeedSensorAirGap "IDB ECU: a017 wheel speed sensor air gap";
CM_ SG_ 1470 IDB_a017_wheelSpeedSensorBIST "IDB ECU: a017 wheel speed sensor BIST";
CM_ SG_ 1470 IDB_a017_wheelSpeedSensorLeakage "IDB ECU: a017 wheel speed sensor leakage cur";
CM_ SG_ 1470 IDB_a017_wheelSpeedSensorOverTem "IDB ECU: a017 wheel speed sensor over temp";
CM_ SG_ 1470 IDB_a017_wheelSpeedSensorSh_0001 "IDB ECU: a017 wheel speed sensor short to gnd";
CM_ SG_ 1470 IDB_a017_wheelSpeedSensorShortTo "IDB ECU: a017 wheel speed sensor short to bat";
CM_ SG_ 1470 IDB_a017_wheelSpeedSensorOpen "IDB ECU: a017 wheel speed sensor open";
CM_ SG_ 1470 IDB_a020_canSignalValidity "IDB ECU: a020 can signal validity";
CM_ SG_ 1470 IDB_a020_signalValueCrosscheck "IDB ECU: a020 signal value crosscheck";
CM_ SG_ 1470 IDB_a030_primaryExternalCircuitL "IDB ECU: a030 primary external circuit leakage";
CM_ SG_ 1470 IDB_a030_secondaryExternalCircui "IDB ECU: a030 secondary external circuit leakage";
CM_ SG_ 1470 IDB_a030_primaryChamberInternalL "IDB ECU: a030 primary chamber internal leakage";
CM_ SG_ 1470 IDB_a030_syncModeInternalLeakage "IDB ECU: a030 sync mode internal leakage";
CM_ SG_ 1470 IDB_a030_secondaryChamberInterna "IDB ECU: a030 secondary chamber internal leakage";
CM_ SG_ 1470 IDB_a030_masterCylinderInternalL "IDB ECU: a030 master cylinder internal leakage";
CM_ SG_ 1470 IDB_a060_validityOnChassisBus "IDB ECU: a060 validity on chassis bus";
CM_ SG_ 1470 IDB_a060_validityOnPartyBus "IDB ECU: a060 validity on party bus";
CM_ SG_ 1470 IDB_a061_validityOnChassisBus "IDB ECU: a061 validity on chassis bus";
CM_ SG_ 1470 IDB_a061_validityOnPartyBus "IDB ECU: a061 validity on party bus";
CM_ SG_ 1470 IDB_a063_validityOnChassisBus "IDB ECU: a063 validity on chassis bus";
CM_ SG_ 1470 IDB_a063_validityOnPartyBus "IDB ECU: a063 validity on party bus";
CM_ SG_ 1470 IDB_a064_validityOnChassisBus "IDB ECU: a064 validity on chassis bus";
CM_ SG_ 1470 IDB_a064_validityOnPartyBus "IDB ECU: a064 validity on party bus";
CM_ SG_ 1470 IDB_a065_validityOnChassisBus "IDB ECU: a065 validity on chassis bus";
CM_ SG_ 1470 IDB_a065_validityOnPartyBus "IDB ECU: a065 validity on party bus";
CM_ SG_ 1470 IDB_a106_qualifierValidity "IDB ECU: a106 qualifier validity";
CM_ SG_ 1470 IDB_a106_signalNotAvailable "IDB ECU: a106 signal not available";
CM_ SG_ 1470 IDB_a107_qualifierValidity "IDB ECU: a107 qualifier validity";
CM_ SG_ 1470 IDB_a107_signalNotAvailable "IDB ECU: a107 signal not available";
CM_ SG_ 1470 IDB_a112_qualifierValidity "IDB ECU: a112 qualifier validity";
CM_ SG_ 1470 IDB_a112_signalNotAvailable "IDB ECU: a112 signal not available";
CM_ SG_ 1470 IDB_a113_qualifierValidity "IDB ECU: a113 qualifier validity";
CM_ SG_ 1470 IDB_a113_signalNotAvailable "IDB ECU: a113 signal not available";
CM_ SG_ 1470 IDB_a114_qualifierValidity "IDB ECU: a114 qualifier validity";
CM_ SG_ 1470 IDB_a114_signalNotAvailable "IDB ECU: a114 signal not available";
CM_ SG_ 1470 IDB_a126_PMebrCmdStateValidity "IDB ECU: a126 p mebr cmd state validity";
CM_ SG_ 1470 IDB_a126_PMstate2Validity "IDB ECU: a126 p mstate2 validity";
CM_ SG_ 1470 IDB_a126_PMstate2Missing "IDB ECU: a126 p mstate2 missing";
CM_ SG_ 1470 IDB_a126_DIchassisControlValidit "IDB ECU: a126 d ichassis control validity";
CM_ SG_ 1470 IDB_a126_DIchassisControlMissing "IDB ECU: a126 d ichassis control missing";
CM_ SG_ 1470 IDB_a126_DIrequestActiveValidity "IDB ECU: a126 d irequest active validity";
CM_ SG_ 1470 IDB_a129_validityOnChassisBus "IDB ECU: a129 validity on chassis bus";
CM_ SG_ 1470 IDB_a129_validityOnPartyBus "IDB ECU: a129 validity on party bus";
CM_ SG_ 1470 IDB_a130_PMbrakePedalCmdQFValidi "IDB ECU: a130 p mbrake pedal cmd QF validity";
CM_ SG_ 1470 IDB_a130_PMstate2Validity "IDB ECU: a130 p mstate2 validity";
CM_ SG_ 1470 IDB_a130_PMstate2Missing "IDB ECU: a130 p mstate2 missing";
CM_ SG_ 1470 IDB_a130_DIbrakeCommandValidity "IDB ECU: a130 d ibrake command validity";
CM_ SG_ 1470 IDB_a130_DIbrakeCommandMissing "IDB ECU: a130 d ibrake command missing";
CM_ SG_ 1470 IDB_a130_DIbrakeTorqueCommandFul "IDB ECU: a130 d ibrake torque command full SNA";
CM_ SG_ 1470 IDB_a130_DIbrakeTorqueComma_0001 "IDB ECU: a130 d ibrake torque command full too low";
CM_ SG_ 1470 IDB_a132_validityOnChassisBus "IDB ECU: a132 validity on chassis bus";
CM_ SG_ 1470 IDB_a132_validityOnPartyBus "IDB ECU: a132 validity on party bus";
CM_ BO_ 983 "IDB ECU message: alert matrix";
CM_ SG_ 983 IDB_matrixIndex "IDB ECU: matrix index";
CM_ SG_ 983 IDB_a001_mcuGenericFault "IDB ECU: a001 mcu generic fault";
CM_ SG_ 983 IDB_a002_supplyOvervoltage "IDB ECU: a002 supply overvoltage";
CM_ SG_ 983 IDB_a003_supplyHardOvervoltage "IDB ECU: a003 supply hard overvoltage";
CM_ SG_ 983 IDB_a004_supplyUndervoltage "IDB ECU: a004 supply undervoltage";
CM_ SG_ 983 IDB_a005_supplyMidUndervoltage "IDB ECU: a005 supply mid undervoltage";
CM_ SG_ 983 IDB_a006_supplyHardUndervoltage "IDB ECU: a006 supply hard undervoltage";
CM_ SG_ 983 IDB_a007_wakeLineOpen "IDB ECU: a007 wake line open";
CM_ SG_ 983 IDB_a008_motorPowerOpen "IDB ECU: a008 motor power open";
CM_ SG_ 983 IDB_a009_asicBoostFault "IDB ECU: a009 asic boost fault";
CM_ SG_ 983 IDB_a010_asicGenericFault "IDB ECU: a010 asic generic fault";
CM_ SG_ 983 IDB_a011_solenoidValveFault "IDB ECU: a011 solenoid valve fault";
CM_ SG_ 983 IDB_a012_motorGenericFault "IDB ECU: a012 motor generic fault";
CM_ SG_ 983 IDB_a013_motorPosSensorFault "IDB ECU: a013 motor pos sensor fault";
CM_ SG_ 983 IDB_a014_FrLWSSFault "IDB ECU: a014 fr LWSS fault";
CM_ SG_ 983 IDB_a015_FrRWSSFault "IDB ECU: a015 fr RWSS fault";
CM_ SG_ 983 IDB_a016_ReLWSSFault "IDB ECU: a016 re LWSS fault";
CM_ SG_ 983 IDB_a017_ReRWSSFault "IDB ECU: a017 re RWSS fault";
CM_ SG_ 983 IDB_a018_WSSGenericFault "IDB ECU: a018 WSS generic fault";
CM_ SG_ 983 IDB_a019_pedalSensorFault "IDB ECU: a019 pedal sensor fault";
CM_ SG_ 983 IDB_a020_RCUpedalTravelMismatch "IDB ECU: a020 RC upedal travel mismatch";
CM_ SG_ 983 IDB_a021_pedalSensorNotCal "IDB ECU: a021 pedal sensor not cal";
CM_ SG_ 983 IDB_a022_brakeFluidLow "IDB ECU: a022 brake fluid low";
CM_ SG_ 983 IDB_a023_steeringImplausible "IDB ECU: a023 steering implausible";
CM_ SG_ 983 IDB_a024_yawImplausible "IDB ECU: a024 yaw implausible";
CM_ SG_ 983 IDB_a025_ayImplausible "IDB ECU: a025 ay implausible";
CM_ SG_ 983 IDB_a026_axImplausible "IDB ECU: a026 ax implausible";
CM_ SG_ 983 IDB_a027_circuitPresSensorFault "IDB ECU: a027 circuit pres sensor fault";
CM_ SG_ 983 IDB_a028_simPresSensorFault "IDB ECU: a028 sim pres sensor fault";
CM_ SG_ 983 IDB_a029_pressureSensNotCal "IDB ECU: a029 pressure sens not cal";
CM_ SG_ 983 IDB_a030_fluidLeakDetected "IDB ECU: a030 fluid leak detected";
CM_ SG_ 983 IDB_a031_solenoidValveStuck "IDB ECU: a031 solenoid valve stuck";
CM_ SG_ 983 IDB_a032_motorSoftOverheat "IDB ECU: a032 motor soft overheat";
CM_ SG_ 983 IDB_a033_motorHardOverheat "IDB ECU: a033 motor hard overheat";
CM_ SG_ 983 IDB_a034_motorPositionSetFault "IDB ECU: a034 motor position set fault";
CM_ SG_ 983 IDB_a035_motorStuck "IDB ECU: a035 motor stuck";
CM_ SG_ 983 IDB_a036_partyBusOff "IDB ECU: a036 party bus off";
CM_ SG_ 983 IDB_a037_chassisBusOff "IDB ECU: a037 chassis bus off";
CM_ SG_ 983 IDB_a038_motorInitFault "IDB ECU: a038 motor init fault";
CM_ SG_ 983 IDB_a039_absActive "IDB ECU: a039 abs active";
CM_ SG_ 983 IDB_a040_ebdActive "IDB ECU: a040 ebd active";
CM_ SG_ 983 IDB_a041_vdcActive "IDB ECU: a041 vdc active";
CM_ SG_ 983 IDB_a042_btcActive "IDB ECU: a042 btc active";
CM_ SG_ 983 IDB_a043_cbcActive "IDB ECU: a043 cbc active";
CM_ SG_ 983 IDB_a044_standstillSkidDetected "IDB ECU: a044 standstill skid detected";
CM_ SG_ 983 IDB_a045_panicBrakeAssistActive "IDB ECU: a045 panic brake assist active";
CM_ SG_ 983 IDB_a046_fadeCompensationActive "IDB ECU: a046 fade compensation active";
CM_ SG_ 983 IDB_a047_brakeDiscWipeActive "IDB ECU: a047 brake disc wipe active";
CM_ SG_ 983 IDB_a048_scmActive "IDB ECU: a048 scm active";
CM_ SG_ 983 IDB_a049_cdpActive "IDB ECU: a049 cdp active";
CM_ SG_ 983 IDB_a050_absFaulted "IDB ECU: a050 abs faulted";
CM_ SG_ 983 IDB_a051_ebdFaulted "IDB ECU: a051 ebd faulted";
CM_ SG_ 983 IDB_a052_vdcFaulted "IDB ECU: a052 vdc faulted";
CM_ SG_ 983 IDB_a053_DItorquePathFaulted "IDB ECU: a053 d itorque path faulted";
CM_ SG_ 983 IDB_a054_skidDetectionFaulted "IDB ECU: a054 skid detection faulted";
CM_ SG_ 983 IDB_a055_panicBrakeAssistFaulted "IDB ECU: a055 panic brake assist faulted";
CM_ SG_ 983 IDB_a056_fadeCompensationFaulted "IDB ECU: a056 fade compensation faulted";
CM_ SG_ 983 IDB_a057_bdwRequestInvalid "IDB ECU: a057 bdw request invalid";
CM_ SG_ 983 IDB_a058_scmFaulted "IDB ECU: a058 scm faulted";
CM_ SG_ 983 IDB_a059_cdpFaulted "IDB ECU: a059 cdp faulted";
CM_ SG_ 983 IDB_a060_RCUstatusDLC "IDB ECU: a060 RC ustatus DLC";
CM_ SG_ 983 IDB_a061_RCUstatusChecksum "IDB ECU: a061 RC ustatus checksum";
CM_ SG_ 983 IDB_a062_RCUstatusCounter "IDB ECU: a062 RC ustatus counter";
CM_ SG_ 983 IDB_a063_RCUactuationDLC "IDB ECU: a063 RC uactuation DLC";
CM_ SG_ 983 IDB_a064_RCUactuationChecksum "IDB ECU: a064 RC uactuation checksum";
CM_ SG_ 983 IDB_a065_RCUactuationCounter "IDB ECU: a065 RC uactuation counter";
CM_ SG_ 983 IDB_a066_DIFtorqueDLC "IDB ECU: a066 DI ftorque DLC";
CM_ SG_ 983 IDB_a067_DIFtorqueChecksum "IDB ECU: a067 DI ftorque checksum";
CM_ SG_ 983 IDB_a068_DIFtorqueCounter "IDB ECU: a068 DI ftorque counter";
CM_ SG_ 983 IDB_a069_DIchassisControlDLC "IDB ECU: a069 d ichassis control DLC";
CM_ SG_ 983 IDB_a070_DIchassisControlChecksu "IDB ECU: a070 d ichassis control checksum";
CM_ SG_ 983 IDB_a071_DIchassisControlCounter "IDB ECU: a071 d ichassis control counter";
CM_ SG_ 983 IDB_a072_DIsystemStatusDLC "IDB ECU: a072 d isystem status DLC";
CM_ SG_ 983 IDB_a073_DIsystemStatusChecksum "IDB ECU: a073 d isystem status checksum";
CM_ SG_ 983 IDB_a074_DIsystemStatusCounter "IDB ECU: a074 d isystem status counter";
CM_ SG_ 983 IDB_a075_DIRtorqueDLC "IDB ECU: a075 DI rtorque DLC";
CM_ SG_ 983 IDB_a076_DIRtorqueChecksum "IDB ECU: a076 DI rtorque checksum";
CM_ SG_ 983 IDB_a077_DIRtorqueCounter "IDB ECU: a077 DI rtorque counter";
CM_ SG_ 983 IDB_a078_DIvdcLeftDLC "IDB ECU: a078 d ivdc left DLC";
CM_ SG_ 983 IDB_a079_DIvdcLeftChecksum "IDB ECU: a079 d ivdc left checksum";
CM_ SG_ 983 IDB_a080_DIvdcLeftCounter "IDB ECU: a080 d ivdc left counter";
CM_ SG_ 983 IDB_a081_DIvdcRightDLC "IDB ECU: a081 d ivdc right DLC";
CM_ SG_ 983 IDB_a082_DIvdcRightChecksum "IDB ECU: a082 d ivdc right checksum";
CM_ SG_ 983 IDB_a083_DIvdcRightCounter "IDB ECU: a083 d ivdc right counter";
CM_ SG_ 983 IDB_a084_EPAS3PsysStatusDLC "IDB ECU: a084 EPAS3 psys status DLC";
CM_ SG_ 983 IDB_a085_EPAS3PsysStatusChecksum "IDB ECU: a085 EPAS3 psys status checksum";
CM_ SG_ 983 IDB_a086_EPAS3PsysStatusCounter "IDB ECU: a086 EPAS3 psys status counter";
CM_ SG_ 983 IDB_a087_PMstate2DLC "IDB ECU: a087 p mstate2 DLC";
CM_ SG_ 983 IDB_a088_PMstate2Checksum "IDB ECU: a088 p mstate2 checksum";
CM_ SG_ 983 IDB_a089_PMstate2Counter "IDB ECU: a089 p mstate2 counter";
CM_ SG_ 983 IDB_a090_RCMinertial1DLC "IDB ECU: a090 RC minertial1 DLC";
CM_ SG_ 983 IDB_a091_RCMinertial1Checksum "IDB ECU: a091 RC minertial1 checksum";
CM_ SG_ 983 IDB_a092_RCMinertial1Counter "IDB ECU: a092 RC minertial1 counter";
CM_ SG_ 983 IDB_a093_RCMinertial2DLC "IDB ECU: a093 RC minertial2 DLC";
CM_ SG_ 983 IDB_a094_RCMinertial2Checksum "IDB ECU: a094 RC minertial2 checksum";
CM_ SG_ 983 IDB_a095_RCMinertial2Counter "IDB ECU: a095 RC minertial2 counter";
CM_ SG_ 983 IDB_a096_VCFRONTLVPowerStateDLC "IDB ECU: a096 VCFRONTLV power state DLC";
CM_ SG_ 983 IDB_a097_VCFRONTLVPwrStChecksum "IDB ECU: a097 VCFRONTLV pwr st checksum";
CM_ SG_ 983 IDB_a098_VCFRONTLVPwrStCounter "IDB ECU: a098 VCFRONTLV pwr st counter";
CM_ SG_ 983 IDB_a099_RCMcollisionDLC "IDB ECU: a099 RC mcollision DLC";
CM_ SG_ 983 IDB_a100_RCMcollisionChecksum "IDB ECU: a100 RC mcollision checksum";
CM_ SG_ 983 IDB_a101_RCMcollisionCounter "IDB ECU: a101 RC mcollision counter";
CM_ SG_ 983 IDB_a102_bdwRequestActiveInvalid "IDB ECU: a102 bdw request active invalid";
CM_ SG_ 983 IDB_a103_DIfullTorquePathFaulted "IDB ECU: a103 d ifull torque path faulted";
CM_ SG_ 983 IDB_a104_DIaccelPosInvalid "IDB ECU: a104 d iaccel pos invalid";
CM_ SG_ 983 IDB_a105_DIgearInvalid "IDB ECU: a105 d igear invalid";
CM_ SG_ 983 IDB_a106_DIFtorqueInvalid "IDB ECU: a106 DI ftorque invalid";
CM_ SG_ 983 IDB_a107_DIRtorqueInvalid "IDB ECU: a107 DI rtorque invalid";
CM_ SG_ 983 IDB_a108_EPBstatusDLC "IDB ECU: a108 EP bstatus DLC";
CM_ SG_ 983 IDB_a109_BDWsignalInvalid "IDB ECU: a109 BD wsignal invalid";
CM_ SG_ 983 IDB_a110_EPBstatusCounter "IDB ECU: a110 EP bstatus counter";
CM_ SG_ 983 IDB_a111_EPBstatusChecksum "IDB ECU: a111 EP bstatus checksum";
CM_ SG_ 983 IDB_a112_yawRateInvalid "IDB ECU: a112 yaw rate invalid";
CM_ SG_ 983 IDB_a113_latAccelInvalid "IDB ECU: a113 lat accel invalid";
CM_ SG_ 983 IDB_a114_longAccelInvalid "IDB ECU: a114 long accel invalid";
CM_ SG_ 983 IDB_a115_VCFRONTespLvStInvalid "IDB ECU: a115 VCFRON tesp lv st invalid";
CM_ SG_ 983 IDB_a116_VCFRONTsensorsDLC "IDB ECU: a116 VCFRON tsensors DLC";
CM_ SG_ 983 IDB_a117_VCLEFTepbmStatusDLC "IDB ECU: a117 VCLEF tepbm status DLC";
CM_ SG_ 983 IDB_a118_VCLEFTepbmStatusCounter "IDB ECU: a118 VCLEF tepbm status counter";
CM_ SG_ 983 IDB_a119_VCLEFTepbmStatusChecksu "IDB ECU: a119 VCLEF tepbm status checksum";
CM_ SG_ 983 IDB_a120_EPAS3Pinvalid "IDB ECU: a120 EPAS3 pinvalid";
CM_ SG_ 983 IDB_a121_dynoModeActive "IDB ECU: a121 dyno mode active";
CM_ SG_ 983 IDB_a122_DIFtorqueCommandInvalid "IDB ECU: a122 DI ftorque command invalid";
CM_ SG_ 983 IDB_a123_DIRtorqueCommandInvalid "IDB ECU: a123 DI rtorque command invalid";
CM_ SG_ 983 IDB_a124_VCFRONTtempInvalid "IDB ECU: a124 VCFRON ttemp invalid";
CM_ SG_ 983 IDB_a125_PMvdcCmdStateInvalid "IDB ECU: a125 p mvdc cmd state invalid";
CM_ SG_ 983 IDB_a126_DItorqueRequestInvalid "IDB ECU: a126 d itorque request invalid";
CM_ SG_ 983 IDB_a127_brakeFluidLevelInvalid "IDB ECU: a127 brake fluid level invalid";
CM_ SG_ 983 IDB_a128_largeAirVolume "IDB ECU: a128 large air volume";
CM_ SG_ 983 IDB_a129_RCUinputRodStrokeInvali "IDB ECU: a129 RC uinput rod stroke invalid";
CM_ SG_ 983 IDB_a130_DIfullTorqueRequestInva "IDB ECU: a130 d ifull torque request invalid";
CM_ SG_ 983 IDB_a131_cbcFaulted "IDB ECU: a131 cbc faulted";
CM_ SG_ 983 IDB_a132_RCUinputRodStrokeQFInva "IDB ECU: a132 RC uinput rod stroke QF invalid";
CM_ SG_ 983 IDB_a133_DIbrakeCommandDLC "IDB ECU: a133 d ibrake command DLC";
CM_ SG_ 983 IDB_a134_DIbrakeCommandCounter "IDB ECU: a134 d ibrake command counter";
CM_ SG_ 983 IDB_a135_DIbrakeCommandChecksum "IDB ECU: a135 d ibrake command checksum";
CM_ SG_ 983 IDB_a136_RCUptsCalMissing "IDB ECU: a136 RC upts cal missing";
CM_ SG_ 983 IDB_a137_VCLEFTcdpRequestInvalid "IDB ECU: a137 VCLEF tcdp request invalid";
CM_ SG_ 983 IDB_a138_DIbrakeTorqueCommandAnd "IDB ECU: a138 d ibrake torque command and flag mismatch";
CM_ SG_ 983 IDB_a139_DIbrakeTorqueCommandFul "IDB ECU: a139 d ibrake torque command full SNA";
CM_ SG_ 983 IDB_a140_PMbrakePedalCmdQFInvali "IDB ECU: a140 p mbrake pedal cmd QF invalid";
CM_ SG_ 983 IDB_a141_DIbrakeTorqueCommandFul "IDB ECU: a141 d ibrake torque command full too low";
CM_ SG_ 983 IDB_a142_PMebrCmdStateInvalid "IDB ECU: a142 p mebr cmd state invalid";
CM_ SG_ 983 IDB_a143_factoryModeActive "IDB ECU: a143 factory mode active";
CM_ SG_ 983 IDB_a144_hydraulicPushthroughAct "IDB ECU: a144 hydraulic pushthrough active";
CM_ SG_ 983 IDB_a145_DASredundantBrakingCont "IDB ECU: a145 DA sredundant braking control DLC";
CM_ SG_ 983 IDB_a146_DASredundantBrakingCont "IDB ECU: a146 DA sredundant braking control counter";
CM_ SG_ 983 IDB_a147_DASredundantBrakingCont "IDB ECU: a147 DA sredundant braking control checksum";
CM_ SG_ 983 IDB_a148_DASbrakeTorqueCommandIn "IDB ECU: a148 DA sbrake torque command invalid";
CM_ SG_ 983 IDB_a149_DASmiaBrakeTorqueComman "IDB ECU: a149 DA smia brake torque command invalid";
CM_ SG_ 983 IDB_a150_DIlocStatus2DLC "IDB ECU: a150 d iloc status2 DLC";
CM_ SG_ 983 IDB_a151_DIlocStatus2Counter "IDB ECU: a151 d iloc status2 counter";
CM_ SG_ 983 IDB_a152_DIlocStatus2Checksum "IDB ECU: a152 d iloc status2 checksum";
CM_ SG_ 983 IDB_a155_PMlocStateDLC "IDB ECU: a155 p mloc state DLC";
CM_ SG_ 983 IDB_a156_PMlocStateChecksum "IDB ECU: a156 p mloc state checksum";
CM_ SG_ 983 IDB_a157_PMlocStateCounter "IDB ECU: a157 p mloc state counter";
CM_ BO_ 828 "IDB ECU message: info";
CM_ SG_ 828 IDB_infoIndex "IDB ECU: info index";
CM_ SG_ 828 IDB_infoPcbaID "IDB ECU: info pcba ID";
CM_ SG_ 828 IDB_infoAssemblyID "IDB ECU: info assembly ID";
CM_ SG_ 828 IDB_infoUsageID "IDB ECU: info usage ID";
CM_ SG_ 828 IDB_infoSubUsageID "IDB ECU: info sub usage ID";
CM_ BO_ 1012 "LS ECU message: light show";
CM_ SG_ 1012 LS_lightShowIndex "LS ECU: light show index";
CM_ SG_ 1012 LS_lightLeftRampedChannel1Reques "LS ECU: light left ramped channel1 request";
CM_ SG_ 1012 LS_lightLeftRampedChannel1Durati "LS ECU: light left ramped channel1 duration";
CM_ SG_ 1012 LS_lightLeftRampedChannel2Reques "LS ECU: light left ramped channel2 request";
CM_ SG_ 1012 LS_lightLeftRampedChannel2Durati "LS ECU: light left ramped channel2 duration";
CM_ SG_ 1012 LS_lightLeftRampedChannel3Reques "LS ECU: light left ramped channel3 request";
CM_ SG_ 1012 LS_lightLeftRampedChannel3Durati "LS ECU: light left ramped channel3 duration";
CM_ SG_ 1012 LS_lightLeftRampedChannel4Reques "LS ECU: light left ramped channel4 request";
CM_ SG_ 1012 LS_lightLeftRampedChannel4Durati "LS ECU: light left ramped channel4 duration";
CM_ SG_ 1012 LS_lightLeftRampedChannel5Reques "LS ECU: light left ramped channel5 request";
CM_ SG_ 1012 LS_lightLeftRampedChannel5Durati "LS ECU: light left ramped channel5 duration";
CM_ SG_ 1012 LS_lightLeftRampedChannel6Reques "LS ECU: light left ramped channel6 request";
CM_ SG_ 1012 LS_lightLeftRampedChannel6Durati "LS ECU: light left ramped channel6 duration";
CM_ SG_ 1012 LS_lightLeftRampedChannel7Reques "LS ECU: light left ramped channel7 request";
CM_ SG_ 1012 LS_lightLeftRampedChannel7Durati "LS ECU: light left ramped channel7 duration";
CM_ SG_ 1012 LS_lightRightRampedChannel1Reque "LS ECU: light right ramped channel1 request";
CM_ SG_ 1012 LS_lightRightRampedChannel1Durat "LS ECU: light right ramped channel1 duration";
CM_ SG_ 1012 LS_lightRightRampedChannel2Reque "LS ECU: light right ramped channel2 request";
CM_ SG_ 1012 LS_lightRightRampedChannel2Durat "LS ECU: light right ramped channel2 duration";
CM_ SG_ 1012 LS_lightRightRampedChannel3Reque "LS ECU: light right ramped channel3 request";
CM_ SG_ 1012 LS_lightRightRampedChannel3Durat "LS ECU: light right ramped channel3 duration";
CM_ SG_ 1012 LS_lightRightRampedChannel4Reque "LS ECU: light right ramped channel4 request";
CM_ SG_ 1012 LS_lightRightRampedChannel4Durat "LS ECU: light right ramped channel4 duration";
CM_ SG_ 1012 LS_lightRightRampedChannel5Reque "LS ECU: light right ramped channel5 request";
CM_ SG_ 1012 LS_lightRightRampedChannel5Durat "LS ECU: light right ramped channel5 duration";
CM_ SG_ 1012 LS_lightRightRampedChannel6Reque "LS ECU: light right ramped channel6 request";
CM_ SG_ 1012 LS_lightRightRampedChannel6Durat "LS ECU: light right ramped channel6 duration";
CM_ SG_ 1012 LS_lightRightRampedChannel7Reque "LS ECU: light right ramped channel7 request";
CM_ SG_ 1012 LS_lightRightRampedChannel7Durat "LS ECU: light right ramped channel7 duration";
CM_ SG_ 1012 LS_lightRearTurnLeftRequest "LS ECU: light rear turn left request";
CM_ SG_ 1012 LS_lightRearTurnRightRequest "LS ECU: light rear turn right request";
CM_ SG_ 1012 LS_lightSideRepeaterLeftRequest "LS ECU: light side repeater left request";
CM_ SG_ 1012 LS_lightSideRepeaterRightRequest "LS ECU: light side repeater right request";
CM_ SG_ 1012 LS_lightSideMarkerLeftRequest "LS ECU: light side marker left request";
CM_ SG_ 1012 LS_lightSideMarkerRightRequest "LS ECU: light side marker right request";
CM_ SG_ 1012 LS_lightFrontFogLeftRequest "LS ECU: light front fog left request";
CM_ SG_ 1012 LS_lightFrontFogRightRequest "LS ECU: light front fog right request";
CM_ SG_ 1012 LS_lightRearFogRequest "LS ECU: light rear fog request";
CM_ SG_ 1012 LS_lightBrakeRequest "LS ECU: light brake request";
CM_ SG_ 1012 LS_lightTailLeftRequest "LS ECU: light tail left request";
CM_ SG_ 1012 LS_lightTailRightRequest "LS ECU: light tail right request";
CM_ SG_ 1012 LS_lightLicensePlateRequest "LS ECU: light license plate request";
CM_ SG_ 1012 LS_lightReverseRequest "LS ECU: light reverse request";
CM_ SG_ 1012 LS_lightAuxParkLeftRequest "LS ECU: light aux park left request";
CM_ SG_ 1012 LS_lightAuxParkRightRequest "LS ECU: light aux park right request";
CM_ SG_ 1012 LS_mirrorRequestLeft "LS ECU: mirror request left";
CM_ SG_ 1012 LS_mirrorRequestRight "LS ECU: mirror request right";
CM_ SG_ 1012 LS_liftgateRequest "LS ECU: liftgate request";
CM_ SG_ 1012 LS_windowRequestLF "LS ECU: window request LF";
CM_ SG_ 1012 LS_windowRequestLR "LS ECU: window request LR";
CM_ SG_ 1012 LS_windowRequestRF "LS ECU: window request RF";
CM_ SG_ 1012 LS_windowRequestRR "LS ECU: window request RR";
CM_ SG_ 1012 LS_presentingHandleRequestLF "LS ECU: presenting handle request LF";
CM_ SG_ 1012 LS_presentingHandleRequestLR "LS ECU: presenting handle request LR";
CM_ SG_ 1012 LS_presentingHandleRequestRF "LS ECU: presenting handle request RF";
CM_ SG_ 1012 LS_presentingHandleRequestRR "LS ECU: presenting handle request RR";
CM_ SG_ 1012 LS_powerFrontDoorRequestLeft "LS ECU: power front door request left";
CM_ SG_ 1012 LS_powerFrontDoorRequestRight "LS ECU: power front door request right";
CM_ SG_ 1012 LS_falconDoorRequestLeft "LS ECU: falcon door request left";
CM_ SG_ 1012 LS_falconDoorRequestRight "LS ECU: falcon door request right";
CM_ SG_ 1012 LS_chargePortRequest "LS ECU: charge port request";
CM_ SG_ 1012 LS_chargePortRaveRequest "LS ECU: charge port rave request";
CM_ SG_ 1012 LS_suspensionRequest "LS ECU: suspension request";
CM_ SG_ 1012 LS_rgbIPFLRed "LS ECU: rgb IPFL red";
CM_ SG_ 1012 LS_rgbIPFLGreen "LS ECU: rgb IPFL green";
CM_ SG_ 1012 LS_rgbIPFLBlue "LS ECU: rgb IPFL blue";
CM_ SG_ 1012 LS_rgbIPFRRed "LS ECU: rgb IPFR red";
CM_ SG_ 1012 LS_rgbIPFRGreen "LS ECU: rgb IPFR green";
CM_ SG_ 1012 LS_rgbIPFRBlue "LS ECU: rgb IPFR blue";
CM_ SG_ 1012 LS_rgbDoorFLForeRed "LS ECU: rgb door FL fore red";
CM_ SG_ 1012 LS_rgbDoorFLForeGreen "LS ECU: rgb door FL fore green";
CM_ SG_ 1012 LS_rgbDoorFLForeBlue "LS ECU: rgb door FL fore blue";
CM_ SG_ 1012 LS_rgbDoorFLAftRed "LS ECU: rgb door FL aft red";
CM_ SG_ 1012 LS_rgbDoorFLAftGreen "LS ECU: rgb door FL aft green";
CM_ SG_ 1012 LS_rgbDoorFLAftBlue "LS ECU: rgb door FL aft blue";
CM_ SG_ 1012 LS_rgbDoorFRForeRed "LS ECU: rgb door FR fore red";
CM_ SG_ 1012 LS_rgbDoorFRForeGreen "LS ECU: rgb door FR fore green";
CM_ SG_ 1012 LS_rgbDoorFRForeBlue "LS ECU: rgb door FR fore blue";
CM_ SG_ 1012 LS_rgbDoorFRAftRed "LS ECU: rgb door FR aft red";
CM_ SG_ 1012 LS_rgbDoorFRAftGreen "LS ECU: rgb door FR aft green";
CM_ SG_ 1012 LS_rgbDoorFRAftBlue "LS ECU: rgb door FR aft blue";
CM_ SG_ 1012 LS_rgbDoorRLForeRed "LS ECU: rgb door RL fore red";
CM_ SG_ 1012 LS_rgbDoorRLForeGreen "LS ECU: rgb door RL fore green";
CM_ SG_ 1012 LS_rgbDoorRLForeBlue "LS ECU: rgb door RL fore blue";
CM_ SG_ 1012 LS_rgbDoorRLAftRed "LS ECU: rgb door RL aft red";
CM_ SG_ 1012 LS_rgbDoorRLAftGreen "LS ECU: rgb door RL aft green";
CM_ SG_ 1012 LS_rgbDoorRLAftBlue "LS ECU: rgb door RL aft blue";
CM_ SG_ 1012 LS_rgbDoorRRForeRed "LS ECU: rgb door RR fore red";
CM_ SG_ 1012 LS_rgbDoorRRForeGreen "LS ECU: rgb door RR fore green";
CM_ SG_ 1012 LS_rgbDoorRRForeBlue "LS ECU: rgb door RR fore blue";
CM_ SG_ 1012 LS_rgbDoorRRAftRed "LS ECU: rgb door RR aft red";
CM_ SG_ 1012 LS_rgbDoorRRAftGreen "LS ECU: rgb door RR aft green";
CM_ SG_ 1012 LS_rgbDoorRRAftBlue "LS ECU: rgb door RR aft blue";
CM_ SG_ 1012 LS_frontMatrix0 "LS ECU: front matrix0";
CM_ SG_ 1012 LS_frontMatrix1 "LS ECU: front matrix1";
CM_ SG_ 1012 LS_frontMatrix2 "LS ECU: front matrix2";
CM_ SG_ 1012 LS_frontMatrix3 "LS ECU: front matrix3";
CM_ SG_ 1012 LS_frontMatrix4 "LS ECU: front matrix4";
CM_ SG_ 1012 LS_frontMatrix5 "LS ECU: front matrix5";
CM_ SG_ 1012 LS_frontMatrix6 "LS ECU: front matrix6";
CM_ SG_ 1012 LS_frontMatrix7 "LS ECU: front matrix7";
CM_ SG_ 1012 LS_frontMatrix8 "LS ECU: front matrix8";
CM_ SG_ 1012 LS_frontMatrix9 "LS ECU: front matrix9";
CM_ SG_ 1012 LS_frontMatrix10 "LS ECU: front matrix10";
CM_ SG_ 1012 LS_frontMatrix11 "LS ECU: front matrix11";
CM_ SG_ 1012 LS_frontMatrix12 "LS ECU: front matrix12";
CM_ SG_ 1012 LS_frontMatrix13 "LS ECU: front matrix13";
CM_ SG_ 1012 LS_frontMatrix14 "LS ECU: front matrix14";
CM_ SG_ 1012 LS_frontMatrix15 "LS ECU: front matrix15";
CM_ SG_ 1012 LS_frontMatrix16 "LS ECU: front matrix16";
CM_ SG_ 1012 LS_frontMatrix17 "LS ECU: front matrix17";
CM_ SG_ 1012 LS_frontMatrix18 "LS ECU: front matrix18";
CM_ SG_ 1012 LS_frontMatrix19 "LS ECU: front matrix19";
CM_ SG_ 1012 LS_frontMatrix20 "LS ECU: front matrix20";
CM_ SG_ 1012 LS_frontMatrix21 "LS ECU: front matrix21";
CM_ SG_ 1012 LS_frontMatrix22 "LS ECU: front matrix22";
CM_ SG_ 1012 LS_frontMatrix23 "LS ECU: front matrix23";
CM_ SG_ 1012 LS_frontMatrix24 "LS ECU: front matrix24";
CM_ SG_ 1012 LS_frontMatrix25 "LS ECU: front matrix25";
CM_ SG_ 1012 LS_frontMatrix26 "LS ECU: front matrix26";
CM_ SG_ 1012 LS_frontMatrix27 "LS ECU: front matrix27";
CM_ SG_ 1012 LS_frontMatrix28 "LS ECU: front matrix28";
CM_ SG_ 1012 LS_frontMatrix29 "LS ECU: front matrix29";
CM_ SG_ 1012 LS_frontMatrix30 "LS ECU: front matrix30";
CM_ SG_ 1012 LS_frontMatrix31 "LS ECU: front matrix31";
CM_ SG_ 1012 LS_frontMatrix32 "LS ECU: front matrix32";
CM_ SG_ 1012 LS_frontMatrix33 "LS ECU: front matrix33";
CM_ SG_ 1012 LS_frontMatrix34 "LS ECU: front matrix34";
CM_ SG_ 1012 LS_frontMatrix35 "LS ECU: front matrix35";
CM_ SG_ 1012 LS_frontMatrix36 "LS ECU: front matrix36";
CM_ SG_ 1012 LS_frontMatrix37 "LS ECU: front matrix37";
CM_ SG_ 1012 LS_frontMatrix38 "LS ECU: front matrix38";
CM_ SG_ 1012 LS_frontMatrix39 "LS ECU: front matrix39";
CM_ SG_ 1012 LS_frontMatrix40 "LS ECU: front matrix40";
CM_ SG_ 1012 LS_frontMatrix41 "LS ECU: front matrix41";
CM_ SG_ 1012 LS_frontMatrix42 "LS ECU: front matrix42";
CM_ SG_ 1012 LS_frontMatrix43 "LS ECU: front matrix43";
CM_ SG_ 1012 LS_frontMatrix44 "LS ECU: front matrix44";
CM_ SG_ 1012 LS_frontMatrix45 "LS ECU: front matrix45";
CM_ SG_ 1012 LS_frontMatrix46 "LS ECU: front matrix46";
CM_ SG_ 1012 LS_frontMatrix47 "LS ECU: front matrix47";
CM_ SG_ 1012 LS_frontMatrix48 "LS ECU: front matrix48";
CM_ SG_ 1012 LS_frontMatrix49 "LS ECU: front matrix49";
CM_ SG_ 1012 LS_frontMatrix50 "LS ECU: front matrix50";
CM_ SG_ 1012 LS_frontMatrix51 "LS ECU: front matrix51";
CM_ SG_ 1012 LS_frontMatrix52 "LS ECU: front matrix52";
CM_ SG_ 1012 LS_frontMatrix53 "LS ECU: front matrix53";
CM_ SG_ 1012 LS_frontMatrix54 "LS ECU: front matrix54";
CM_ SG_ 1012 LS_frontMatrix55 "LS ECU: front matrix55";
CM_ SG_ 1012 LS_frontMatrix56 "LS ECU: front matrix56";
CM_ SG_ 1012 LS_frontMatrix57 "LS ECU: front matrix57";
CM_ SG_ 1012 LS_frontMatrix58 "LS ECU: front matrix58";
CM_ SG_ 1012 LS_frontMatrix59 "LS ECU: front matrix59";
CM_ SG_ 1012 LS_rearMatrix0 "LS ECU: rear matrix0";
CM_ SG_ 1012 LS_rearMatrix1 "LS ECU: rear matrix1";
CM_ SG_ 1012 LS_rearMatrix2 "LS ECU: rear matrix2";
CM_ SG_ 1012 LS_rearMatrix3 "LS ECU: rear matrix3";
CM_ SG_ 1012 LS_rearMatrix4 "LS ECU: rear matrix4";
CM_ SG_ 1012 LS_rearMatrix5 "LS ECU: rear matrix5";
CM_ SG_ 1012 LS_rearMatrix6 "LS ECU: rear matrix6";
CM_ SG_ 1012 LS_rearMatrix7 "LS ECU: rear matrix7";
CM_ SG_ 1012 LS_rearMatrix8 "LS ECU: rear matrix8";
CM_ SG_ 1012 LS_rearMatrix9 "LS ECU: rear matrix9";
CM_ SG_ 1012 LS_rearMatrix10 "LS ECU: rear matrix10";
CM_ SG_ 1012 LS_rearMatrix11 "LS ECU: rear matrix11";
CM_ SG_ 1012 LS_rearMatrix12 "LS ECU: rear matrix12";
CM_ SG_ 1012 LS_rearMatrix13 "LS ECU: rear matrix13";
CM_ SG_ 1012 LS_rearMatrix14 "LS ECU: rear matrix14";
CM_ SG_ 1012 LS_rearMatrix15 "LS ECU: rear matrix15";
CM_ SG_ 1012 LS_rearMatrix16 "LS ECU: rear matrix16";
CM_ SG_ 1012 LS_rearMatrix17 "LS ECU: rear matrix17";
CM_ SG_ 1012 LS_rearMatrix18 "LS ECU: rear matrix18";
CM_ SG_ 1012 LS_rearMatrix19 "LS ECU: rear matrix19";
CM_ SG_ 1012 LS_rearMatrix20 "LS ECU: rear matrix20";
CM_ SG_ 1012 LS_rearMatrix21 "LS ECU: rear matrix21";
CM_ SG_ 1012 LS_rearMatrix22 "LS ECU: rear matrix22";
CM_ SG_ 1012 LS_rearMatrix23 "LS ECU: rear matrix23";
CM_ SG_ 1012 LS_rearMatrix24 "LS ECU: rear matrix24";
CM_ SG_ 1012 LS_rearMatrix25 "LS ECU: rear matrix25";
CM_ SG_ 1012 LS_rearMatrix26 "LS ECU: rear matrix26";
CM_ SG_ 1012 LS_rearMatrix27 "LS ECU: rear matrix27";
CM_ SG_ 1012 LS_rearMatrix28 "LS ECU: rear matrix28";
CM_ SG_ 1012 LS_rearMatrix29 "LS ECU: rear matrix29";
CM_ SG_ 1012 LS_rearMatrix30 "LS ECU: rear matrix30";
CM_ SG_ 1012 LS_rearMatrix31 "LS ECU: rear matrix31";
CM_ SG_ 1012 LS_rearMatrix32 "LS ECU: rear matrix32";
CM_ SG_ 1012 LS_rearMatrix33 "LS ECU: rear matrix33";
CM_ SG_ 1012 LS_rearMatrix34 "LS ECU: rear matrix34";
CM_ SG_ 1012 LS_rearMatrix35 "LS ECU: rear matrix35";
CM_ SG_ 1012 LS_rearMatrix36 "LS ECU: rear matrix36";
CM_ SG_ 1012 LS_rearMatrix37 "LS ECU: rear matrix37";
CM_ SG_ 1012 LS_rearMatrix38 "LS ECU: rear matrix38";
CM_ SG_ 1012 LS_rearMatrix39 "LS ECU: rear matrix39";
CM_ SG_ 1012 LS_rearMatrix40 "LS ECU: rear matrix40";
CM_ SG_ 1012 LS_rearMatrix41 "LS ECU: rear matrix41";
CM_ SG_ 1012 LS_rearMatrix42 "LS ECU: rear matrix42";
CM_ SG_ 1012 LS_rearMatrix43 "LS ECU: rear matrix43";
CM_ SG_ 1012 LS_rearMatrix44 "LS ECU: rear matrix44";
CM_ SG_ 1012 LS_rearMatrix45 "LS ECU: rear matrix45";
CM_ SG_ 1012 LS_rearMatrix46 "LS ECU: rear matrix46";
CM_ SG_ 1012 LS_rearMatrix47 "LS ECU: rear matrix47";
CM_ SG_ 1012 LS_rearMatrix48 "LS ECU: rear matrix48";
CM_ SG_ 1012 LS_rearMatrix49 "LS ECU: rear matrix49";
CM_ SG_ 1012 LS_rearMatrix50 "LS ECU: rear matrix50";
CM_ SG_ 1012 LS_rearMatrix51 "LS ECU: rear matrix51";
CM_ SG_ 1012 LS_rearMatrix52 "LS ECU: rear matrix52";
CM_ SG_ 1012 LS_rearMatrix53 "LS ECU: rear matrix53";
CM_ SG_ 1012 LS_rearMatrix54 "LS ECU: rear matrix54";
CM_ SG_ 1012 LS_rearMatrix55 "LS ECU: rear matrix55";
CM_ SG_ 1012 LS_rearMatrix56 "LS ECU: rear matrix56";
CM_ SG_ 1012 LS_rearMatrix57 "LS ECU: rear matrix57";
CM_ SG_ 1012 LS_rearMatrix58 "LS ECU: rear matrix58";
CM_ SG_ 1012 LS_rearMatrix59 "LS ECU: rear matrix59";
CM_ SG_ 1012 LS_offroadLightBar0 "LS ECU: offroad light bar0";
CM_ SG_ 1012 LS_offroadLightBar1 "LS ECU: offroad light bar1";
CM_ SG_ 1012 LS_offroadLightBar2 "LS ECU: offroad light bar2";
CM_ SG_ 1012 LS_offroadLightBar3 "LS ECU: offroad light bar3";
CM_ SG_ 1012 LS_offroadLightBar4 "LS ECU: offroad light bar4";
CM_ SG_ 1012 LS_offroadLightBar5 "LS ECU: offroad light bar5";
CM_ BO_ 1429 "Occupant classification system message: alert log";
CM_ SG_ 1429 OCS1P_alertID "Occupant classification system: alert ID";
CM_ SG_ 1429 OCS1P_alertState "Occupant classification system: alert state";
CM_ SG_ 1429 OCS1P_a121_sandwichFreq "Occupant classification system: a121 sandwich freq";
CM_ SG_ 1429 OCS1P_a122_sandwichFreq "Occupant classification system: a122 sandwich freq";
CM_ SG_ 1429 OCS1P_a123_sandwichFreq "Occupant classification system: a123 sandwich freq";
CM_ SG_ 1429 OCS1P_a124_cushionSelfFreq "Occupant classification system: a124 cushion self freq";
CM_ SG_ 1429 OCS1P_a125_cushionSelfFreq "Occupant classification system: a125 cushion self freq";
CM_ SG_ 1429 OCS1P_a126_cushionSelfFreq "Occupant classification system: a126 cushion self freq";
CM_ SG_ 1429 OCS1P_a127_seatbackSelfFreq "Occupant classification system: a127 seatback self freq";
CM_ SG_ 1429 OCS1P_a128_seatbackSelfFreq "Occupant classification system: a128 seatback self freq";
CM_ SG_ 1429 OCS1P_a129_seatbackSelfFreq "Occupant classification system: a129 seatback self freq";
CM_ SG_ 1429 OCS1P_a130_sandwichNoCalib "Occupant classification system: a130 sandwich no calib";
CM_ SG_ 1429 OCS1P_a131_cushionSelfNoCalib "Occupant classification system: a131 cushion self no calib";
CM_ SG_ 1429 OCS1P_a132_seatbackSelfNoCalib "Occupant classification system: a132 seatback self no calib";
CM_ SG_ 1429 OCS1P_a133_sandwichBadCalib "Occupant classification system: a133 sandwich bad calib";
CM_ SG_ 1429 OCS1P_a134_uninitializedCalib "Occupant classification system: a134 uninitialized calib";
CM_ SG_ 1429 OCS1P_a135_tempNoCalib "Occupant classification system: a135 temp no calib";
CM_ SG_ 1429 OCS1P_a140_tempInvalidCalib "Occupant classification system: a140 temp invalid calib";
CM_ SG_ 1429 OCS1P_a141_humidityInvalidCalib "Occupant classification system: a141 humidity invalid calib";
CM_ SG_ 1429 OCS1P_a142_tempHumidityInvalid "Occupant classification system: a142 temp humidity invalid";
CM_ SG_ 1429 OCS1P_a143_mismatchPassAirbag "Occupant classification system: a143 mismatch pass airbag";
CM_ SG_ 1429 OCS1P_a144_mismatchCarRegion "Occupant classification system: a144 mismatch car region";
CM_ BO_ 767 "Occupant classification system message: alert matrix";
CM_ SG_ 767 OCS1P_matrixIndex "Occupant classification system: matrix index";
CM_ SG_ 767 OCS1P_w015_NVMMAlert "Occupant classification system: w015 NVMM alert";
CM_ SG_ 767 OCS1P_w121_sandwichOpen "Occupant classification system: w121 sandwich open";
CM_ SG_ 767 OCS1P_w122_sandwichLow "Occupant classification system: w122 sandwich low";
CM_ SG_ 767 OCS1P_w123_sandwichShort "Occupant classification system: w123 sandwich short";
CM_ SG_ 767 OCS1P_w124_cushionSelfOpen "Occupant classification system: w124 cushion self open";
CM_ SG_ 767 OCS1P_w125_cushionSelfLow "Occupant classification system: w125 cushion self low";
CM_ SG_ 767 OCS1P_w126_cushionSelfShort "Occupant classification system: w126 cushion self short";
CM_ SG_ 767 OCS1P_w127_seatbackSelfOpen "Occupant classification system: w127 seatback self open";
CM_ SG_ 767 OCS1P_w128_seatbackSelfLow "Occupant classification system: w128 seatback self low";
CM_ SG_ 767 OCS1P_w129_seatbackSelfShort "Occupant classification system: w129 seatback self short";
CM_ SG_ 767 OCS1P_w130_sandwichNoCalib "Occupant classification system: w130 sandwich no calib";
CM_ SG_ 767 OCS1P_w131_cushionSelfNoCalib "Occupant classification system: w131 cushion self no calib";
CM_ SG_ 767 OCS1P_w132_seatbackSelfNoCalib "Occupant classification system: w132 seatback self no calib";
CM_ SG_ 767 OCS1P_w133_sandwichBadCalib "Occupant classification system: w133 sandwich bad calib";
CM_ SG_ 767 OCS1P_w134_uninitializedCalib "Occupant classification system: w134 uninitialized calib";
CM_ SG_ 767 OCS1P_w135_tempNoCalib "Occupant classification system: w135 temp no calib";
CM_ SG_ 767 OCS1P_w136_cushionSelfDutyLow "Occupant classification system: w136 cushion self duty low";
CM_ SG_ 767 OCS1P_w137_cushionSelfDutyHigh "Occupant classification system: w137 cushion self duty high";
CM_ SG_ 767 OCS1P_w138_seatbackSelfDutyLow "Occupant classification system: w138 seatback self duty low";
CM_ SG_ 767 OCS1P_w139_seatbackSelfDutyHigh "Occupant classification system: w139 seatback self duty high";
CM_ SG_ 767 OCS1P_w140_tempInvalidCalib "Occupant classification system: w140 temp invalid calib";
CM_ SG_ 767 OCS1P_w141_humidityInvalidCalib "Occupant classification system: w141 humidity invalid calib";
CM_ SG_ 767 OCS1P_w142_tempHumidityInvalid "Occupant classification system: w142 temp humidity invalid";
CM_ SG_ 767 OCS1P_w143_mismatchPassAirbag "Occupant classification system: w143 mismatch pass airbag";
CM_ SG_ 767 OCS1P_w144_mismatchCarRegion "Occupant classification system: w144 mismatch car region";
CM_ SG_ 767 OCS1P_w145_rebaselineTriggered "Occupant classification system: w145 rebaseline triggered";
CM_ SG_ 767 OCS1P_w148_classificationMismatc "Occupant classification system: w148 classification mismatch";
CM_ SG_ 767 OCS1P_w150_rbEntryTriggered "Occupant classification system: w150 rb entry triggered";
CM_ SG_ 767 OCS1P_w151_rbEntryExited "Occupant classification system: w151 rb entry exited";
CM_ SG_ 767 OCS1P_w152_rbExit1Triggered "Occupant classification system: w152 rb exit1 triggered";
CM_ SG_ 767 OCS1P_w153_rbExit1Exited "Occupant classification system: w153 rb exit1 exited";
CM_ SG_ 767 OCS1P_w154_rbExit2Exited1 "Occupant classification system: w154 rb exit2 exited1";
CM_ SG_ 767 OCS1P_w155_rbExit2Exited2 "Occupant classification system: w155 rb exit2 exited2";
CM_ SG_ 767 OCS1P_w156_seatbeltReminderUnava "Occupant classification system: w156 seatbelt reminder unavailable";
CM_ BO_ 766 "Occupant classification system message: info";
CM_ SG_ 766 OCS1P_infoIndex "Occupant classification system: info index";
CM_ SG_ 766 OCS1P_infoBuildType "Occupant classification system: info build type";
CM_ SG_ 766 OCS1P_infoBuildConfigID "Occupant classification system: info build config ID";
CM_ SG_ 766 OCS1P_infoHardwareID "Occupant classification system: info hardware ID";
CM_ SG_ 766 OCS1P_infoComponentID "Occupant classification system: info component ID";
CM_ SG_ 766 OCS1P_infoPcbaID "Occupant classification system: info pcba ID";
CM_ SG_ 766 OCS1P_infoAssemblyID "Occupant classification system: info assembly ID";
CM_ SG_ 766 OCS1P_infoUsageID "Occupant classification system: info usage ID";
CM_ SG_ 766 OCS1P_infoSubUsageID "Occupant classification system: info sub usage ID";
CM_ SG_ 766 OCS1P_infoApplicationCRC "Occupant classification system: info application CRC";
CM_ SG_ 766 OCS1P_infoBootSvnRev "Occupant classification system: info boot svn rev";
CM_ SG_ 766 OCS1P_infoAppGitHashBytes "Occupant classification system: info app git hash bytes";
CM_ SG_ 766 OCS1P_infoBootGitHashBytes "Occupant classification system: info boot git hash bytes";
CM_ SG_ 766 OCS1P_infoPlatformType "Occupant classification system: info platform type";
CM_ SG_ 766 OCS1P_infoBootUdsProtoVersion "Occupant classification system: info boot uds proto version";
CM_ SG_ 766 OCS1P_infoBootloaderCRC "Occupant classification system: info bootloader CRC";
CM_ BO_ 771 "Occupant classification system message: status";
CM_ SG_ 771 OCS1P_occupantClassification "Occupant Classification (Filtered)";
CM_ SG_ 771 OCS1P_occupantClassificationQF "Occupant classification system: occupant classification QF";
CM_ SG_ 771 OCS1P_occupiedState "Passenger seat occupied State";
CM_ SG_ 771 OCS1P_triggerSnapshot "Occupant classification system: trigger snapshot";
CM_ SG_ 771 OCS1P_occupantClassificationRaw "Occupant classification system: occupant classification raw";
CM_ SG_ 771 OCS1P_occupantClassificationSelf "Occupant classification system: occupant classification self";
CM_ SG_ 771 OCS1P_occupantClassificationRawC "Occupant classification system: occupant classification raw cap";
CM_ SG_ 771 OCS1P_occupantClassificationCap "Occupant classification system: occupant classification cap";
CM_ SG_ 771 OCS1P_classificationHeld "Whether occupant classification is filtered due to door state or stability based on frequency";
CM_ SG_ 771 OCS1P_cushionStable "Whether frequency reading is unchanging of Cushion Self sensor";
CM_ SG_ 771 OCS1P_classificationExtHold "Occupant classification request to be filtered due to door state";
CM_ SG_ 771 OCS1P_classificationHoldState "Occupant classification system: classification hold state";
CM_ SG_ 771 OCS1P_classificationVariant "The combination of sensors used to classify occupant";
CM_ SG_ 771 OCS1P_sandwichDisabled "Cushion mutual sensor disabled by calibration";
CM_ SG_ 771 OCS1P_noSandwichType "Configuration set in factory or service that determines logic around uninstalled sandwich";
CM_ SG_ 771 OCS1P_sandwichBoundaryType "Occupant classification system: sandwich boundary type";
CM_ SG_ 771 OCS1P_sbrBoundaryType "Occupant classification system: sbr boundary type";
CM_ SG_ 771 OCS1P_occupiedStateCap "Occupant classification system: occupied state cap";
CM_ SG_ 771 OCS1P_seatbackStable "Whether frequency reading is unchanging of Seatback Self sensor";
CM_ SG_ 771 OCS1P_sandwichStable "Whether frequency reading is unchanging of Cushion Mutual sensor";
CM_ SG_ 771 OCS1P_cushionStableCap "Occupant classification system: cushion stable cap";
CM_ SG_ 771 OCS1P_seatbackStableCap "Occupant classification system: seatback stable cap";
CM_ SG_ 771 OCS1P_classificationHeldCap "Occupant classification system: classification held cap";
CM_ SG_ 771 OCS1P_statusCounter "Occupant classification system: status counter";
CM_ SG_ 771 OCS1P_statusChecksum "Occupant classification system: status checksum";
BA_DEF_ BO_ "GenMsgCycleTime" INT 0 3600000;
BA_DEF_ BO_ "GenMsgSendType" ENUM "Cyclic","NotUsed","NotUsed","NotUsed","NotUsed","NotUsed","NotUsed","IfActive","NoMsgSendType","NotUsed";
BA_DEF_ BO_ "VFrameFormat" ENUM "StandardCAN","ExtendedCAN","reserved","J1939PG","reserved","reserved","reserved","reserved","reserved","reserved","reserved","reserved","reserved","reserved","StandardCAN_FD","ExtendedCAN_FD";
BA_DEF_ BO_ "CANFD_BRS" ENUM "0","1";
BA_DEF_ SG_ "SystemSignalLongSymbol" STRING;
BA_DEF_ SG_ "Confidence" ENUM "layout-only","plausible","validated";
BA_DEF_DEF_ "GenMsgCycleTime" 0;
BA_DEF_DEF_ "GenMsgSendType" "NoMsgSendType";
BA_DEF_DEF_ "VFrameFormat" "StandardCAN";
BA_DEF_DEF_ "CANFD_BRS" "1";
BA_DEF_DEF_ "SystemSignalLongSymbol" "";
BA_DEF_DEF_ "Confidence" "layout-only";
BA_ "SystemSignalLongSymbol" SG_ 861 IBST_a182_DIchassisControlTimeou "IBST_a182_DIchassisControlTimeout";
BA_ "SystemSignalLongSymbol" SG_ 861 IBST_a183_DIchassisControlChecks "IBST_a183_DIchassisControlChecksum";
BA_ "SystemSignalLongSymbol" SG_ 861 IBST_a184_DIchassisControlCounte "IBST_a184_DIchassisControlCounter";
BA_ "SystemSignalLongSymbol" SG_ 861 IBST_a189_rightVCLVPowerStateTim "IBST_a189_rightVCLVPowerStateTimeout";
BA_ "SystemSignalLongSymbol" SG_ 861 IBST_a191_rightVCLVPowerStateChe "IBST_a191_rightVCLVPowerStateChecksum";
BA_ "SystemSignalLongSymbol" SG_ 861 IBST_a192_rightVCLVPowerStateCou "IBST_a192_rightVCLVPowerStateCounter";
BA_ "SystemSignalLongSymbol" SG_ 861 IBST_a193_leftVCLVPowerStateTime "IBST_a193_leftVCLVPowerStateTimeout";
BA_ "SystemSignalLongSymbol" SG_ 861 IBST_a194_leftVCLVPowerStateChec "IBST_a194_leftVCLVPowerStateChecksum";
BA_ "SystemSignalLongSymbol" SG_ 861 IBST_a196_leftVCLVPowerStateCoun "IBST_a196_leftVCLVPowerStateCounter";
BA_ "SystemSignalLongSymbol" SG_ 861 IBST_a197_brakeLatencyReductionA "IBST_a197_brakeLatencyReductionActive";
BA_ "SystemSignalLongSymbol" SG_ 861 IBST_a201_EGGREAR1wheelSpeedsRea "IBST_a201_EGGREAR1wheelSpeedsRearTimeOut";
BA_ "SystemSignalLongSymbol" SG_ 861 IBST_a202_EGGREAR1wheelSpeedsRea "IBST_a202_EGGREAR1wheelSpeedsRearChecksum";
BA_ "SystemSignalLongSymbol" SG_ 861 IBST_a203_EGGREAR1wheelSpeedsRea "IBST_a203_EGGREAR1wheelSpeedsRearDLC";
BA_ "SystemSignalLongSymbol" SG_ 861 IBST_a204_EGGREAR1wheelSpeedsRea "IBST_a204_EGGREAR1wheelSpeedsRearCounter";
BA_ "SystemSignalLongSymbol" SG_ 861 IBST_a205_EGGRIGHT1wheelSpeedsFr "IBST_a205_EGGRIGHT1wheelSpeedsFrontTimeOut";
BA_ "SystemSignalLongSymbol" SG_ 861 IBST_a206_EGGRIGHT1wheelSpeedsFr "IBST_a206_EGGRIGHT1wheelSpeedsFrontChecksum";
BA_ "SystemSignalLongSymbol" SG_ 861 IBST_a207_EGGRIGHT1wheelSpeedsFr "IBST_a207_EGGRIGHT1wheelSpeedsFrontDLC";
BA_ "SystemSignalLongSymbol" SG_ 861 IBST_a208_EGGRIGHT1wheelSpeedsFr "IBST_a208_EGGRIGHT1wheelSpeedsFrontCounter";
BA_ "SystemSignalLongSymbol" SG_ 861 IBST_a209_reducedBrakePowerActiv "IBST_a209_reducedBrakePowerActive";
BA_ "SystemSignalLongSymbol" SG_ 861 IBST_a210_reducedBrakePowerNotAv "IBST_a210_reducedBrakePowerNotAvailable";
BA_ "SystemSignalLongSymbol" SG_ 861 IBST_a212_infoFailureWrongCUBASH "IBST_a212_infoFailureWrongCUBASHandlingDetected";
BA_ "SystemSignalLongSymbol" SG_ 861 IBST_a213_PDURouterinitializatio "IBST_a213_PDURouterinitializationFailed";
BA_ "SystemSignalLongSymbol" SG_ 861 IBST_a214_LossOfPDUInstanceDetec "IBST_a214_LossOfPDUInstanceDetected";
BA_ "SystemSignalLongSymbol" SG_ 861 IBST_a215_UnsupportedSeriesHWDet "IBST_a215_UnsupportedSeriesHWDetected";
BA_ "SystemSignalLongSymbol" SG_ 861 IBST_a216_AsicMalfunctionDetecte "IBST_a216_AsicMalfunctionDetected";
BA_ "SystemSignalLongSymbol" SG_ 861 IBST_a217_AsicTrimmingNotComplet "IBST_a217_AsicTrimmingNotCompleted";
BA_ "SystemSignalLongSymbol" SG_ 861 IBST_a218_uCSafetyNotificationGR "IBST_a218_uCSafetyNotificationGRAM";
BA_ "SystemSignalLongSymbol" SG_ 861 IBST_a220_ASICOvercurrentOnGPIO2 "IBST_a220_ASICOvercurrentOnGPIO250_2";
BA_ "SystemSignalLongSymbol" SG_ 861 IBST_a221_ASICOvercurrentOnGPIO2 "IBST_a221_ASICOvercurrentOnGPIO250_1";
BA_ "SystemSignalLongSymbol" SG_ 861 IBST_a222_ASICOvercurrentOnGPIO5 "IBST_a222_ASICOvercurrentOnGPIO50_4";
BA_ "SystemSignalLongSymbol" SG_ 861 IBST_a223_ASICOvercurrentOnGPIO5 "IBST_a223_ASICOvercurrentOnGPIO50_3";
BA_ "SystemSignalLongSymbol" SG_ 861 IBST_a224_ASICOvercurrentOnGPIO5 "IBST_a224_ASICOvercurrentOnGPIO50_2";
BA_ "SystemSignalLongSymbol" SG_ 861 IBST_a225_ASICOvercurrentOnGPIO5 "IBST_a225_ASICOvercurrentOnGPIO50_1";
BA_ "SystemSignalLongSymbol" SG_ 861 IBST_a227_wakeRequestMismatchDet "IBST_a227_wakeRequestMismatchDetected";
BA_ "SystemSignalLongSymbol" SG_ 861 IBST_a228_BlockedPedalDetectedDu "IBST_a228_BlockedPedalDetectedDuringHAD";
BA_ "SystemSignalLongSymbol" SG_ 861 IBST_a232_PostAssemblyRoutineFai "IBST_a232_PostAssemblyRoutineFailed";
BA_ "SystemSignalLongSymbol" SG_ 861 IBST_a233_ReferenceRunAbortByECU "IBST_a233_ReferenceRunAbortByECUReset";
BA_ "SystemSignalLongSymbol" SG_ 861 IBST_a246_DASredundantBrakingCon "IBST_a246_DASredundantBrakingControlPartyChecksum";
BA_ "SystemSignalLongSymbol" SG_ 861 IBST_a247_DASredundantBrakingCon "IBST_a247_DASredundantBrakingControlPartyCounter";
BA_ "SystemSignalLongSymbol" SG_ 861 IBST_a248_DASredundantBrakingCon "IBST_a248_DASredundantBrakingControlPartyDLC";
BA_ "SystemSignalLongSymbol" SG_ 861 IBST_a249_DASredundantBrakingCon "IBST_a249_DASredundantBrakingControlPartyTimeout";
BA_ "SystemSignalLongSymbol" SG_ 861 IBST_a250_DASredundantBrakingCon "IBST_a250_DASredundantBrakingControlChassisChecksum";
BA_ "SystemSignalLongSymbol" SG_ 861 IBST_a251_DASredundantBrakingCon "IBST_a251_DASredundantBrakingControlChassisCounter";
BA_ "SystemSignalLongSymbol" SG_ 861 IBST_a252_DASredundantBrakingCon "IBST_a252_DASredundantBrakingControlChassisDLC";
BA_ "SystemSignalLongSymbol" SG_ 861 IBST_a253_DASredundantBrakingCon "IBST_a253_DASredundantBrakingControlChassisTimeout";
BA_ "Confidence" SG_ 813 IBST_infoBuildType 1;
BA_ "Confidence" SG_ 813 IBST_infoApplicationCRC 1;
BA_ "Confidence" SG_ 813 IBST_infoVariantCRC 1;
BA_ "Confidence" SG_ 925 IBST_iBoosterStatus 1;
BA_ "Confidence" SG_ 925 IBST_driverBrakeApply 1;
BA_ "Confidence" SG_ 925 IBST_internalState 1;
BA_ "Confidence" SG_ 925 IBST_sInputRodDriver 1;
BA_ "Confidence" SG_ 925 IBST_LVPowerModeState 1;
BA_ "SystemSignalLongSymbol" SG_ 1208 ICR_a001_watchdogTaskSentinelInt "ICR_a001_watchdogTaskSentinelInterface";
BA_ "SystemSignalLongSymbol" SG_ 1208 ICR_a001_watchdogTaskSentinelMod "ICR_a001_watchdogTaskSentinelModeChange";
BA_ "SystemSignalLongSymbol" SG_ 1208 ICR_a141_calDataNotCalibratedOrP "ICR_a141_calDataNotCalibratedOrProcessing";
BA_ "SystemSignalLongSymbol" SG_ 1208 ICR_a141_calDataValRXPhaseAboveM "ICR_a141_calDataValRXPhaseAboveMax";
BA_ "SystemSignalLongSymbol" SG_ 1208 ICR_a141_calDataValRXPhaseMissin "ICR_a141_calDataValRXPhaseMissingUnitMag";
BA_ "SystemSignalLongSymbol" SG_ 1208 ICR_a141_calDataValRangeBiasAbov "ICR_a141_calDataValRangeBiasAboveMax";
BA_ "SystemSignalLongSymbol" SG_ 2028 ICR_a139_AbnormalBlockageDetecte "ICR_a139_AbnormalBlockageDetected";
BA_ "SystemSignalLongSymbol" SG_ 2028 ICR_a140_OccupancyExceptionEncou "ICR_a140_OccupancyExceptionEncountered";
BA_ "SystemSignalLongSymbol" SG_ 2028 ICR_a144_OccupancyNotificationAl "ICR_a144_OccupancyNotificationAlert";
BA_ "Confidence" SG_ 941 ICR_infoBuildType 1;
BA_ "Confidence" SG_ 667 ICR_lifePresenceMLOutput 1;
BA_ "Confidence" SG_ 667 ICR_largeOccupantPresenceMLOutpu 1;
BA_ "SystemSignalLongSymbol" SG_ 667 ICR_largeOccupantPresenceMLOutpu "ICR_largeOccupantPresenceMLOutput";
BA_ "Confidence" SG_ 667 ICR_lifePresenceRaw 1;
BA_ "Confidence" SG_ 667 ICR_lifePresenceFilt 1;
BA_ "Confidence" SG_ 667 ICR_largeOccupantPresenceRaw 1;
BA_ "Confidence" SG_ 667 ICR_largeOccupantPresenceFilt 1;
BA_ "Confidence" SG_ 667 ICR_childPresenceFunctionality 1;
BA_ "Confidence" SG_ 667 ICR_userPresenceFunctionality 1;
BA_ "Confidence" SG_ 667 ICR_userPresenceMLOutput 1;
BA_ "Confidence" SG_ 667 ICR_userPresenceRaw 1;
BA_ "Confidence" SG_ 667 ICR_userPresenceFilt 1;
BA_ "Confidence" SG_ 2027 ICR_occupancy1LRaw 1;
BA_ "Confidence" SG_ 2027 ICR_occupancy1RRaw 1;
BA_ "Confidence" SG_ 2027 ICR_occupancy1LFilt 1;
BA_ "Confidence" SG_ 2027 ICR_occupancy1RFilt 1;
BA_ "Confidence" SG_ 2027 ICR_occupancy2LFilt 1;
BA_ "Confidence" SG_ 2027 ICR_occupancy2CFilt 1;
BA_ "Confidence" SG_ 2027 ICR_occupancy2RFilt 1;
BA_ "Confidence" SG_ 2027 ICR_occupancy1RFiltExp 1;
BA_ "Confidence" SG_ 670 ICR_classification1RFilt 1;
BA_ "Confidence" SG_ 670 ICR_classification1LRaw 1;
BA_ "Confidence" SG_ 670 ICR_classification1RRaw 1;
BA_ "Confidence" SG_ 670 ICR_classification1LMLOutput 1;
BA_ "Confidence" SG_ 670 ICR_classification1RMLOutput 1;
BA_ "Confidence" SG_ 670 ICR_classification1LqF 1;
BA_ "Confidence" SG_ 670 ICR_blockageClutterFar 1;
BA_ "Confidence" SG_ 670 ICR_blockageClutterNear 1;
BA_ "Confidence" SG_ 670 ICR_classification1LFilt 1;
BA_ "Confidence" SG_ 670 ICR_classification1RqF 1;
BA_ "Confidence" SG_ 670 ICR_classification1LLatched 1;
BA_ "Confidence" SG_ 670 ICR_classification1RLatched 1;
BA_ "Confidence" SG_ 2025 ICR_sensorMode 1;
BA_ "Confidence" SG_ 2025 ICR_blocked 1;
BA_ "Confidence" SG_ 2025 ICR_booted 1;
BA_ "Confidence" SG_ 2025 ICR_algoVersion 1;
BA_ "Confidence" SG_ 2025 ICR_l2HeapUsage 1;
BA_ "Confidence" SG_ 2025 ICR_intrusionStatus 1;
BA_ "Confidence" SG_ 2025 ICR_blockageScaledMLOutput 1;
BA_ "SystemSignalLongSymbol" SG_ 1470 IDB_a014_wheelSpeedSensorMisinst "IDB_a014_wheelSpeedSensorMisinstallation";
BA_ "SystemSignalLongSymbol" SG_ 1470 IDB_a014_wheelSpeedSensorWrongEx "IDB_a014_wheelSpeedSensorWrongExciter";
BA_ "SystemSignalLongSymbol" SG_ 1470 IDB_a014_wheelSpeedSensorSpeedJu "IDB_a014_wheelSpeedSensorSpeedJumpMinus";
BA_ "SystemSignalLongSymbol" SG_ 1470 IDB_a014_wheelSpeedSensorSp_0001 "IDB_a014_wheelSpeedSensorSpeedJumpPlus";
BA_ "SystemSignalLongSymbol" SG_ 1470 IDB_a014_wheelSpeedSensorLeakage "IDB_a014_wheelSpeedSensorLeakageCur";
BA_ "SystemSignalLongSymbol" SG_ 1470 IDB_a014_wheelSpeedSensorOverTem "IDB_a014_wheelSpeedSensorOverTemp";
BA_ "SystemSignalLongSymbol" SG_ 1470 IDB_a014_wheelSpeedSensorSh_0001 "IDB_a014_wheelSpeedSensorShortToGnd";
BA_ "SystemSignalLongSymbol" SG_ 1470 IDB_a014_wheelSpeedSensorShortTo "IDB_a014_wheelSpeedSensorShortToBat";
BA_ "SystemSignalLongSymbol" SG_ 1470 IDB_a015_wheelSpeedSensorMisinst "IDB_a015_wheelSpeedSensorMisinstallation";
BA_ "SystemSignalLongSymbol" SG_ 1470 IDB_a015_wheelSpeedSensorWrongEx "IDB_a015_wheelSpeedSensorWrongExciter";
BA_ "SystemSignalLongSymbol" SG_ 1470 IDB_a015_wheelSpeedSensorSpeedJu "IDB_a015_wheelSpeedSensorSpeedJumpMinus";
BA_ "SystemSignalLongSymbol" SG_ 1470 IDB_a015_wheelSpeedSensorSp_0001 "IDB_a015_wheelSpeedSensorSpeedJumpPlus";
BA_ "SystemSignalLongSymbol" SG_ 1470 IDB_a015_wheelSpeedSensorLeakage "IDB_a015_wheelSpeedSensorLeakageCur";
BA_ "SystemSignalLongSymbol" SG_ 1470 IDB_a015_wheelSpeedSensorOverTem "IDB_a015_wheelSpeedSensorOverTemp";
BA_ "SystemSignalLongSymbol" SG_ 1470 IDB_a015_wheelSpeedSensorSh_0001 "IDB_a015_wheelSpeedSensorShortToGnd";
BA_ "SystemSignalLongSymbol" SG_ 1470 IDB_a015_wheelSpeedSensorShortTo "IDB_a015_wheelSpeedSensorShortToBat";
BA_ "SystemSignalLongSymbol" SG_ 1470 IDB_a016_wheelSpeedSensorMisinst "IDB_a016_wheelSpeedSensorMisinstallation";
BA_ "SystemSignalLongSymbol" SG_ 1470 IDB_a016_wheelSpeedSensorWrongEx "IDB_a016_wheelSpeedSensorWrongExciter";
BA_ "SystemSignalLongSymbol" SG_ 1470 IDB_a016_wheelSpeedSensorSpeedJu "IDB_a016_wheelSpeedSensorSpeedJumpMinus";
BA_ "SystemSignalLongSymbol" SG_ 1470 IDB_a016_wheelSpeedSensorSp_0001 "IDB_a016_wheelSpeedSensorSpeedJumpPlus";
BA_ "SystemSignalLongSymbol" SG_ 1470 IDB_a016_wheelSpeedSensorLeakage "IDB_a016_wheelSpeedSensorLeakageCur";
BA_ "SystemSignalLongSymbol" SG_ 1470 IDB_a016_wheelSpeedSensorOverTem "IDB_a016_wheelSpeedSensorOverTemp";
BA_ "SystemSignalLongSymbol" SG_ 1470 IDB_a016_wheelSpeedSensorSh_0001 "IDB_a016_wheelSpeedSensorShortToGnd";
BA_ "SystemSignalLongSymbol" SG_ 1470 IDB_a016_wheelSpeedSensorShortTo "IDB_a016_wheelSpeedSensorShortToBat";
BA_ "SystemSignalLongSymbol" SG_ 1470 IDB_a017_wheelSpeedSensorMisinst "IDB_a017_wheelSpeedSensorMisinstallation";
BA_ "SystemSignalLongSymbol" SG_ 1470 IDB_a017_wheelSpeedSensorWrongEx "IDB_a017_wheelSpeedSensorWrongExciter";
BA_ "SystemSignalLongSymbol" SG_ 1470 IDB_a017_wheelSpeedSensorSpeedJu "IDB_a017_wheelSpeedSensorSpeedJumpMinus";
BA_ "SystemSignalLongSymbol" SG_ 1470 IDB_a017_wheelSpeedSensorSp_0001 "IDB_a017_wheelSpeedSensorSpeedJumpPlus";
BA_ "SystemSignalLongSymbol" SG_ 1470 IDB_a017_wheelSpeedSensorLeakage "IDB_a017_wheelSpeedSensorLeakageCur";
BA_ "SystemSignalLongSymbol" SG_ 1470 IDB_a017_wheelSpeedSensorOverTem "IDB_a017_wheelSpeedSensorOverTemp";
BA_ "SystemSignalLongSymbol" SG_ 1470 IDB_a017_wheelSpeedSensorSh_0001 "IDB_a017_wheelSpeedSensorShortToGnd";
BA_ "SystemSignalLongSymbol" SG_ 1470 IDB_a017_wheelSpeedSensorShortTo "IDB_a017_wheelSpeedSensorShortToBat";
BA_ "SystemSignalLongSymbol" SG_ 1470 IDB_a030_primaryExternalCircuitL "IDB_a030_primaryExternalCircuitLeakage";
BA_ "SystemSignalLongSymbol" SG_ 1470 IDB_a030_secondaryExternalCircui "IDB_a030_secondaryExternalCircuitLeakage";
BA_ "SystemSignalLongSymbol" SG_ 1470 IDB_a030_primaryChamberInternalL "IDB_a030_primaryChamberInternalLeakage";
BA_ "SystemSignalLongSymbol" SG_ 1470 IDB_a030_secondaryChamberInterna "IDB_a030_secondaryChamberInternalLeakage";
BA_ "SystemSignalLongSymbol" SG_ 1470 IDB_a030_masterCylinderInternalL "IDB_a030_masterCylinderInternalLeakage";
BA_ "SystemSignalLongSymbol" SG_ 1470 IDB_a126_DIchassisControlValidit "IDB_a126_DIchassisControlValidity";
BA_ "SystemSignalLongSymbol" SG_ 1470 IDB_a130_PMbrakePedalCmdQFValidi "IDB_a130_PMbrakePedalCmdQFValidity";
BA_ "SystemSignalLongSymbol" SG_ 1470 IDB_a130_DIbrakeTorqueCommandFul "IDB_a130_DIbrakeTorqueCommandFullSNA";
BA_ "SystemSignalLongSymbol" SG_ 1470 IDB_a130_DIbrakeTorqueComma_0001 "IDB_a130_DIbrakeTorqueCommandFullTooLow";
BA_ "SystemSignalLongSymbol" SG_ 983 IDB_a070_DIchassisControlChecksu "IDB_a070_DIchassisControlChecksum";
BA_ "SystemSignalLongSymbol" SG_ 983 IDB_a119_VCLEFTepbmStatusChecksu "IDB_a119_VCLEFTepbmStatusChecksum";
BA_ "SystemSignalLongSymbol" SG_ 983 IDB_a129_RCUinputRodStrokeInvali "IDB_a129_RCUinputRodStrokeInvalid";
BA_ "SystemSignalLongSymbol" SG_ 983 IDB_a130_DIfullTorqueRequestInva "IDB_a130_DIfullTorqueRequestInvalid";
BA_ "SystemSignalLongSymbol" SG_ 983 IDB_a132_RCUinputRodStrokeQFInva "IDB_a132_RCUinputRodStrokeQFInvalid";
BA_ "SystemSignalLongSymbol" SG_ 983 IDB_a138_DIbrakeTorqueCommandAnd "IDB_a138_DIbrakeTorqueCommandAndFlagMismatch";
BA_ "SystemSignalLongSymbol" SG_ 983 IDB_a139_DIbrakeTorqueCommandFul "IDB_a139_DIbrakeTorqueCommandFullSNA";
BA_ "SystemSignalLongSymbol" SG_ 983 IDB_a140_PMbrakePedalCmdQFInvali "IDB_a140_PMbrakePedalCmdQFInvalid";
BA_ "SystemSignalLongSymbol" SG_ 983 IDB_a141_DIbrakeTorqueCommandFul "IDB_a141_DIbrakeTorqueCommandFullTooLow";
BA_ "SystemSignalLongSymbol" SG_ 983 IDB_a144_hydraulicPushthroughAct "IDB_a144_hydraulicPushthroughActive";
BA_ "SystemSignalLongSymbol" SG_ 983 IDB_a145_DASredundantBrakingCont "IDB_a145_DASredundantBrakingControlDLC";
BA_ "SystemSignalLongSymbol" SG_ 983 IDB_a146_DASredundantBrakingCont "IDB_a146_DASredundantBrakingControlCounter";
BA_ "SystemSignalLongSymbol" SG_ 983 IDB_a147_DASredundantBrakingCont "IDB_a147_DASredundantBrakingControlChecksum";
BA_ "SystemSignalLongSymbol" SG_ 983 IDB_a148_DASbrakeTorqueCommandIn "IDB_a148_DASbrakeTorqueCommandInvalid";
BA_ "SystemSignalLongSymbol" SG_ 983 IDB_a149_DASmiaBrakeTorqueComman "IDB_a149_DASmiaBrakeTorqueCommandInvalid";
BA_ "SystemSignalLongSymbol" SG_ 1012 LS_lightLeftRampedChannel1Reques "LS_lightLeftRampedChannel1Request";
BA_ "Confidence" SG_ 1012 LS_lightLeftRampedChannel1Durati 1;
BA_ "SystemSignalLongSymbol" SG_ 1012 LS_lightLeftRampedChannel1Durati "LS_lightLeftRampedChannel1Duration";
BA_ "SystemSignalLongSymbol" SG_ 1012 LS_lightLeftRampedChannel2Reques "LS_lightLeftRampedChannel2Request";
BA_ "Confidence" SG_ 1012 LS_lightLeftRampedChannel2Durati 1;
BA_ "SystemSignalLongSymbol" SG_ 1012 LS_lightLeftRampedChannel2Durati "LS_lightLeftRampedChannel2Duration";
BA_ "SystemSignalLongSymbol" SG_ 1012 LS_lightLeftRampedChannel3Reques "LS_lightLeftRampedChannel3Request";
BA_ "Confidence" SG_ 1012 LS_lightLeftRampedChannel3Durati 1;
BA_ "SystemSignalLongSymbol" SG_ 1012 LS_lightLeftRampedChannel3Durati "LS_lightLeftRampedChannel3Duration";
BA_ "SystemSignalLongSymbol" SG_ 1012 LS_lightLeftRampedChannel4Reques "LS_lightLeftRampedChannel4Request";
BA_ "Confidence" SG_ 1012 LS_lightLeftRampedChannel4Durati 1;
BA_ "SystemSignalLongSymbol" SG_ 1012 LS_lightLeftRampedChannel4Durati "LS_lightLeftRampedChannel4Duration";
BA_ "SystemSignalLongSymbol" SG_ 1012 LS_lightLeftRampedChannel5Reques "LS_lightLeftRampedChannel5Request";
BA_ "Confidence" SG_ 1012 LS_lightLeftRampedChannel5Durati 1;
BA_ "SystemSignalLongSymbol" SG_ 1012 LS_lightLeftRampedChannel5Durati "LS_lightLeftRampedChannel5Duration";
BA_ "SystemSignalLongSymbol" SG_ 1012 LS_lightLeftRampedChannel6Reques "LS_lightLeftRampedChannel6Request";
BA_ "Confidence" SG_ 1012 LS_lightLeftRampedChannel6Durati 1;
BA_ "SystemSignalLongSymbol" SG_ 1012 LS_lightLeftRampedChannel6Durati "LS_lightLeftRampedChannel6Duration";
BA_ "SystemSignalLongSymbol" SG_ 1012 LS_lightLeftRampedChannel7Reques "LS_lightLeftRampedChannel7Request";
BA_ "Confidence" SG_ 1012 LS_lightLeftRampedChannel7Durati 1;
BA_ "SystemSignalLongSymbol" SG_ 1012 LS_lightLeftRampedChannel7Durati "LS_lightLeftRampedChannel7Duration";
BA_ "SystemSignalLongSymbol" SG_ 1012 LS_lightRightRampedChannel1Reque "LS_lightRightRampedChannel1Request";
BA_ "Confidence" SG_ 1012 LS_lightRightRampedChannel1Durat 1;
BA_ "SystemSignalLongSymbol" SG_ 1012 LS_lightRightRampedChannel1Durat "LS_lightRightRampedChannel1Duration";
BA_ "SystemSignalLongSymbol" SG_ 1012 LS_lightRightRampedChannel2Reque "LS_lightRightRampedChannel2Request";
BA_ "Confidence" SG_ 1012 LS_lightRightRampedChannel2Durat 1;
BA_ "SystemSignalLongSymbol" SG_ 1012 LS_lightRightRampedChannel2Durat "LS_lightRightRampedChannel2Duration";
BA_ "SystemSignalLongSymbol" SG_ 1012 LS_lightRightRampedChannel3Reque "LS_lightRightRampedChannel3Request";
BA_ "Confidence" SG_ 1012 LS_lightRightRampedChannel3Durat 1;
BA_ "SystemSignalLongSymbol" SG_ 1012 LS_lightRightRampedChannel3Durat "LS_lightRightRampedChannel3Duration";
BA_ "SystemSignalLongSymbol" SG_ 1012 LS_lightRightRampedChannel4Reque "LS_lightRightRampedChannel4Request";
BA_ "Confidence" SG_ 1012 LS_lightRightRampedChannel4Durat 1;
BA_ "SystemSignalLongSymbol" SG_ 1012 LS_lightRightRampedChannel4Durat "LS_lightRightRampedChannel4Duration";
BA_ "SystemSignalLongSymbol" SG_ 1012 LS_lightRightRampedChannel5Reque "LS_lightRightRampedChannel5Request";
BA_ "Confidence" SG_ 1012 LS_lightRightRampedChannel5Durat 1;
BA_ "SystemSignalLongSymbol" SG_ 1012 LS_lightRightRampedChannel5Durat "LS_lightRightRampedChannel5Duration";
BA_ "SystemSignalLongSymbol" SG_ 1012 LS_lightRightRampedChannel6Reque "LS_lightRightRampedChannel6Request";
BA_ "Confidence" SG_ 1012 LS_lightRightRampedChannel6Durat 1;
BA_ "SystemSignalLongSymbol" SG_ 1012 LS_lightRightRampedChannel6Durat "LS_lightRightRampedChannel6Duration";
BA_ "SystemSignalLongSymbol" SG_ 1012 LS_lightRightRampedChannel7Reque "LS_lightRightRampedChannel7Request";
BA_ "Confidence" SG_ 1012 LS_lightRightRampedChannel7Durat 1;
BA_ "SystemSignalLongSymbol" SG_ 1012 LS_lightRightRampedChannel7Durat "LS_lightRightRampedChannel7Duration";
BA_ "Confidence" SG_ 1012 LS_mirrorRequestLeft 1;
BA_ "Confidence" SG_ 1012 LS_mirrorRequestRight 1;
BA_ "Confidence" SG_ 1012 LS_liftgateRequest 1;
BA_ "Confidence" SG_ 1012 LS_windowRequestLF 1;
BA_ "Confidence" SG_ 1012 LS_windowRequestLR 1;
BA_ "Confidence" SG_ 1012 LS_windowRequestRF 1;
BA_ "Confidence" SG_ 1012 LS_windowRequestRR 1;
BA_ "Confidence" SG_ 1012 LS_presentingHandleRequestLF 1;
BA_ "Confidence" SG_ 1012 LS_presentingHandleRequestLR 1;
BA_ "Confidence" SG_ 1012 LS_presentingHandleRequestRF 1;
BA_ "Confidence" SG_ 1012 LS_presentingHandleRequestRR 1;
BA_ "Confidence" SG_ 1012 LS_powerFrontDoorRequestLeft 1;
BA_ "Confidence" SG_ 1012 LS_powerFrontDoorRequestRight 1;
BA_ "Confidence" SG_ 1012 LS_falconDoorRequestLeft 1;
BA_ "Confidence" SG_ 1012 LS_falconDoorRequestRight 1;
BA_ "Confidence" SG_ 1012 LS_chargePortRequest 1;
BA_ "Confidence" SG_ 1012 LS_suspensionRequest 1;
BA_ "SystemSignalLongSymbol" SG_ 767 OCS1P_w148_classificationMismatc "OCS1P_w148_classificationMismatch";
BA_ "SystemSignalLongSymbol" SG_ 767 OCS1P_w156_seatbeltReminderUnava "OCS1P_w156_seatbeltReminderUnavailable";
BA_ "Confidence" SG_ 766 OCS1P_infoBuildType 1;
BA_ "Confidence" SG_ 771 OCS1P_occupantClassification 1;
BA_ "Confidence" SG_ 771 OCS1P_occupantClassificationQF 1;
BA_ "Confidence" SG_ 771 OCS1P_occupiedState 1;
BA_ "Confidence" SG_ 771 OCS1P_triggerSnapshot 1;
BA_ "Confidence" SG_ 771 OCS1P_occupantClassificationRaw 1;
BA_ "Confidence" SG_ 771 OCS1P_occupantClassificationSelf 1;
BA_ "Confidence" SG_ 771 OCS1P_occupantClassificationRawC 1;
BA_ "SystemSignalLongSymbol" SG_ 771 OCS1P_occupantClassificationRawC "OCS1P_occupantClassificationRawCap";
BA_ "Confidence" SG_ 771 OCS1P_occupantClassificationCap 1;
BA_ "Confidence" SG_ 771 OCS1P_classificationHeld 1;
BA_ "Confidence" SG_ 771 OCS1P_cushionStable 1;
BA_ "Confidence" SG_ 771 OCS1P_classificationExtHold 1;
BA_ "Confidence" SG_ 771 OCS1P_classificationHoldState 1;
BA_ "Confidence" SG_ 771 OCS1P_classificationVariant 1;
BA_ "Confidence" SG_ 771 OCS1P_sandwichDisabled 1;
BA_ "Confidence" SG_ 771 OCS1P_noSandwichType 1;
BA_ "Confidence" SG_ 771 OCS1P_sandwichBoundaryType 1;
BA_ "Confidence" SG_ 771 OCS1P_sbrBoundaryType 1;
BA_ "Confidence" SG_ 771 OCS1P_occupiedStateCap 1;
BA_ "Confidence" SG_ 771 OCS1P_seatbackStable 1;
BA_ "Confidence" SG_ 771 OCS1P_sandwichStable 1;
VAL_ 813 IBST_infoBuildType 4 "INFO_MFG_BUILD" 3 "INFO_TRACEABLE_CI_BUILD" 2 "INFO_LOCAL_BUILD" 1 "INFO_PLATFORM_BUILD" 0 "INFO_UNKNOWN_BUILD" ;
VAL_ 925 IBST_iBoosterStatus 6 "IBOOSTER_ACTUATION" 5 "IBOOSTER_READY" 4 "IBOOSTER_ACTIVE_GOOD_CHECK" 3 "IBOOSTER_DIAGNOSTIC" 2 "IBOOSTER_FAILURE" 1 "IBOOSTER_INIT" 0 "IBOOSTER_OFF" ;
VAL_ 925 IBST_driverBrakeApply 3 "FAULT" 2 "DRIVER_APPLYING_BRAKES" 1 "BRAKES_NOT_APPLIED" 0 "NOT_INIT_OR_OFF" ;
VAL_ 925 IBST_internalState 6 "POST_DRIVE_CHECK" 5 "TRANSITION_TO_IDLE" 4 "DIAGNOSTIC" 3 "EXTERNAL_BRAKE_REQUEST" 2 "LOCAL_BRAKE_REQUEST" 1 "PRE_DRIVE_CHECK" 0 "NO_MODE_ACTIVE" ;
VAL_ 925 IBST_LVPowerModeState 3 "PEAK_POWER_REDUCTION_RESERVED" 2 "PEAK_POWER_REDUCTION_ACTIVE_MAX600W_NOMINAL350W" 1 "PEAK_POWER_REDUCTION_AVAILABLE" 0 "PEAK_POWER_REDUCTION_NOT_SUPPORTED" ;
VAL_ 941 ICR_infoBuildType 4 "INFO_MFG_BUILD" 3 "INFO_TRACEABLE_CI_BUILD" 2 "INFO_LOCAL_BUILD" 1 "INFO_PLATFORM_BUILD" 0 "INFO_UNKNOWN_BUILD" ;
VAL_ 667 ICR_lifePresenceRaw 2 "LIFE_DETECTED" 1 "LIFE_NOT_DETECTED" 0 "LIFE_DETECTED_SNA" ;
VAL_ 667 ICR_lifePresenceFilt 2 "LIFE_DETECTED" 1 "LIFE_NOT_DETECTED" 0 "LIFE_DETECTED_SNA" ;
VAL_ 667 ICR_largeOccupantPresenceRaw 3 "SBRStatus_SEAT_SNA" 2 "SBRStatus_SEAT_FAULTED" 1 "SBRStatus_SEAT_OCCUPIED" 0 "SBRStatus_SEAT_UNOCCUPIED" ;
VAL_ 667 ICR_largeOccupantPresenceFilt 3 "SBRStatus_SEAT_SNA" 2 "SBRStatus_SEAT_FAULTED" 1 "SBRStatus_SEAT_OCCUPIED" 0 "SBRStatus_SEAT_UNOCCUPIED" ;
VAL_ 667 ICR_childPresenceFunctionality 2 "CHILD_PRESENCE_SNA" 1 "CHILD_PRESENCE_ENABLED" 0 "CHILD_PRESENCE_DISABLED" ;
VAL_ 667 ICR_userPresenceFunctionality 2 "CHILD_PRESENCE_SNA" 1 "CHILD_PRESENCE_ENABLED" 0 "CHILD_PRESENCE_DISABLED" ;
VAL_ 667 ICR_userPresenceRaw 3 "SBRStatus_SEAT_SNA" 2 "SBRStatus_SEAT_FAULTED" 1 "SBRStatus_SEAT_OCCUPIED" 0 "SBRStatus_SEAT_UNOCCUPIED" ;
VAL_ 667 ICR_userPresenceFilt 3 "SBRStatus_SEAT_SNA" 2 "SBRStatus_SEAT_FAULTED" 1 "SBRStatus_SEAT_OCCUPIED" 0 "SBRStatus_SEAT_UNOCCUPIED" ;
VAL_ 2027 ICR_occupancy1LRaw 3 "SBRStatus_SEAT_SNA" 2 "SBRStatus_SEAT_FAULTED" 1 "SBRStatus_SEAT_OCCUPIED" 0 "SBRStatus_SEAT_UNOCCUPIED" ;
VAL_ 2027 ICR_occupancy1RRaw 3 "SBRStatus_SEAT_SNA" 2 "SBRStatus_SEAT_FAULTED" 1 "SBRStatus_SEAT_OCCUPIED" 0 "SBRStatus_SEAT_UNOCCUPIED" ;
VAL_ 2027 ICR_occupancy1LFilt 3 "SBRStatus_SEAT_SNA" 2 "SBRStatus_SEAT_FAULTED" 1 "SBRStatus_SEAT_OCCUPIED" 0 "SBRStatus_SEAT_UNOCCUPIED" ;
VAL_ 2027 ICR_occupancy1RFilt 3 "SBRStatus_SEAT_SNA" 2 "SBRStatus_SEAT_FAULTED" 1 "SBRStatus_SEAT_OCCUPIED" 0 "SBRStatus_SEAT_UNOCCUPIED" ;
VAL_ 2027 ICR_occupancy2LFilt 3 "SBRStatus_SEAT_SNA" 2 "SBRStatus_SEAT_FAULTED" 1 "SBRStatus_SEAT_OCCUPIED" 0 "SBRStatus_SEAT_UNOCCUPIED" ;
VAL_ 2027 ICR_occupancy2CFilt 3 "SBRStatus_SEAT_SNA" 2 "SBRStatus_SEAT_FAULTED" 1 "SBRStatus_SEAT_OCCUPIED" 0 "SBRStatus_SEAT_UNOCCUPIED" ;
VAL_ 2027 ICR_occupancy2RFilt 3 "SBRStatus_SEAT_SNA" 2 "SBRStatus_SEAT_FAULTED" 1 "SBRStatus_SEAT_OCCUPIED" 0 "SBRStatus_SEAT_UNOCCUPIED" ;
VAL_ 2027 ICR_occupancy1RFiltExp 3 "SBRStatus_SEAT_SNA" 2 "SBRStatus_SEAT_FAULTED" 1 "SBRStatus_SEAT_OCCUPIED" 0 "SBRStatus_SEAT_UNOCCUPIED" ;
VAL_ 670 ICR_classification1RFilt 4 "OCCUPANT_CLASSIFICATION_OCCUPIED_ALLOW" 3 "OCCUPANT_CLASSIFICATION_OCCUPIED_INHIBIT" 2 "OCCUPANT_CLASSIFICATION_EMPTY" 1 "OCCUPANT_CLASSIFICATION_INIT" 0 "OCCUPANT_CLASSIFICATION_SNA" ;
VAL_ 670 ICR_classification1LRaw 4 "OCCUPANT_CLASSIFICATION_OCCUPIED_ALLOW" 3 "OCCUPANT_CLASSIFICATION_OCCUPIED_INHIBIT" 2 "OCCUPANT_CLASSIFICATION_EMPTY" 1 "OCCUPANT_CLASSIFICATION_INIT" 0 "OCCUPANT_CLASSIFICATION_SNA" ;
VAL_ 670 ICR_classification1RRaw 4 "OCCUPANT_CLASSIFICATION_OCCUPIED_ALLOW" 3 "OCCUPANT_CLASSIFICATION_OCCUPIED_INHIBIT" 2 "OCCUPANT_CLASSIFICATION_EMPTY" 1 "OCCUPANT_CLASSIFICATION_INIT" 0 "OCCUPANT_CLASSIFICATION_SNA" ;
VAL_ 670 ICR_classification1LqF 1 "OCCUPANT_CLASSIFICATION_NOT_FAULTED" 0 "OCCUPANT_CLASSIFICATION_FAULTED" ;
VAL_ 670 ICR_classification1LFilt 4 "OCCUPANT_CLASSIFICATION_OCCUPIED_ALLOW" 3 "OCCUPANT_CLASSIFICATION_OCCUPIED_INHIBIT" 2 "OCCUPANT_CLASSIFICATION_EMPTY" 1 "OCCUPANT_CLASSIFICATION_INIT" 0 "OCCUPANT_CLASSIFICATION_SNA" ;
VAL_ 670 ICR_classification1RqF 1 "OCCUPANT_CLASSIFICATION_NOT_FAULTED" 0 "OCCUPANT_CLASSIFICATION_FAULTED" ;
VAL_ 670 ICR_classification1LLatched 4 "OCCUPANT_CLASSIFICATION_OCCUPIED_ALLOW" 3 "OCCUPANT_CLASSIFICATION_OCCUPIED_INHIBIT" 2 "OCCUPANT_CLASSIFICATION_EMPTY" 1 "OCCUPANT_CLASSIFICATION_INIT" 0 "OCCUPANT_CLASSIFICATION_SNA" ;
VAL_ 670 ICR_classification1RLatched 4 "OCCUPANT_CLASSIFICATION_OCCUPIED_ALLOW" 3 "OCCUPANT_CLASSIFICATION_OCCUPIED_INHIBIT" 2 "OCCUPANT_CLASSIFICATION_EMPTY" 1 "OCCUPANT_CLASSIFICATION_INIT" 0 "OCCUPANT_CLASSIFICATION_SNA" ;
VAL_ 2025 ICR_sensorMode 15 "ICR_SENSOR_INTERFACE_MODE_ERROR" 7 "ICR_SENSOR_INTERFACE_MODE_LPM_TEST" 6 "ICR_SENSOR_INTERFACE_MODE_OCCUPANCY_DETECTION" 5 "ICR_SENSOR_INTERFACE_MODE_HPM_TEST" 4 "ICR_SENSOR_INTERFACE_MODE_CALIBRATION" 3 "ICR_SENSOR_INTERFACE_MODE_CW" 2 "ICR_SENSOR_MODE_END_OF_LINE_TEST" 1 "ICR_SENSOR_MODE_INTRUSTION" 0 "ICR_SENSOR_MODE_SENSOR_STOPPED" ;
VAL_ 2025 ICR_blocked 2 "ICR_BLOCKED_TRUE" 1 "ICR_BLOCKED_FALSE" 0 "ICR_BLOCKED_SNA" ;
VAL_ 2025 ICR_algoVersion 37 "ICR_ALGO_VERSION_FUTURE_RELEASE_37" 36 "ICR_ALGO_VERSION_v06112025" 35 "ICR_ALGO_VERSION_v04232025" 34 "ICR_ALGO_VERSION_v03192025" 33 "ICR_ALGO_VERSION_v02142025" 32 "ICR_ALGO_VERSION_v01222025" 31 "ICR_ALGO_VERSION_v10072024" 30 "ICR_ALGO_VERSION_v08282024" 29 "ICR_ALGO_VERSION_v07172024" 28 "ICR_ALGO_VERSION_v06122024" 27 "ICR_ALGO_VERSION_v04242024" 26 "ICR_ALGO_VERSION_v03142024" 25 "ICR_ALGO_VERSION_v01312024" 24 "ICR_ALGO_VERSION_v12192023" 23 "ICR_ALGO_VERSION_v10252023" 22 "ICR_ALGO_VERSION_v10112023" 21 "ICR_ALGO_VERSION_v09222023" 20 "ICR_ALGO_VERSION_V08302023" 19 "ICR_ALGO_VERSION_V07172023" 18 "ICR_ALGO_VERSION_V06152023" 17 "ICR_ALGO_VERSION_V06072023" 16 "ICR_ALGO_VERSION_V05192023" 15 "ICR_ALGO_VERSION_V04262023" 14 "ICR_ALGO_VERSION_V1222" 13 "ICR_ALGO_VERSION_V1125" 12 "ICR_ALGO_VERSION_V1118" 11 "ICR_ALGO_VERSION_V1103" 10 "ICR_ALGO_VERSION_V1013" 9 "ICR_ALGO_VERSION_V1006" 8 "ICR_ALGO_VERSION_V927" 7 "ICR_ALGO_VERSION_V902" 6 "ICR_ALGO_VERSION_V826" 5 "ICR_ALGO_VERSION_V803" 4 "ICR_ALGO_VERSION_V715" 3 "ICR_ALGO_VERSION_V711" 2 "ICR_ALGO_VERSION_V204" 1 "ICR_ALGO_VERSION_EXPERIMENTAL" 0 "ICR_ALGO_VERSION_NONE" ;
VAL_ 2025 ICR_intrusionStatus 2 "INSTRUSION_STATUS_INTRUSION_DETECTED" 1 "INSTRUSION_STATUS_NONE" 0 "INSTRUSION_STATUS_UNKNOWN" ;
VAL_ 1012 LS_lightLeftRampedChannel1Durati 3 "TWO_SECONDS" 2 "ONE_SECOND" 1 "HALF_SECOND" 0 "INSTANT" ;
VAL_ 1012 LS_lightLeftRampedChannel2Durati 3 "TWO_SECONDS" 2 "ONE_SECOND" 1 "HALF_SECOND" 0 "INSTANT" ;
VAL_ 1012 LS_lightLeftRampedChannel3Durati 3 "TWO_SECONDS" 2 "ONE_SECOND" 1 "HALF_SECOND" 0 "INSTANT" ;
VAL_ 1012 LS_lightLeftRampedChannel4Durati 3 "TWO_SECONDS" 2 "ONE_SECOND" 1 "HALF_SECOND" 0 "INSTANT" ;
VAL_ 1012 LS_lightLeftRampedChannel5Durati 3 "TWO_SECONDS" 2 "ONE_SECOND" 1 "HALF_SECOND" 0 "INSTANT" ;
VAL_ 1012 LS_lightLeftRampedChannel6Durati 3 "TWO_SECONDS" 2 "ONE_SECOND" 1 "HALF_SECOND" 0 "INSTANT" ;
VAL_ 1012 LS_lightLeftRampedChannel7Durati 3 "TWO_SECONDS" 2 "ONE_SECOND" 1 "HALF_SECOND" 0 "INSTANT" ;
VAL_ 1012 LS_lightRightRampedChannel1Durat 3 "TWO_SECONDS" 2 "ONE_SECOND" 1 "HALF_SECOND" 0 "INSTANT" ;
VAL_ 1012 LS_lightRightRampedChannel2Durat 3 "TWO_SECONDS" 2 "ONE_SECOND" 1 "HALF_SECOND" 0 "INSTANT" ;
VAL_ 1012 LS_lightRightRampedChannel3Durat 3 "TWO_SECONDS" 2 "ONE_SECOND" 1 "HALF_SECOND" 0 "INSTANT" ;
VAL_ 1012 LS_lightRightRampedChannel4Durat 3 "TWO_SECONDS" 2 "ONE_SECOND" 1 "HALF_SECOND" 0 "INSTANT" ;
VAL_ 1012 LS_lightRightRampedChannel5Durat 3 "TWO_SECONDS" 2 "ONE_SECOND" 1 "HALF_SECOND" 0 "INSTANT" ;
VAL_ 1012 LS_lightRightRampedChannel6Durat 3 "TWO_SECONDS" 2 "ONE_SECOND" 1 "HALF_SECOND" 0 "INSTANT" ;
VAL_ 1012 LS_lightRightRampedChannel7Durat 3 "TWO_SECONDS" 2 "ONE_SECOND" 1 "HALF_SECOND" 0 "INSTANT" ;
VAL_ 1012 LS_mirrorRequestLeft 4 "HOLIDAY_PARTY_STOP" 3 "HOLIDAY_PARTY_CLOSE" 2 "HOLIDAY_PARTY_DANCE" 1 "HOLIDAY_PARTY_OPEN" 0 "HOLIDAY_PARTY_IDLE" ;
VAL_ 1012 LS_mirrorRequestRight 4 "HOLIDAY_PARTY_STOP" 3 "HOLIDAY_PARTY_CLOSE" 2 "HOLIDAY_PARTY_DANCE" 1 "HOLIDAY_PARTY_OPEN" 0 "HOLIDAY_PARTY_IDLE" ;
VAL_ 1012 LS_liftgateRequest 4 "HOLIDAY_PARTY_STOP" 3 "HOLIDAY_PARTY_CLOSE" 2 "HOLIDAY_PARTY_DANCE" 1 "HOLIDAY_PARTY_OPEN" 0 "HOLIDAY_PARTY_IDLE" ;
VAL_ 1012 LS_windowRequestLF 4 "HOLIDAY_PARTY_STOP" 3 "HOLIDAY_PARTY_CLOSE" 2 "HOLIDAY_PARTY_DANCE" 1 "HOLIDAY_PARTY_OPEN" 0 "HOLIDAY_PARTY_IDLE" ;
VAL_ 1012 LS_windowRequestLR 4 "HOLIDAY_PARTY_STOP" 3 "HOLIDAY_PARTY_CLOSE" 2 "HOLIDAY_PARTY_DANCE" 1 "HOLIDAY_PARTY_OPEN" 0 "HOLIDAY_PARTY_IDLE" ;
VAL_ 1012 LS_windowRequestRF 4 "HOLIDAY_PARTY_STOP" 3 "HOLIDAY_PARTY_CLOSE" 2 "HOLIDAY_PARTY_DANCE" 1 "HOLIDAY_PARTY_OPEN" 0 "HOLIDAY_PARTY_IDLE" ;
VAL_ 1012 LS_windowRequestRR 4 "HOLIDAY_PARTY_STOP" 3 "HOLIDAY_PARTY_CLOSE" 2 "HOLIDAY_PARTY_DANCE" 1 "HOLIDAY_PARTY_OPEN" 0 "HOLIDAY_PARTY_IDLE" ;
VAL_ 1012 LS_presentingHandleRequestLF 4 "HOLIDAY_PARTY_STOP" 3 "HOLIDAY_PARTY_CLOSE" 2 "HOLIDAY_PARTY_DANCE" 1 "HOLIDAY_PARTY_OPEN" 0 "HOLIDAY_PARTY_IDLE" ;
VAL_ 1012 LS_presentingHandleRequestLR 4 "HOLIDAY_PARTY_STOP" 3 "HOLIDAY_PARTY_CLOSE" 2 "HOLIDAY_PARTY_DANCE" 1 "HOLIDAY_PARTY_OPEN" 0 "HOLIDAY_PARTY_IDLE" ;
VAL_ 1012 LS_presentingHandleRequestRF 4 "HOLIDAY_PARTY_STOP" 3 "HOLIDAY_PARTY_CLOSE" 2 "HOLIDAY_PARTY_DANCE" 1 "HOLIDAY_PARTY_OPEN" 0 "HOLIDAY_PARTY_IDLE" ;
VAL_ 1012 LS_presentingHandleRequestRR 4 "HOLIDAY_PARTY_STOP" 3 "HOLIDAY_PARTY_CLOSE" 2 "HOLIDAY_PARTY_DANCE" 1 "HOLIDAY_PARTY_OPEN" 0 "HOLIDAY_PARTY_IDLE" ;
VAL_ 1012 LS_powerFrontDoorRequestLeft 4 "HOLIDAY_PARTY_STOP" 3 "HOLIDAY_PARTY_CLOSE" 2 "HOLIDAY_PARTY_DANCE" 1 "HOLIDAY_PARTY_OPEN" 0 "HOLIDAY_PARTY_IDLE" ;
VAL_ 1012 LS_powerFrontDoorRequestRight 4 "HOLIDAY_PARTY_STOP" 3 "HOLIDAY_PARTY_CLOSE" 2 "HOLIDAY_PARTY_DANCE" 1 "HOLIDAY_PARTY_OPEN" 0 "HOLIDAY_PARTY_IDLE" ;
VAL_ 1012 LS_falconDoorRequestLeft 4 "HOLIDAY_PARTY_STOP" 3 "HOLIDAY_PARTY_CLOSE" 2 "HOLIDAY_PARTY_DANCE" 1 "HOLIDAY_PARTY_OPEN" 0 "HOLIDAY_PARTY_IDLE" ;
VAL_ 1012 LS_falconDoorRequestRight 4 "HOLIDAY_PARTY_STOP" 3 "HOLIDAY_PARTY_CLOSE" 2 "HOLIDAY_PARTY_DANCE" 1 "HOLIDAY_PARTY_OPEN" 0 "HOLIDAY_PARTY_IDLE" ;
VAL_ 1012 LS_chargePortRequest 3 "REQUEST_SNA" 2 "REQUEST_CLOSE" 1 "REQUEST_OPEN" 0 "REQUEST_NONE" ;
VAL_ 1012 LS_suspensionRequest 3 "SUSPENSION_REQUEST_SNA" 2 "SUSPENSION_REQUEST_LOWER" 1 "SUSPENSION_REQUEST_RAISE" 0 "SUSPENSION_REQUEST_NONE" ;
VAL_ 766 OCS1P_infoBuildType 4 "INFO_MFG_BUILD" 3 "INFO_TRACEABLE_CI_BUILD" 2 "INFO_LOCAL_BUILD" 1 "INFO_PLATFORM_BUILD" 0 "INFO_UNKNOWN_BUILD" ;
VAL_ 771 OCS1P_occupantClassification 255 "OCCUPANT_CLASSIFICATION_SNA" 4 "OCCUPANT_CLASSIFICATION_INIT" 3 "OCCUPANT_CLASSIFICATION_OCCUPIED_ALLOW_LARGE" 2 "OCCUPANT_CLASSIFICATION_OCCUPIED_ALLOW_SMALL" 1 "OCCUPANT_CLASSIFICATION_OCCUPIED_INHIBIT" 0 "OCCUPANT_CLASSIFICATION_EMPTY" ;
VAL_ 771 OCS1P_occupantClassificationQF 1 "OCCUPANT_CLASSIFICATION_NOT_FAULTED" 0 "OCCUPANT_CLASSIFICATION_FAULTED" ;
VAL_ 771 OCS1P_occupiedState 3 "OCCUPIED_STATE_SNA" 1 "OCCUPIED_STATE_OCCUPIED" 0 "OCCUPIED_STATE_UNOCCUPIED" ;
VAL_ 771 OCS1P_triggerSnapshot 19 "REASON_LCB_TOO_HIGH" 18 "REASON_SWITCHED_TO_HCB" 17 "REASON_LARGE_REBASELINE" 16 "REASON_BORDERLINE_CLASSIFICATION" 15 "REASON_MISSED_EXIT_EVENT" 14 "REASON_MISSED_ENTRY_EVENT" 13 "REASON_EMPTY_CONFIDENT_EXITED" 12 "REASON_EMPTY_CONFIDENT_REBASELINED" 11 "REASON_EXIT_REBASELINED" 10 "REASON_EXIT_FAILED" 9 "REASON_EXIT_TRIGGERED" 8 "REASON_ENTRY_REBASELINED" 7 "REASON_ENTRY_FAILED" 6 "REASON_ENTRY_TRIGGERED" 5 "REASON_SENSOR_LOW_SHORT" 4 "REASON_SENSOR_OPEN" 3 "REASON_SANDWICH_LOW" 2 "REASON_REBASELINED" 1 "REASON_MISMATCH" 0 "REASON_NONE" ;
VAL_ 771 OCS1P_occupantClassificationRaw 7 "OCCUPANT_CLASSIFICATION_SNA" 4 "OCCUPANT_CLASSIFICATION_INIT" 3 "OCCUPANT_CLASSIFICATION_OCCUPIED_ALLOW_LARGE" 2 "OCCUPANT_CLASSIFICATION_OCCUPIED_ALLOW_SMALL" 1 "OCCUPANT_CLASSIFICATION_OCCUPIED_INHIBIT" 0 "OCCUPANT_CLASSIFICATION_EMPTY" ;
VAL_ 771 OCS1P_occupantClassificationSelf 7 "OCCUPANT_CLASSIFICATION_SNA" 4 "OCCUPANT_CLASSIFICATION_INIT" 3 "OCCUPANT_CLASSIFICATION_OCCUPIED_ALLOW_LARGE" 2 "OCCUPANT_CLASSIFICATION_OCCUPIED_ALLOW_SMALL" 1 "OCCUPANT_CLASSIFICATION_OCCUPIED_INHIBIT" 0 "OCCUPANT_CLASSIFICATION_EMPTY" ;
VAL_ 771 OCS1P_occupantClassificationRawC 7 "OCCUPANT_CLASSIFICATION_SNA" 4 "OCCUPANT_CLASSIFICATION_INIT" 3 "OCCUPANT_CLASSIFICATION_OCCUPIED_ALLOW_LARGE" 2 "OCCUPANT_CLASSIFICATION_OCCUPIED_ALLOW_SMALL" 1 "OCCUPANT_CLASSIFICATION_OCCUPIED_INHIBIT" 0 "OCCUPANT_CLASSIFICATION_EMPTY" ;
VAL_ 771 OCS1P_occupantClassificationCap 7 "OCCUPANT_CLASSIFICATION_SNA" 4 "OCCUPANT_CLASSIFICATION_INIT" 3 "OCCUPANT_CLASSIFICATION_OCCUPIED_ALLOW_LARGE" 2 "OCCUPANT_CLASSIFICATION_OCCUPIED_ALLOW_SMALL" 1 "OCCUPANT_CLASSIFICATION_OCCUPIED_INHIBIT" 0 "OCCUPANT_CLASSIFICATION_EMPTY" ;
VAL_ 771 OCS1P_classificationHoldState 3 "OCCUPANCY_HOLD_FAULT" 2 "OCCUPANCY_HOLD_EXTERNAL" 1 "OCCUPANCY_HOLD_BASIC" 0 "OCCUPANCY_HOLD_OFF" ;
VAL_ 771 OCS1P_classificationVariant 7 "CLASSIFICATION_VARIANT_UNKNOWN" 3 "CLASSIFICATION_VARIANT_SELF_SBR_RB" 2 "CLASSIFICATION_VARIANT_SELF_SBR" 1 "CLASSIFICATION_VARIANT_SELF_ONLY" 0 "CLASSIFICATION_VARIANT_ALL_SENSORS" ;
VAL_ 771 OCS1P_noSandwichType 3 "NO_SANDWICH_UNKNOWN" 2 "NO_SANDWICH_NA" 1 "NO_SANDWICH_EU" 0 "SANDWICH_INSTALLED" ;
VAL_ 771 OCS1P_sandwichBoundaryType 1 "SANDWICH_LRD" 0 "SANDWICH_DEFAULT" ;
VAL_ 771 OCS1P_sbrBoundaryType 1 "SBR_1669747_1763884" 0 "SBR_DEFAULT" ;
VAL_ 771 OCS1P_occupiedStateCap 3 "OCCUPIED_STATE_SNA" 1 "OCCUPIED_STATE_OCCUPIED" 0 "OCCUPIED_STATE_UNOCCUPIED" ;
